VERSION ""

NS_ :

BS_:

BU_: VCM TCM ECM EBS ACM

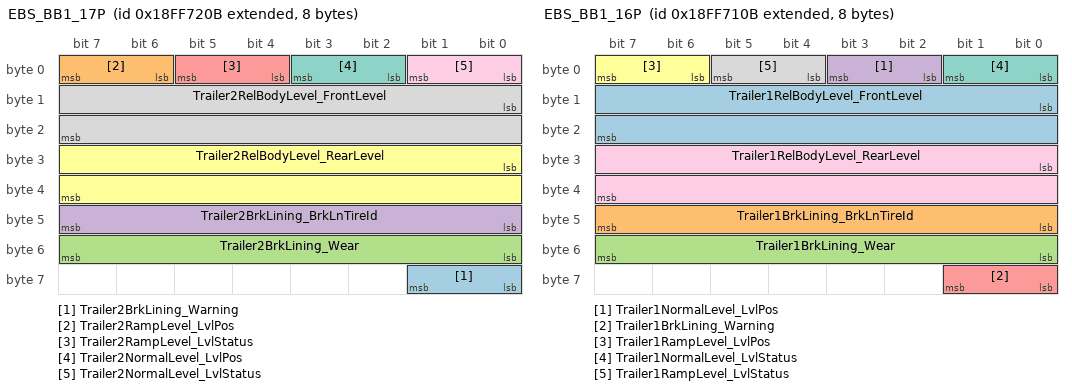
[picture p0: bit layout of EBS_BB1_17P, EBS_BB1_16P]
BO_ 2566877707 EBS_BB1_17P: 8 EBS
 SG_ Trailer2BrkLining_Warning : 56|2@1+ (1,0) [0|0] ""  VCM
 SG_ Trailer2RampLevel_LvlPos : 6|2@1+ (1,0) [0|0] ""  VCM
 SG_ Trailer2BrkLining_Wear : 48|8@1+ (0.4,0) [0|102] "Percent"  VCM
 SG_ Trailer2BrkLining_BrkLnTireId : 40|8@1+ (1,0) [0|255] "NotApplicable"  VCM
 SG_ Trailer2RampLevel_LvlStatus : 4|2@1+ (1,0) [0|0] ""  VCM
 SG_ Trailer2RelBodyLevel_RearLevel : 24|16@1+ (1,-32000) [-32000|33535] "mm"  VCM
 SG_ Trailer2NormalLevel_LvlPos : 2|2@1+ (1,0) [0|0] ""  VCM
 SG_ Trailer2RelBodyLevel_FrontLevel : 8|16@1+ (1,-32000) [-32000|33535] "mm"  VCM
 SG_ Trailer2NormalLevel_LvlStatus : 0|2@1+ (1,0) [0|0] ""  VCM

BO_ 2566877451 EBS_BB1_16P: 8 EBS
 SG_ Trailer1RelBodyLevel_FrontLevel : 8|16@1+ (1,-32000) [-32000|33535] "mm"  VCM
 SG_ Trailer1BrkLining_BrkLnTireId : 40|8@1+ (1,0) [0|255] "NotApplicable"  VCM
 SG_ Trailer1BrkLining_Wear : 48|8@1+ (0.4,0) [0|102] "Percent"  VCM
 SG_ Trailer1NormalLevel_LvlPos : 2|2@1+ (1,0) [0|0] ""  VCM
 SG_ Trailer1BrkLining_Warning : 56|2@1+ (1,0) [0|0] ""  VCM
 SG_ Trailer1RampLevel_LvlPos : 6|2@1+ (1,0) [0|0] ""  VCM
 SG_ Trailer1NormalLevel_LvlStatus : 0|2@1+ (1,0) [0|0] ""  VCM
 SG_ Trailer1RampLevel_LvlStatus : 4|2@1+ (1,0) [0|0] ""  VCM
 SG_ Trailer1RelBodyLevel_RearLevel : 24|16@1+ (1,-32000) [-32000|33535] "mm"  VCM

BO_ 2566894859 EBS_BB1_15P: 17 EBS
 SG_ Trailer5VIN : 0|136@1+ (1,0) [0|0] ""  VCM

BO_ 2566894603 EBS_BB1_14P: 17 EBS
 SG_ Trailer4VIN : 0|136@1+ (1,0) [0|0] ""  VCM

BO_ 2566894347 EBS_BB1_13P: 17 EBS
 SG_ Trailer3VIN : 0|136@1+ (1,0) [0|0] ""  VCM

BO_ 2566894091 EBS_BB1_12P: 17 EBS
 SG_ Trailer2VIN : 0|136@1+ (1,0) [0|0] ""  VCM

BO_ 2566893835 EBS_BB1_11P: 17 EBS
 SG_ Trailer1VIN : 0|136@1+ (1,0) [0|0] ""  VCM

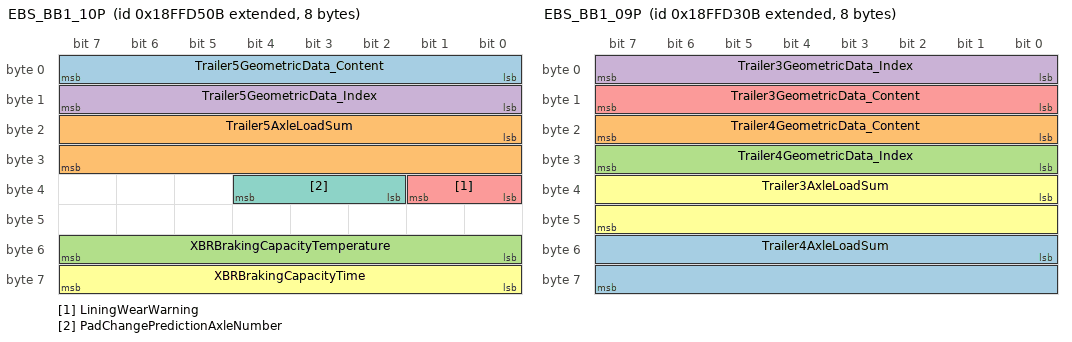
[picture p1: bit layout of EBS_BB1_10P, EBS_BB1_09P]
BO_ 2566903051 EBS_BB1_10P: 8 EBS
 SG_ Trailer5GeometricData_Content : 0|8@1+ (1,0) [0|255] ""  VCM
 SG_ Trailer5AxleLoadSum : 16|16@1+ (2,0) [0|131070] "kg"  VCM,TCM
 SG_ XBRBrakingCapacityTemperature : 48|8@1+ (0.4,0) [0|102] "Percent"  TCM,ECM,VCM
 SG_ Trailer5GeometricData_Index : 8|8@1+ (1,0) [0|0] ""  VCM
 SG_ LiningWearWarning : 32|2@1+ (1,0) [0|0] ""  VCM
 SG_ XBRBrakingCapacityTime : 56|8@1+ (1,0) [0|255] "s"  VCM,ECM,TCM
 SG_ PadChangePredictionAxleNumber : 34|3@1+ (1,0) [0|0] ""  VCM

BO_ 2566902539 EBS_BB1_09P: 8 EBS
 SG_ Trailer4AxleLoadSum : 48|16@1+ (2,0) [0|131070] "kg"  TCM,VCM
 SG_ Trailer4GeometricData_Content : 16|8@1+ (1,0) [0|255] ""  VCM
 SG_ Trailer4GeometricData_Index : 24|8@1+ (1,0) [0|0] ""  VCM
 SG_ Trailer3GeometricData_Index : 0|8@1+ (1,0) [0|0] ""  VCM
 SG_ Trailer3GeometricData_Content : 8|8@1+ (1,0) [0|255] ""  VCM
 SG_ Trailer3AxleLoadSum : 32|16@1+ (2,0) [0|131070] "kg"  VCM,TCM

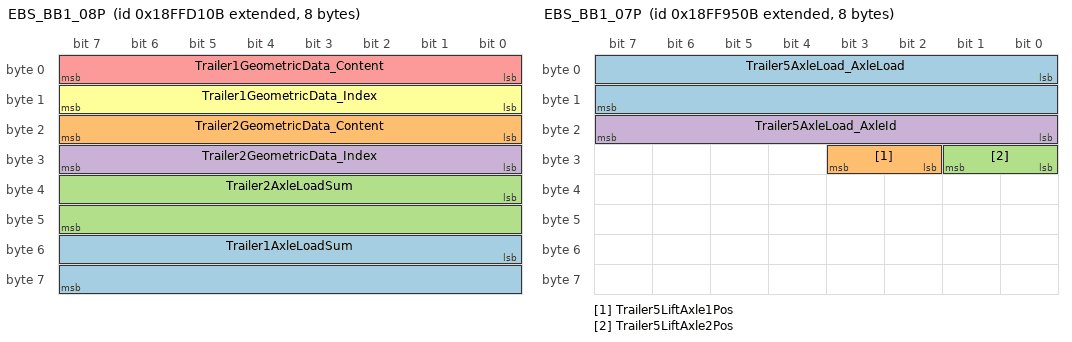
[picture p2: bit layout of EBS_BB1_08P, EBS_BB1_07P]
BO_ 2566902027 EBS_BB1_08P: 8 EBS
 SG_ Trailer1AxleLoadSum : 48|16@1+ (2,0) [0|131070] "kg"  TCM,VCM
 SG_ Trailer2GeometricData_Content : 16|8@1+ (1,0) [0|255] ""  VCM
 SG_ Trailer2AxleLoadSum : 32|16@1+ (2,0) [0|131070] "kg"  VCM,TCM
 SG_ Trailer2GeometricData_Index : 24|8@1+ (1,0) [0|0] ""  VCM
 SG_ Trailer1GeometricData_Content : 0|8@1+ (1,0) [0|255] ""  VCM
 SG_ Trailer1GeometricData_Index : 8|8@1+ (1,0) [0|0] ""  VCM

BO_ 2566886667 EBS_BB1_07P: 8 EBS
 SG_ Trailer5AxleLoad_AxleLoad : 0|16@1+ (0.5,0) [0|32767.5] "kg"  TCM,VCM
 SG_ Trailer5LiftAxle1Pos : 26|2@1+ (1,0) [0|0] ""  VCM
 SG_ Trailer5LiftAxle2Pos : 24|2@1+ (1,0) [0|0] ""  VCM
 SG_ Trailer5AxleLoad_AxleId : 16|8@1+ (1,0) [0|255] "NotApplicable"  VCM,TCM

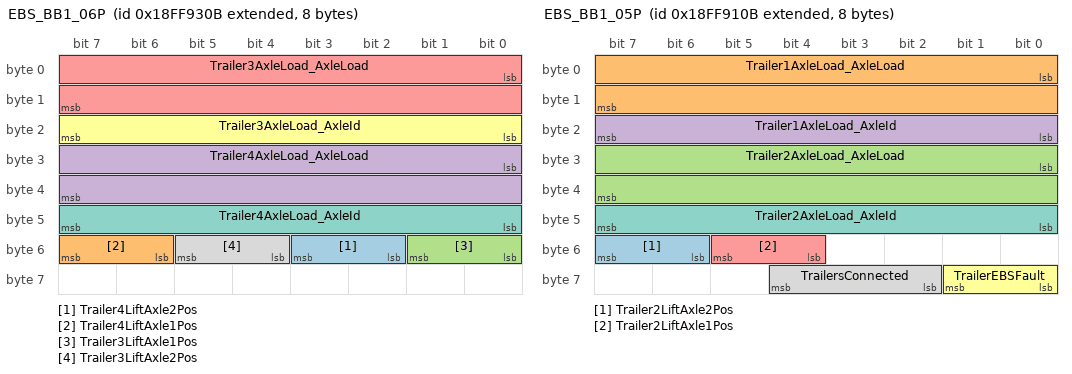
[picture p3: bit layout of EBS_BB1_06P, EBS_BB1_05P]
BO_ 2566886155 EBS_BB1_06P: 8 EBS
 SG_ Trailer4LiftAxle2Pos : 50|2@1+ (1,0) [0|0] ""  VCM
 SG_ Trailer4LiftAxle1Pos : 54|2@1+ (1,0) [0|0] ""  VCM
 SG_ Trailer3LiftAxle1Pos : 48|2@1+ (1,0) [0|0] ""  VCM
 SG_ Trailer4AxleLoad_AxleLoad : 24|16@1+ (0.5,0) [0|32767.5] "kg"  VCM,TCM
 SG_ Trailer3AxleLoad_AxleLoad : 0|16@1+ (0.5,0) [0|32767.5] "kg"  TCM,VCM
 SG_ Trailer3AxleLoad_AxleId : 16|8@1+ (1,0) [0|255] "NotApplicable"  TCM,VCM
 SG_ Trailer4AxleLoad_AxleId : 40|8@1+ (1,0) [0|255] "NotApplicable"  VCM,TCM
 SG_ Trailer3LiftAxle2Pos : 52|2@1+ (1,0) [0|0] ""  VCM

BO_ 2566885643 EBS_BB1_05P: 8 EBS
 SG_ Trailer2LiftAxle2Pos : 54|2@1+ (1,0) [0|0] ""  VCM
 SG_ Trailer1AxleLoad_AxleLoad : 0|16@1+ (0.5,0) [0|32767.5] "kg"  VCM,TCM
 SG_ Trailer2AxleLoad_AxleLoad : 24|16@1+ (0.5,0) [0|32767.5] "kg"  VCM,TCM
 SG_ Trailer1AxleLoad_AxleId : 16|8@1+ (1,0) [0|255] "NotApplicable"  VCM,TCM
 SG_ Trailer2LiftAxle1Pos : 52|2@1+ (1,0) [0|0] ""  VCM
 SG_ TrailerEBSFault : 56|2@1+ (1,0) [0|0] ""  VCM
 SG_ Trailer2AxleLoad_AxleId : 40|8@1+ (1,0) [0|255] "NotApplicable"  VCM,TCM
 SG_ TrailersConnected : 58|3@1+ (1,0) [0|7] "Count"  TCM,VCM

BO_ 2566906635 EBS_BB1_04P: 8 EBS
 SG_ PadChgPredictionLastPadChg : 32|32@1+ (1,0) [0|4294967295] "km"  VCM
 SG_ PredictedMileageOfNextPadChg : 0|32@1+ (1,0) [0|4294967295] "km"  VCM

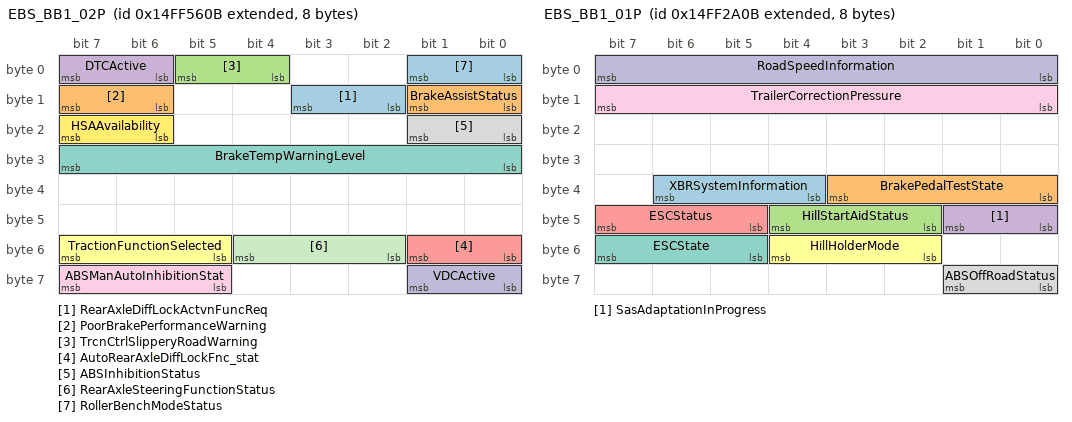
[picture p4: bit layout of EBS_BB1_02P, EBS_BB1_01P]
BO_ 2499761675 EBS_BB1_02P: 8 EBS
 SG_ RearAxleDiffLockActvnFuncReq : 10|2@1+ (1,0) [0|0] ""  VCM
 SG_ PoorBrakePerformanceWarning : 14|2@1+ (1,0) [0|0] ""  VCM
 SG_ TrcnCtrlSlipperyRoadWarning : 4|2@1+ (1,0) [0|0] ""  VCM
 SG_ DTCActive : 6|2@1+ (1,0) [0|0] ""  VCM
 SG_ AutoRearAxleDiffLockFnc_stat : 48|2@1+ (1,0) [0|0] ""  VCM
 SG_ TractionFunctionSelected : 53|3@1+ (1,0) [0|0] ""  VCM
 SG_ BrakeTempWarningLevel : 24|8@1+ (1,0) [0|255] "Percent"  VCM,ECM,TCM
 SG_ ABSInhibitionStatus : 16|2@1+ (1,0) [0|0] ""  TCM,VCM
 SG_ ABSManAutoInhibitionStat : 61|3@1+ (1,0) [0|0] ""  VCM
 SG_ VDCActive : 56|2@1+ (1,0) [0|0] ""  VCM
 SG_ RearAxleSteeringFunctionStatus : 50|3@1+ (1,0) [0|0] ""  VCM
 SG_ HSAAvailability : 22|2@1+ (1,0) [0|0] ""  TCM,VCM
 SG_ RollerBenchModeStatus : 0|2@1+ (1,0) [0|0] ""  VCM
 SG_ BrakeAssistStatus : 8|2@1+ (1,0) [0|0] ""  VCM

BO_ 2499750411 EBS_BB1_01P: 8 EBS
 SG_ XBRSystemInformation : 36|3@1+ (1,0) [0|0] ""  TCM,ECM,VCM
 SG_ BrakePedalTestState : 32|4@1+ (1,0) [0|0] ""  VCM
 SG_ HillStartAidStatus : 42|3@1+ (1,0) [0|0] ""  VCM
 SG_ SasAdaptationInProgress : 40|2@1+ (1,0) [0|0] ""  VCM
 SG_ ESCStatus : 45|3@1+ (1,0) [0|0] ""  VCM
 SG_ HillHolderMode : 50|3@1+ (1,0) [0|0] ""  TCM
 SG_ ESCState : 53|3@1+ (1,0) [0|0] ""  VCM
 SG_ ABSOffRoadStatus : 56|2@1+ (1,0) [0|0] ""  TCM,VCM
 SG_ TrailerCorrectionPressure : 8|8@1+ (0.05,-1.5) [-1.5|11.25] "Bar"  VCM
 SG_ RoadSpeedInformation : 0|8@1+ (0.805,0) [0|205.275] "Km_per_h"  VCM

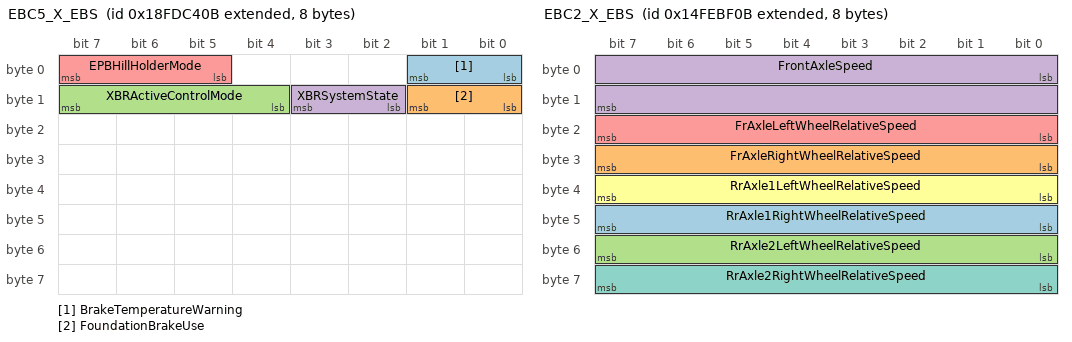
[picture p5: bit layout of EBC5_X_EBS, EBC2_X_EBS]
BO_ 2566767627 EBC5_X_EBS: 8 EBS
 SG_ BrakeTemperatureWarning : 0|2@1+ (1,0) [0|0] ""  VCM
 SG_ FoundationBrakeUse : 8|2@1+ (1,0) [0|0] ""  ECM,TCM,VCM
 SG_ XBRActiveControlMode : 12|4@1+ (1,0) [0|0] ""  TCM,ECM,VCM
 SG_ XBRSystemState : 10|2@1+ (1,0) [0|0] ""  ECM,TCM
 SG_ EPBHillHolderMode : 5|3@1+ (1,0) [0|0] ""  VCM,TCM

BO_ 2499723019 EBC2_X_EBS: 8 EBS
 SG_ RrAxle1RightWheelRelativeSpeed : 40|8@1+ (0.0625,-7.8125) [-7.8125|8.125] "Km_per_h"  TCM,VCM
 SG_ FrAxleRightWheelRelativeSpeed : 24|8@1+ (0.0625,-7.8125) [-7.8125|8.125] "Km_per_h"  VCM,TCM
 SG_ RrAxle2LeftWheelRelativeSpeed : 48|8@1+ (0.0625,-7.8125) [-7.8125|8.125] "Km_per_h"  TCM,VCM
 SG_ FrontAxleSpeed : 0|16@1+ (0.00390625,0) [0|255.99609375] "Km_per_h"  VCM,ECM,TCM
 SG_ FrAxleLeftWheelRelativeSpeed : 16|8@1+ (0.0625,-7.8125) [-7.8125|8.125] "Km_per_h"  TCM,VCM
 SG_ RrAxle1LeftWheelRelativeSpeed : 32|8@1+ (0.0625,-7.8125) [-7.8125|8.125] "Km_per_h"  TCM,VCM
 SG_ RrAxle2RightWheelRelativeSpeed : 56|8@1+ (0.0625,-7.8125) [-7.8125|8.125] "Km_per_h"  VCM,TCM

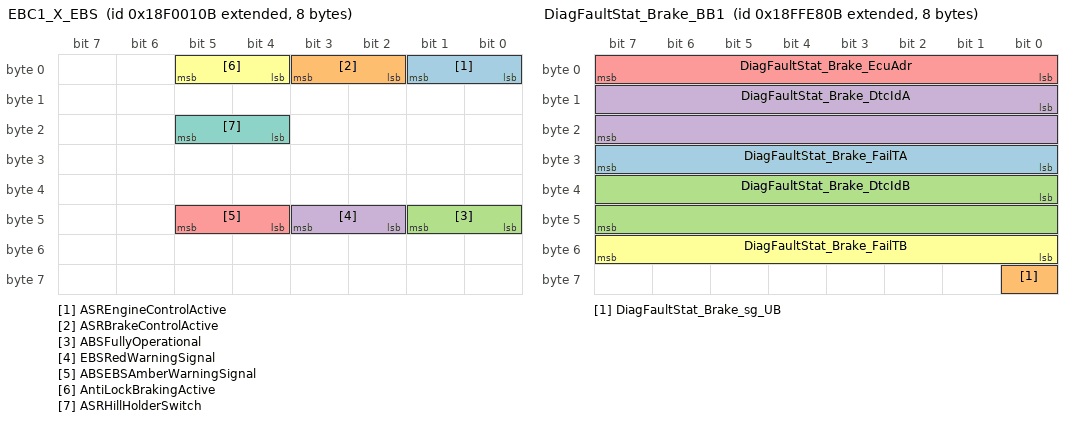
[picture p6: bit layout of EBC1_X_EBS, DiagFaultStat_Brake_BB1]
BO_ 2565865739 EBC1_X_EBS: 8 EBS
 SG_ ASREngineControlActive : 0|2@1+ (1,0) [0|0] ""  ECM,VCM,TCM
 SG_ ASRBrakeControlActive : 2|2@1+ (1,0) [0|0] ""  VCM,TCM,ECM
 SG_ ABSFullyOperational : 40|2@1+ (1,0) [0|0] ""  ECM,TCM,VCM
 SG_ EBSRedWarningSignal : 42|2@1+ (1,0) [0|0] ""  VCM
 SG_ ABSEBSAmberWarningSignal : 44|2@1+ (1,0) [0|0] ""  VCM
 SG_ AntiLockBrakingActive : 4|2@1+ (1,0) [0|0] ""  TCM,ECM
 SG_ ASRHillHolderSwitch : 20|2@1+ (1,0) [0|0] ""  ECM,VCM

BO_ 2671964712 DiagUUDTRespMsg1_F2_28_C01: 8 EBS
 SG_ DiagUUDTRespSig_F2_28 : 0|64@1+ (1,0) [0|0] ""  VCM

BO_ 2671964689 DiagUUDTRespMsg1_F2_11_C01: 8 ACM
 SG_ DiagUUDTRespSig_F2_11 : 0|64@1+ (1,0) [0|0] ""  VCM

BO_ 2671834152 DiagRespMsgForIntTest_F4_28_C01: 8 EBS
 SG_ InternalTesterDiagSig_F4_28 : 0|64@1+ (1,0) [0|0] ""  VCM

BO_ 2671834129 DiagRespMsgForIntTest_F4_11_C01: 8 ACM
 SG_ InternalTesterDiagSig_F4_11 : 0|64@1+ (1,0) [0|0] ""  VCM

BO_ 2671782132 DiagReqMsgOfIntTest_28_F4_C01: 8 VCM
 SG_ InternalTesterDiagSig_28_F4 : 0|64@1+ (1,0) [0|0] ""  EBS

BO_ 2671776244 DiagReqMsgOfIntTest_11_F4_C01: 8 VCM
 SG_ InternalTesterDiagSig_11_F4 : 0|64@1+ (1,0) [0|0] ""  ACM

BO_ 2566907915 DiagFaultStat_Brake_BB1: 8 EBS
 SG_ DiagFaultStat_Brake_FailTA : 24|8@1+ (1,0) [0|255] ""  VCM
 SG_ DiagFaultStat_Brake_sg_UB : 56|1@1+ (1,0) [0|0] ""  VCM
 SG_ DiagFaultStat_Brake_DtcIdB : 32|16@1+ (1,0) [0|65535] ""  VCM
 SG_ DiagFaultStat_Brake_DtcIdA : 8|16@1+ (1,0) [0|65535] ""  VCM
 SG_ DiagFaultStat_Brake_EcuAdr : 0|8@1+ (1,0) [0|255] ""  VCM
 SG_ DiagFaultStat_Brake_FailTB : 48|8@1+ (1,0) [0|255] ""  VCM

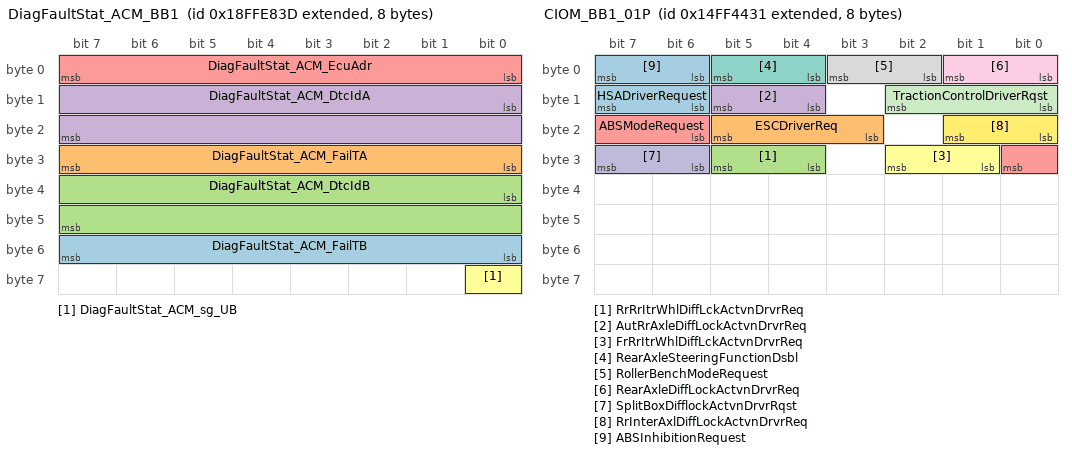
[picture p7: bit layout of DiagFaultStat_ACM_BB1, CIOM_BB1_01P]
BO_ 2566907965 DiagFaultStat_ACM_BB1: 8 ACM
 SG_ DiagFaultStat_ACM_FailTB : 48|8@1+ (1,0) [0|255] ""  VCM
 SG_ DiagFaultStat_ACM_FailTA : 24|8@1+ (1,0) [0|255] ""  VCM
 SG_ DiagFaultStat_ACM_DtcIdB : 32|16@1+ (1,0) [0|65535] ""  VCM
 SG_ DiagFaultStat_ACM_DtcIdA : 8|16@1+ (1,0) [0|65535] ""  VCM
 SG_ DiagFaultStat_ACM_EcuAdr : 0|8@1+ (1,0) [0|255] ""  VCM
 SG_ DiagFaultStat_ACM_sg_UB : 56|1@1+ (1,0) [0|0] ""  VCM

BO_ 2566749184 DPFC1_X_EMS: 8 ECM
 SG_ DPFC1_InhibDueServiceBrake : 22|2@1+ (1,0) [0|0] ""  TCM,VCM
 SG_ DPFC1_InhibVehSpdBelowAllwdSpd : 46|2@1+ (1,0) [0|0] ""  TCM,VCM
 SG_ DPFC1_ActiveRegeneratStatus : 10|2@1+ (1,0) [0|0] ""  VCM,TCM
 SG_ DPFC1_ExhaustSystHighTempLampCmd : 50|3@1+ (1,0) [0|0] ""  VCM,TCM
 SG_ DPFC1_InhibParkBrakeNotSet : 32|2@1+ (1,0) [0|0] ""  TCM,VCM
 SG_ DPFC1_InhibEnginNotWarmUp : 44|2@1+ (1,0) [0|0] ""  VCM,TCM
 SG_ DPFC1_InhibitStatus : 16|2@1+ (1,0) [0|0] ""  VCM,TCM
 SG_ DPFC1_ForcedStatus : 53|3@1+ (1,0) [0|0] ""  TCM,VCM
 SG_ DPFC1_PassiveRegenStatus : 8|2@1+ (1,0) [0|0] ""  TCM,VCM
 SG_ DPFC1_InhibTempSystemLock : 40|2@1+ (1,0) [0|0] ""  TCM,VCM
 SG_ DPFC1_InhibDueInhibSwitch : 18|2@1+ (1,0) [0|0] ""  VCM,TCM
 SG_ DPFC1_InhibPTOActive : 24|2@1+ (1,0) [0|0] ""  TCM,VCM
 SG_ DPFC1_AutoARInitConfig : 48|2@1+ (1,0) [0|0] ""  VCM,TCM
 SG_ DPFC1_InhibDueLowExhGasTemp : 34|2@1+ (1,0) [0|0] ""  VCM,TCM
 SG_ DPFC1_InhibSystemFaultAct : 36|2@1+ (1,0) [0|0] ""  VCM,TCM
 SG_ DPFC1_InhibDueSystemTimeout : 38|2@1+ (1,0) [0|0] ""  TCM,VCM
 SG_ DPFC1_InhibPermSystemLock : 42|2@1+ (1,0) [0|0] ""  TCM,VCM
 SG_ DPFC1_LampCommand : 0|3@1+ (1,0) [0|0] ""  VCM,TCM
 SG_ DPFC1_InhibVehSpdAboveAllwdSpd : 30|2@1+ (1,0) [0|0] ""  VCM,TCM
 SG_ DPFC1_InhibClutchDisengage : 20|2@1+ (1,0) [0|0] ""  VCM,TCM
 SG_ DPFC1_InhibAccPedalOffIdle : 26|2@1+ (1,0) [0|0] ""  TCM,VCM
 SG_ DPFC1_InhibOutOfNeutral : 28|2@1+ (1,0) [0|0] ""  VCM,TCM
 SG_ DPFC1_DPFStatus : 12|3@1+ (1,0) [0|0] ""  TCM,VCM

BO_ 2566834691 DM1_X_TECU: 202 TCM
 SG_ DiagnosticsFaultStat_DM1_TECU : 0|1616@1+ (1,0) [0|0] ""  VCM

BO_ 2566834688 DM1_X_EMS: 202 ECM
 SG_ DiagnosticsFaultStat_DM1_EMS : 0|1616@1+ (1,0) [0|0] ""  VCM

BO_ 2566834749 DM1_X_ACM: 202 ACM
 SG_ DiagnosticsFaultStat_DM1_ACM : 0|1616@1+ (1,0) [0|0] ""  VCM

BO_ 2566811659 CVW_X_EBS: 8 EBS
 SG_ PoweredVehicleWeight : 0|16@1+ (10,0) [0|655350] "kg"  VCM
 SG_ GrossCombinationVehicleWeight : 16|16@1+ (10,0) [0|655350] "kg"  VCM,TCM,ECM

BO_ 2499757105 CIOM_BB1_01P: 8 VCM
 SG_ HSADriverRequest : 14|2@1+ (1,0) [0|0] ""  EBS
 SG_ ESCDriverReq : 19|3@1+ (1,0) [0|0] ""  EBS
 SG_ RrRrItrWhlDiffLckActvnDrvrReq : 28|2@1+ (1,0) [0|0] ""  EBS
 SG_ AutRrAxleDiffLockActvnDrvrReq : 12|2@1+ (1,0) [0|0] ""  EBS
 SG_ ABSModeRequest : 22|3@1+ (1,0) [0|0] ""  EBS
 SG_ FrRrItrWhlDiffLckActvnDrvrReq : 25|2@1+ (1,0) [0|0] ""  EBS
 SG_ RearAxleSteeringFunctionDsbl : 4|2@1+ (1,0) [0|0] ""  EBS
 SG_ RollerBenchModeRequest : 2|2@1+ (1,0) [0|0] ""  EBS
 SG_ RearAxleDiffLockActvnDrvrReq : 0|2@1+ (1,0) [0|0] ""  EBS
 SG_ SplitBoxDifflockActvnDrvrRqst : 30|2@1+ (1,0) [0|0] ""  ECM,EBS,TCM
 SG_ TractionControlDriverRqst : 8|3@1+ (1,0) [0|0] ""  EBS
 SG_ RrInterAxlDiffLockActvnDrvrReq : 16|2@1+ (1,0) [0|0] ""  EBS
 SG_ ABSInhibitionRequest : 6|2@1+ (1,0) [0|0] ""  EBS

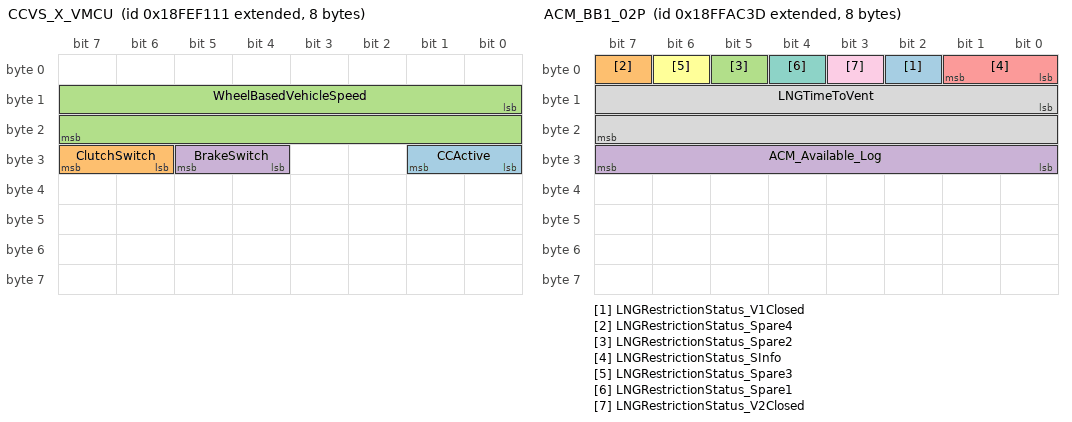
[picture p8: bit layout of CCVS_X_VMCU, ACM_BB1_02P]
BO_ 2566844689 CCVS_X_VMCU: 8 VCM
 SG_ CCActive : 24|2@1+ (1,0) [0|0] ""  TCM
 SG_ ClutchSwitch : 30|2@1+ (1,0) [0|0] ""  EBS
 SG_ WheelBasedVehicleSpeed : 8|16@1+ (0.00390625,0) [0|255.99609375] "Km_per_h"  EBS,ECM,TCM,ACM
 SG_ BrakeSwitch : 28|2@1+ (1,0) [0|0] ""  ECM,TCM

BO_ 2566748928 AT1S_X_EMS: 8 ECM
 SG_ DPFSootLevel : 0|8@1+ (1,0) [0|255] "Percent"  VCM

BO_ 2565869312 AT1OG1_X_EMS: 8 ECM
 SG_ Aftertreat1NOxConcOutlet : 0|16@1+ (0.05,-200) [-200|3076.75] "ppm"  VCM

BO_ 2566763008 AT1IMG_X_EMS: 8 ECM
 SG_ DPFPressureDiff : 32|16@1+ (0.1,0) [0|6553.5] "kPa"  VCM

BO_ 2566763520 AT1IG2_X_EMS: 8 ECM
 SG_ Aftertreatment1ExhaustTemp1 : 0|16@1+ (0.03125,-273) [-273|1774.96875] "DegreeC"  VCM

BO_ 2565869056 AT1IG1_X_EMS: 8 ECM
 SG_ EngineExhaust1NOx1 : 0|16@1+ (0.05,-200) [-200|3076.75] "ppm"  VCM

BO_ 2566845713 AMB_X_VMCU: 8 VCM
 SG_ AmbientAirTemperature : 24|16@1+ (0.03125,-273) [-273|1774.96875] "DegreeC"  ACM,ECM,TCM,EBS

BO_ 2566827537 AIR1_X_VMCU: 8 VCM
 SG_ ServiceBrakeAirPrsCircuit1 : 16|8@1+ (8,0) [0|2040] "kPa"  ECM,ACM,TCM
 SG_ ServiceBrakeAirPrsCircuit2 : 24|8@1+ (8,0) [0|2040] "kPa"  ECM,TCM,ACM

BO_ 2566892605 ACM_BB1_02P: 8 ACM
 SG_ LNGRestrictionStatus_V1Closed : 2|1@1+ (1,0) [0|0] ""  VCM
 SG_ LNGRestrictionStatus_Spare4 : 7|1@1+ (1,0) [0|0] ""  VCM
 SG_ LNGRestrictionStatus_Spare2 : 5|1@1+ (1,0) [0|0] ""  VCM
 SG_ ACM_Available_Log : 24|8@1+ (1,0) [0|0] ""  VCM
 SG_ LNGRestrictionStatus_SInfo : 0|2@1+ (1,0) [0|0] ""  VCM
 SG_ LNGRestrictionStatus_Spare3 : 6|1@1+ (1,0) [0|0] ""  VCM
 SG_ LNGRestrictionStatus_Spare1 : 4|1@1+ (1,0) [0|0] ""  VCM
 SG_ LNGTimeToVent : 8|16@1+ (1,0) [0|65535] "min"  VCM
 SG_ LNGRestrictionStatus_V2Closed : 3|1@1+ (1,0) [0|0] ""  VCM

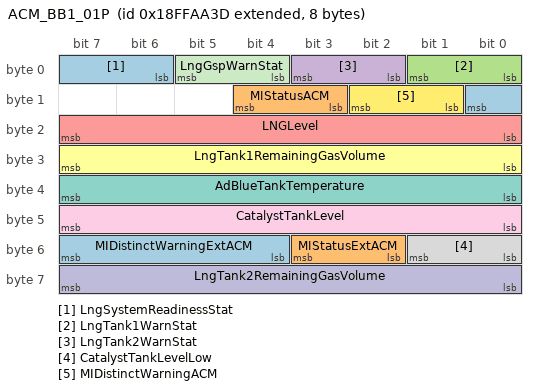
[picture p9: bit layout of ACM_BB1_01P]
BO_ 2566892093 ACM_BB1_01P: 8 ACM
 SG_ LngSystemReadinessStat : 6|3@1+ (1,0) [0|0] ""  VCM
 SG_ MIStatusACM : 11|2@1+ (1,0) [0|0] ""  VCM,ECM
 SG_ LngTank1WarnStat : 0|2@1+ (1,0) [0|0] ""  VCM
 SG_ LngTank2WarnStat : 2|2@1+ (1,0) [0|0] ""  VCM
 SG_ LNGLevel : 16|8@1+ (0.4,0) [0|102] "Percent"  VCM
 SG_ LngTank1RemainingGasVolume : 24|8@1+ (0.4,0) [0|102] "Percent"  VCM
 SG_ AdBlueTankTemperature : 32|8@1+ (1,-50) [-50|205] "DegreeC"  VCM
 SG_ CatalystTankLevelLow : 48|2@1+ (1,0) [0|0] ""  ECM,VCM
 SG_ CatalystTankLevel : 40|8@1+ (0.4,0) [0|102] "Percent"  VCM,ECM
 SG_ LngTank2RemainingGasVolume : 56|8@1+ (0.4,0) [0|102] "Percent"  VCM
 SG_ LngGspWarnStat : 4|2@1+ (1,0) [0|0] ""  VCM
 SG_ MIDistinctWarningACM : 9|2@1+ (1,0) [0|0] ""  VCM,ECM
 SG_ MIDistinctWarningExtACM : 52|4@1+ (1,0) [0|0] ""  ECM,VCM
 SG_ MIStatusExtACM : 50|2@1+ (1,0) [0|0] ""  VCM,ECM

BO_ 2499624448 A1SCREGT1_X_EMS: 8 ECM
 SG_ SCROutletTemp : 24|16@1+ (0.03125,-273) [-273|1774.96875] "DegreeC"  VCM
 SG_ SCRInletTemp : 0|16@1+ (0.03125,-273) [-273|1774.96875] "DegreeC"  VCM

CM_ SG_ 2566903051 Trailer5GeometricData_Content "254 Error ; 255 Not Available";
CM_ SG_ 2566902539 Trailer4GeometricData_Content "254 Error ; 255 Not Available";
CM_ SG_ 2566902539 Trailer3GeometricData_Content "254 Error ; 255 Not Available";
CM_ SG_ 2566902027 Trailer2GeometricData_Content "254 Error ; 255 Not Available";
CM_ SG_ 2566902027 Trailer1GeometricData_Content "254 Error ; 255 Not Available";
CM_ SG_ 2566886667 Trailer5AxleLoad_AxleLoad "65024 - 65279 Error ; 65280 - 65535 Not available";
CM_ SG_ 2566886155 Trailer4AxleLoad_AxleLoad "65024 - 65279 Error ; 65280 - 65535 Not available";
CM_ SG_ 2566886155 Trailer3AxleLoad_AxleLoad "65024 - 65279 Error ; 65280 - 65535 Not available";
CM_ SG_ 2566885643 Trailer1AxleLoad_AxleLoad "65024 - 65279 Error ; 65280 - 65535 Not available";
CM_ SG_ 2566885643 Trailer2AxleLoad_AxleLoad "65024 - 65279 Error ; 65280 - 65535 Not available";
CM_ BO_ 2566767627 "PGN 64964 Electronic Brake Controller 5";
CM_ BO_ 2499723019 "PGN 65215 Wheel Speed Information";
CM_ BO_ 2565865739 "PGN 61441 Electronic Brake Controller 1";
CM_ BO_ 2566749184 "PGN 64892 Diesel Particulate Filter Control 1";
CM_ BO_ 2566834691 "PGN 65226 Active Diagnostic Trouble Codes";
CM_ BO_ 2566834688 "PGN 65226 Active Diagnostic Trouble Codes";
CM_ BO_ 2566834749 "PGN 65226 Active Diagnostic Trouble Codes";
CM_ BO_ 2566811659 "PGN 64872 Gross Combination Vehicle Weight";
CM_ BO_ 2566844689 "PGN 65265 Cruise Control/Vehicle Speed";
CM_ BO_ 2566748928 "PGN 64891 Aftertreatment 1 Service";
CM_ BO_ 2565869312 "PGN 61455 Aftertreatment 1 Outlet Gas 1
Note: SAE recommended rate 50ms, but 500ms set due to current usage only for logging.";
CM_ BO_ 2566763008 "PGN 64946 Aftertreatment 1 Intermediate Gas";
CM_ BO_ 2566763520 "PGN 64948 Aftertreatment 1 Intake Gas 2";
CM_ BO_ 2565869056 "PGN 61454 Aftertreatment 1 Intake Gas 1
Note: SAE recommended rate 50ms, but 500ms set due to current usage only for logging.";
CM_ BO_ 2566845713 "PGN 65269 Ambient Conditions";
CM_ BO_ 2566827537 "PGN 65198 Air Supply Pressure, Sporadic because cyclic before gateway";
CM_ BO_ 2499624448 "PGN 64830 Aftertreatment 1 SCR Exhaust Gas Temperature 1";
BA_DEF_ BO_  "GenMsgStartDelayTime" INT 0 0;
BA_DEF_ BO_  "GenMsgDelayTime" INT 0 0;
BA_DEF_ BO_  "GenMsgNrOfRepetition" INT 0 0;
BA_DEF_ BO_  "GenMsgCycleTimeFast" INT 0 0;
BA_DEF_ BO_  "GenMsgCycleTime" INT 0 0;
BA_DEF_ BO_  "GenMsgSendType" ENUM  "Cyclic","NotUsed","NotUsed","NotUsed","NotUsed","NotUsed","NotUsed","IfActive","NoMsgSendType","NotUsed";
BA_DEF_ SG_  "GenSigStartValue" INT 0 0;
BA_DEF_ SG_  "GenSigCycleTimeActive" INT 0 0;
BA_DEF_ SG_  "GenSigCycleTime" INT 0 0;
BA_DEF_ SG_  "GenSigSendType" ENUM  "Cyclic","OnWrite","OnWriteWithRepetition","OnChange","OnChangeWithRepetition","IfActive","IfActiveWithRepetition","NoSigSendType","NotUsed","NotUsed","NotUsed","NotUsed","NotUsed";
BA_DEF_ BO_  "VFrameFormat" ENUM  "StandardCAN","ExtendedCAN","reserved","J1939PG","reserved","reserved","reserved","reserved","reserved","reserved","reserved","reserved","reserved","reserved","StandardCAN_FD","ExtendedCAN_FD";
BA_DEF_ BO_  "TpJ1939VarDlc" ENUM  "No","Yes";
BA_DEF_ SG_  "SigType" ENUM  "Default","Range","RangeSigned","ASCII","Discrete","Control","ReferencePGN","DTC","StringDelimiter","StringLength","StringLengthControl";
BA_DEF_ SG_  "SeToolVersion_SIGNAL" STRING ;
BA_DEF_ SG_  "SeToolUniqueID_SIGNAL" STRING ;
BA_DEF_ SG_  "SeToolOwnerSigGroup_SIGNAL" STRING ;
BA_DEF_ SG_  "SeToolOwnerSigGroupID_SIGNAL" STRING ;
BA_DEF_ SG_  "SeToolName_SIGNAL" STRING ;
BA_DEF_ SG_  "SeToolItemID_SIGNAL" STRING ;
BA_DEF_ SG_  "SeToolAncestorID_SIGNAL" STRING ;
BA_DEF_ SG_  "Platform_VMCU1_Sig" ENUM  "No","Yes";
BA_DEF_ SG_  "NeedsUpdateBit" ENUM  "No","Yes";
BA_DEF_ SG_  "GenSigMaxLatency" INT 0 65535;
BA_DEF_ SG_  "GenSigILSupport" ENUM  "Yes","No";
BA_DEF_ BO_  "GenMsgILSupport" ENUM  "No","Yes";
BA_DEF_ SG_  "E2EProfile" STRING ;
BA_DEF_ SG_  "E2EDataLength" INT 0 65535;
BA_DEF_ SG_  "E2EDataId" INT 0 65535;
BA_DEF_ BO_  "DiagUUDTResponse" ENUM  "No","Yes";
BA_DEF_ BO_  "DiagState" ENUM  "No","Yes";
BA_DEF_ BO_  "DiagResponse" ENUM  "No","Yes";
BA_DEF_ BO_  "DiagRequest" ENUM  "No","Yes";
BA_DEF_ BO_  "DiagConnection" HEX 0 65535;
BA_DEF_ BO_  "CanTpFcFrameId" HEX 0 2147483647;
BA_DEF_ BO_  "CanTpBs" INT 0 255;
BA_DEF_REL_ BU_SG_REL_  "GenSigTimeoutTime" INT 0 65535;
BA_DEF_REL_ BU_SG_REL_  "GenSigFirstTimeoutTime" INT 0 65535;
BA_DEF_DEF_  "GenMsgStartDelayTime" 0;
BA_DEF_DEF_  "GenMsgDelayTime" 0;
BA_DEF_DEF_  "GenMsgNrOfRepetition" 0;
BA_DEF_DEF_  "GenMsgCycleTimeFast" 0;
BA_DEF_DEF_  "GenMsgCycleTime" 0;
BA_DEF_DEF_  "GenMsgSendType" "Cyclic";
BA_DEF_DEF_  "GenSigStartValue" 0;
BA_DEF_DEF_  "GenSigCycleTimeActive" 0;
BA_DEF_DEF_  "GenSigCycleTime" 0;
BA_DEF_DEF_  "GenSigSendType" "Cyclic";
BA_DEF_DEF_  "VFrameFormat" "ExtendedCAN";
BA_DEF_DEF_  "TpJ1939VarDlc" "No";
BA_DEF_DEF_  "SigType" "Default";
BA_DEF_DEF_  "SeToolVersion_SIGNAL" "";
BA_DEF_DEF_  "SeToolUniqueID_SIGNAL" "";
BA_DEF_DEF_  "SeToolOwnerSigGroup_SIGNAL" "";
BA_DEF_DEF_  "SeToolOwnerSigGroupID_SIGNAL" "";
BA_DEF_DEF_  "SeToolName_SIGNAL" "";
BA_DEF_DEF_  "SeToolItemID_SIGNAL" "";
BA_DEF_DEF_  "SeToolAncestorID_SIGNAL" "";
BA_DEF_DEF_  "Platform_VMCU1_Sig" "No";
BA_DEF_DEF_  "NeedsUpdateBit" "No";
BA_DEF_DEF_  "GenSigMaxLatency" 0;
BA_DEF_DEF_  "GenSigILSupport" "Yes";
BA_DEF_DEF_  "GenMsgILSupport" "Yes";
BA_DEF_DEF_  "E2EProfile" "none";
BA_DEF_DEF_  "E2EDataLength" 0;
BA_DEF_DEF_  "E2EDataId" 0;
BA_DEF_DEF_  "DiagUUDTResponse" "No";
BA_DEF_DEF_  "DiagState" "No";
BA_DEF_DEF_  "DiagResponse" "No";
BA_DEF_DEF_  "DiagRequest" "No";
BA_DEF_DEF_  "DiagConnection" 0;
BA_DEF_DEF_  "CanTpFcFrameId" 2147483647;
BA_DEF_DEF_  "CanTpBs" 255;
BA_DEF_DEF_REL_ "GenSigTimeoutTime" 0;
BA_DEF_DEF_REL_ "GenSigFirstTimeoutTime" 0;
BA_ "GenMsgCycleTime" BO_ 2566877707 100;
BA_ "GenMsgStartDelayTime" BO_ 2566877707 15;
BA_ "VFrameFormat" BO_ 2566877707 3;
BA_ "GenMsgCycleTime" BO_ 2566877451 100;
BA_ "GenMsgStartDelayTime" BO_ 2566877451 80;
BA_ "VFrameFormat" BO_ 2566877451 3;
BA_ "GenMsgCycleTime" BO_ 2566894859 10000;
BA_ "GenMsgStartDelayTime" BO_ 2566894859 2040;
BA_ "VFrameFormat" BO_ 2566894859 3;
BA_ "GenMsgCycleTime" BO_ 2566894603 10000;
BA_ "GenMsgStartDelayTime" BO_ 2566894603 1530;
BA_ "VFrameFormat" BO_ 2566894603 3;
BA_ "GenMsgCycleTime" BO_ 2566894347 10000;
BA_ "GenMsgStartDelayTime" BO_ 2566894347 1020;
BA_ "VFrameFormat" BO_ 2566894347 3;
BA_ "GenMsgCycleTime" BO_ 2566894091 10000;
BA_ "GenMsgStartDelayTime" BO_ 2566894091 510;
BA_ "VFrameFormat" BO_ 2566894091 3;
BA_ "GenMsgCycleTime" BO_ 2566893835 10000;
BA_ "GenMsgStartDelayTime" BO_ 2566893835 100;
BA_ "VFrameFormat" BO_ 2566893835 3;
BA_ "GenMsgCycleTime" BO_ 2566903051 1000;
BA_ "GenMsgStartDelayTime" BO_ 2566903051 360;
BA_ "VFrameFormat" BO_ 2566903051 3;
BA_ "GenMsgCycleTime" BO_ 2566902539 1000;
BA_ "GenMsgStartDelayTime" BO_ 2566902539 265;
BA_ "VFrameFormat" BO_ 2566902539 3;
BA_ "GenMsgCycleTime" BO_ 2566902027 1000;
BA_ "GenMsgStartDelayTime" BO_ 2566902027 170;
BA_ "VFrameFormat" BO_ 2566902027 3;
BA_ "GenMsgCycleTime" BO_ 2566886667 100;
BA_ "GenMsgStartDelayTime" BO_ 2566886667 50;
BA_ "VFrameFormat" BO_ 2566886667 3;
BA_ "GenMsgCycleTime" BO_ 2566886155 100;
BA_ "GenMsgStartDelayTime" BO_ 2566886155 45;
BA_ "VFrameFormat" BO_ 2566886155 3;
BA_ "GenMsgCycleTime" BO_ 2566885643 100;
BA_ "GenMsgStartDelayTime" BO_ 2566885643 70;
BA_ "VFrameFormat" BO_ 2566885643 3;
BA_ "GenMsgCycleTime" BO_ 2566906635 2000;
BA_ "GenMsgStartDelayTime" BO_ 2566906635 555;
BA_ "VFrameFormat" BO_ 2566906635 3;
BA_ "GenMsgCycleTime" BO_ 2499761675 40;
BA_ "GenMsgStartDelayTime" BO_ 2499761675 10;
BA_ "VFrameFormat" BO_ 2499761675 3;
BA_ "GenMsgCycleTime" BO_ 2499750411 50;
BA_ "GenMsgStartDelayTime" BO_ 2499750411 15;
BA_ "VFrameFormat" BO_ 2499750411 3;
BA_ "GenMsgCycleTime" BO_ 2566767627 100;
BA_ "GenMsgStartDelayTime" BO_ 2566767627 35;
BA_ "VFrameFormat" BO_ 2566767627 3;
BA_ "GenMsgCycleTime" BO_ 2499723019 40;
BA_ "GenMsgStartDelayTime" BO_ 2499723019 25;
BA_ "VFrameFormat" BO_ 2499723019 3;
BA_ "GenMsgCycleTime" BO_ 2565865739 100;
BA_ "GenMsgStartDelayTime" BO_ 2565865739 30;
BA_ "VFrameFormat" BO_ 2565865739 3;
BA_ "DiagConnection" BO_ 2671964712 61992;
BA_ "DiagUUDTResponse" BO_ 2671964712 1;
BA_ "GenMsgILSupport" BO_ 2671964712 0;
BA_ "GenMsgSendType" BO_ 2671964712 8;
BA_ "VFrameFormat" BO_ 2671964712 3;
BA_ "DiagConnection" BO_ 2671964689 61969;
BA_ "DiagUUDTResponse" BO_ 2671964689 1;
BA_ "GenMsgILSupport" BO_ 2671964689 0;
BA_ "GenMsgSendType" BO_ 2671964689 8;
BA_ "VFrameFormat" BO_ 2671964689 3;
BA_ "DiagConnection" BO_ 2671834152 62504;
BA_ "DiagResponse" BO_ 2671834152 1;
BA_ "GenMsgILSupport" BO_ 2671834152 0;
BA_ "GenMsgSendType" BO_ 2671834152 8;
BA_ "VFrameFormat" BO_ 2671834152 3;
BA_ "DiagConnection" BO_ 2671834129 62481;
BA_ "DiagResponse" BO_ 2671834129 1;
BA_ "GenMsgILSupport" BO_ 2671834129 0;
BA_ "GenMsgSendType" BO_ 2671834129 8;
BA_ "VFrameFormat" BO_ 2671834129 3;
BA_ "DiagConnection" BO_ 2671782132 62504;
BA_ "DiagRequest" BO_ 2671782132 1;
BA_ "GenMsgILSupport" BO_ 2671782132 0;
BA_ "GenMsgSendType" BO_ 2671782132 8;
BA_ "VFrameFormat" BO_ 2671782132 3;
BA_ "DiagConnection" BO_ 2671776244 62481;
BA_ "DiagRequest" BO_ 2671776244 1;
BA_ "GenMsgILSupport" BO_ 2671776244 0;
BA_ "GenMsgSendType" BO_ 2671776244 8;
BA_ "VFrameFormat" BO_ 2671776244 3;
BA_ "GenMsgCycleTime" BO_ 2566907915 1000;
BA_ "GenMsgDelayTime" BO_ 2566907915 85;
BA_ "GenMsgStartDelayTime" BO_ 2566907915 85;
BA_ "VFrameFormat" BO_ 2566907915 3;
BA_ "GenMsgCycleTime" BO_ 2566907965 1000;
BA_ "GenMsgDelayTime" BO_ 2566907965 85;
BA_ "GenMsgStartDelayTime" BO_ 2566907965 5;
BA_ "VFrameFormat" BO_ 2566907965 3;
BA_ "GenMsgCycleTime" BO_ 2566749184 1000;
BA_ "GenMsgDelayTime" BO_ 2566749184 100;
BA_ "GenMsgStartDelayTime" BO_ 2566749184 335;
BA_ "VFrameFormat" BO_ 2566749184 3;
BA_ "TpJ1939VarDlc" BO_ 2566834691 1;
BA_ "GenMsgCycleTime" BO_ 2566834691 1000;
BA_ "GenMsgStartDelayTime" BO_ 2566834691 30;
BA_ "VFrameFormat" BO_ 2566834691 3;
BA_ "TpJ1939VarDlc" BO_ 2566834688 1;
BA_ "GenMsgCycleTime" BO_ 2566834688 1000;
BA_ "GenMsgStartDelayTime" BO_ 2566834688 240;
BA_ "VFrameFormat" BO_ 2566834688 3;
BA_ "TpJ1939VarDlc" BO_ 2566834749 1;
BA_ "GenMsgCycleTime" BO_ 2566834749 1000;
BA_ "GenMsgStartDelayTime" BO_ 2566834749 25;
BA_ "VFrameFormat" BO_ 2566834749 3;
BA_ "GenMsgCycleTime" BO_ 2566811659 2000;
BA_ "GenMsgStartDelayTime" BO_ 2566811659 475;
BA_ "VFrameFormat" BO_ 2566811659 3;
BA_ "GenMsgCycleTime" BO_ 2499757105 50;
BA_ "GenMsgStartDelayTime" BO_ 2499757105 5;
BA_ "VFrameFormat" BO_ 2499757105 3;
BA_ "GenMsgCycleTime" BO_ 2566844689 100;
BA_ "GenMsgStartDelayTime" BO_ 2566844689 5;
BA_ "VFrameFormat" BO_ 2566844689 3;
BA_ "GenMsgCycleTime" BO_ 2566748928 1000;
BA_ "GenMsgStartDelayTime" BO_ 2566748928 145;
BA_ "VFrameFormat" BO_ 2566748928 3;
BA_ "GenMsgCycleTime" BO_ 2565869312 500;
BA_ "GenMsgStartDelayTime" BO_ 2565869312 70;
BA_ "VFrameFormat" BO_ 2565869312 3;
BA_ "GenMsgCycleTime" BO_ 2566763008 500;
BA_ "GenMsgStartDelayTime" BO_ 2566763008 430;
BA_ "VFrameFormat" BO_ 2566763008 3;
BA_ "GenMsgCycleTime" BO_ 2566763520 500;
BA_ "GenMsgStartDelayTime" BO_ 2566763520 315;
BA_ "VFrameFormat" BO_ 2566763520 3;
BA_ "GenMsgCycleTime" BO_ 2565869056 500;
BA_ "GenMsgStartDelayTime" BO_ 2565869056 220;
BA_ "VFrameFormat" BO_ 2565869056 3;
BA_ "GenMsgCycleTime" BO_ 2566845713 1000;
BA_ "GenMsgStartDelayTime" BO_ 2566845713 410;
BA_ "VFrameFormat" BO_ 2566845713 3;
BA_ "GenMsgCycleTime" BO_ 2566827537 1000;
BA_ "GenMsgStartDelayTime" BO_ 2566827537 5;
BA_ "VFrameFormat" BO_ 2566827537 3;
BA_ "GenMsgCycleTime" BO_ 2566892605 1000;
BA_ "GenMsgStartDelayTime" BO_ 2566892605 50;
BA_ "VFrameFormat" BO_ 2566892605 3;
BA_ "GenMsgCycleTime" BO_ 2566892093 1000;
BA_ "GenMsgStartDelayTime" BO_ 2566892093 10;
BA_ "VFrameFormat" BO_ 2566892093 3;
BA_ "GenMsgCycleTime" BO_ 2499624448 500;
BA_ "GenMsgStartDelayTime" BO_ 2499624448 105;
BA_ "VFrameFormat" BO_ 2499624448 3;
BA_ "GenSigCycleTime" SG_ 2566877707 Trailer2BrkLining_Warning 100;
BA_ "GenSigCycleTimeActive" SG_ 2566877707 Trailer2BrkLining_Warning 100;
BA_ "GenSigStartValue" SG_ 2566877707 Trailer2BrkLining_Warning 3;
BA_ "GenSigCycleTime" SG_ 2566877707 Trailer2RampLevel_LvlPos 100;
BA_ "GenSigCycleTimeActive" SG_ 2566877707 Trailer2RampLevel_LvlPos 100;
BA_ "GenSigStartValue" SG_ 2566877707 Trailer2RampLevel_LvlPos 3;
BA_ "GenSigCycleTime" SG_ 2566877707 Trailer2BrkLining_Wear 100;
BA_ "GenSigCycleTimeActive" SG_ 2566877707 Trailer2BrkLining_Wear 100;
BA_ "GenSigStartValue" SG_ 2566877707 Trailer2BrkLining_Wear 255;
BA_ "GenSigCycleTime" SG_ 2566877707 Trailer2BrkLining_BrkLnTireId 100;
BA_ "GenSigCycleTimeActive" SG_ 2566877707 Trailer2BrkLining_BrkLnTireId 100;
BA_ "GenSigStartValue" SG_ 2566877707 Trailer2BrkLining_BrkLnTireId 255;
BA_ "GenSigCycleTime" SG_ 2566877707 Trailer2RampLevel_LvlStatus 100;
BA_ "GenSigCycleTimeActive" SG_ 2566877707 Trailer2RampLevel_LvlStatus 100;
BA_ "GenSigStartValue" SG_ 2566877707 Trailer2RampLevel_LvlStatus 3;
BA_ "GenSigCycleTime" SG_ 2566877707 Trailer2RelBodyLevel_RearLevel 100;
BA_ "GenSigCycleTimeActive" SG_ 2566877707 Trailer2RelBodyLevel_RearLevel 100;
BA_ "GenSigStartValue" SG_ 2566877707 Trailer2RelBodyLevel_RearLevel 65535;
BA_ "GenSigCycleTime" SG_ 2566877707 Trailer2NormalLevel_LvlPos 100;
BA_ "GenSigCycleTimeActive" SG_ 2566877707 Trailer2NormalLevel_LvlPos 100;
BA_ "GenSigStartValue" SG_ 2566877707 Trailer2NormalLevel_LvlPos 3;
BA_ "GenSigCycleTime" SG_ 2566877707 Trailer2RelBodyLevel_FrontLevel 100;
BA_ "GenSigCycleTimeActive" SG_ 2566877707 Trailer2RelBodyLevel_FrontLevel 100;
BA_ "GenSigStartValue" SG_ 2566877707 Trailer2RelBodyLevel_FrontLevel 65535;
BA_ "GenSigCycleTime" SG_ 2566877707 Trailer2NormalLevel_LvlStatus 100;
BA_ "GenSigCycleTimeActive" SG_ 2566877707 Trailer2NormalLevel_LvlStatus 100;
BA_ "GenSigStartValue" SG_ 2566877707 Trailer2NormalLevel_LvlStatus 3;
BA_ "GenSigCycleTime" SG_ 2566877451 Trailer1RelBodyLevel_FrontLevel 100;
BA_ "GenSigCycleTimeActive" SG_ 2566877451 Trailer1RelBodyLevel_FrontLevel 100;
BA_ "GenSigStartValue" SG_ 2566877451 Trailer1RelBodyLevel_FrontLevel 65535;
BA_ "GenSigCycleTime" SG_ 2566877451 Trailer1BrkLining_BrkLnTireId 100;
BA_ "GenSigCycleTimeActive" SG_ 2566877451 Trailer1BrkLining_BrkLnTireId 100;
BA_ "GenSigStartValue" SG_ 2566877451 Trailer1BrkLining_BrkLnTireId 255;
BA_ "GenSigCycleTime" SG_ 2566877451 Trailer1BrkLining_Wear 100;
BA_ "GenSigCycleTimeActive" SG_ 2566877451 Trailer1BrkLining_Wear 100;
BA_ "GenSigStartValue" SG_ 2566877451 Trailer1BrkLining_Wear 255;
BA_ "GenSigCycleTime" SG_ 2566877451 Trailer1NormalLevel_LvlPos 100;
BA_ "GenSigCycleTimeActive" SG_ 2566877451 Trailer1NormalLevel_LvlPos 100;
BA_ "GenSigStartValue" SG_ 2566877451 Trailer1NormalLevel_LvlPos 3;
BA_ "GenSigCycleTime" SG_ 2566877451 Trailer1BrkLining_Warning 100;
BA_ "GenSigCycleTimeActive" SG_ 2566877451 Trailer1BrkLining_Warning 100;
BA_ "GenSigStartValue" SG_ 2566877451 Trailer1BrkLining_Warning 3;
BA_ "GenSigCycleTime" SG_ 2566877451 Trailer1RampLevel_LvlPos 100;
BA_ "GenSigCycleTimeActive" SG_ 2566877451 Trailer1RampLevel_LvlPos 100;
BA_ "GenSigStartValue" SG_ 2566877451 Trailer1RampLevel_LvlPos 3;
BA_ "GenSigCycleTime" SG_ 2566877451 Trailer1NormalLevel_LvlStatus 100;
BA_ "GenSigCycleTimeActive" SG_ 2566877451 Trailer1NormalLevel_LvlStatus 100;
BA_ "GenSigStartValue" SG_ 2566877451 Trailer1NormalLevel_LvlStatus 3;
BA_ "GenSigCycleTime" SG_ 2566877451 Trailer1RampLevel_LvlStatus 100;
BA_ "GenSigCycleTimeActive" SG_ 2566877451 Trailer1RampLevel_LvlStatus 100;
BA_ "GenSigStartValue" SG_ 2566877451 Trailer1RampLevel_LvlStatus 3;
BA_ "GenSigCycleTime" SG_ 2566877451 Trailer1RelBodyLevel_RearLevel 100;
BA_ "GenSigCycleTimeActive" SG_ 2566877451 Trailer1RelBodyLevel_RearLevel 100;
BA_ "GenSigStartValue" SG_ 2566877451 Trailer1RelBodyLevel_RearLevel 65535;
BA_ "GenSigCycleTime" SG_ 2566894859 Trailer5VIN 100;
BA_ "GenSigCycleTimeActive" SG_ 2566894859 Trailer5VIN 100;
BA_ "GenSigCycleTime" SG_ 2566894603 Trailer4VIN 100;
BA_ "GenSigCycleTimeActive" SG_ 2566894603 Trailer4VIN 100;
BA_ "GenSigCycleTime" SG_ 2566894347 Trailer3VIN 100;
BA_ "GenSigCycleTimeActive" SG_ 2566894347 Trailer3VIN 100;
BA_ "GenSigCycleTime" SG_ 2566894091 Trailer2VIN 100;
BA_ "GenSigCycleTimeActive" SG_ 2566894091 Trailer2VIN 100;
BA_ "GenSigCycleTime" SG_ 2566893835 Trailer1VIN 100;
BA_ "GenSigCycleTimeActive" SG_ 2566893835 Trailer1VIN 100;
BA_ "GenSigCycleTime" SG_ 2566903051 Trailer5GeometricData_Content 100;
BA_ "GenSigCycleTimeActive" SG_ 2566903051 Trailer5GeometricData_Content 100;
BA_ "GenSigStartValue" SG_ 2566903051 Trailer5GeometricData_Content 255;
BA_ "GenSigCycleTime" SG_ 2566903051 Trailer5AxleLoadSum 100;
BA_ "GenSigCycleTimeActive" SG_ 2566903051 Trailer5AxleLoadSum 100;
BA_ "GenSigStartValue" SG_ 2566903051 Trailer5AxleLoadSum 65535;
BA_ "GenSigCycleTime" SG_ 2566903051 XBRBrakingCapacityTemperature 100;
BA_ "GenSigCycleTimeActive" SG_ 2566903051 XBRBrakingCapacityTemperature 100;
BA_ "GenSigStartValue" SG_ 2566903051 XBRBrakingCapacityTemperature 255;
BA_ "GenSigCycleTime" SG_ 2566903051 Trailer5GeometricData_Index 100;
BA_ "GenSigCycleTimeActive" SG_ 2566903051 Trailer5GeometricData_Index 100;
BA_ "GenSigStartValue" SG_ 2566903051 Trailer5GeometricData_Index 255;
BA_ "GenSigCycleTime" SG_ 2566903051 LiningWearWarning 100;
BA_ "GenSigCycleTimeActive" SG_ 2566903051 LiningWearWarning 100;
BA_ "GenSigStartValue" SG_ 2566903051 LiningWearWarning 3;
BA_ "GenSigCycleTime" SG_ 2566903051 XBRBrakingCapacityTime 100;
BA_ "GenSigCycleTimeActive" SG_ 2566903051 XBRBrakingCapacityTime 100;
BA_ "GenSigStartValue" SG_ 2566903051 XBRBrakingCapacityTime 255;
BA_ "GenSigCycleTime" SG_ 2566903051 PadChangePredictionAxleNumber 100;
BA_ "GenSigCycleTimeActive" SG_ 2566903051 PadChangePredictionAxleNumber 100;
BA_ "GenSigStartValue" SG_ 2566903051 PadChangePredictionAxleNumber 7;
BA_ "GenSigCycleTime" SG_ 2566902539 Trailer4AxleLoadSum 100;
BA_ "GenSigCycleTimeActive" SG_ 2566902539 Trailer4AxleLoadSum 100;
BA_ "GenSigStartValue" SG_ 2566902539 Trailer4AxleLoadSum 65535;
BA_ "GenSigCycleTime" SG_ 2566902539 Trailer4GeometricData_Content 100;
BA_ "GenSigCycleTimeActive" SG_ 2566902539 Trailer4GeometricData_Content 100;
BA_ "GenSigStartValue" SG_ 2566902539 Trailer4GeometricData_Content 255;
BA_ "GenSigCycleTime" SG_ 2566902539 Trailer4GeometricData_Index 100;
BA_ "GenSigCycleTimeActive" SG_ 2566902539 Trailer4GeometricData_Index 100;
BA_ "GenSigStartValue" SG_ 2566902539 Trailer4GeometricData_Index 255;
BA_ "GenSigCycleTime" SG_ 2566902539 Trailer3GeometricData_Index 100;
BA_ "GenSigCycleTimeActive" SG_ 2566902539 Trailer3GeometricData_Index 100;
BA_ "GenSigStartValue" SG_ 2566902539 Trailer3GeometricData_Index 255;
BA_ "GenSigCycleTime" SG_ 2566902539 Trailer3GeometricData_Content 100;
BA_ "GenSigCycleTimeActive" SG_ 2566902539 Trailer3GeometricData_Content 100;
BA_ "GenSigStartValue" SG_ 2566902539 Trailer3GeometricData_Content 255;
BA_ "GenSigCycleTime" SG_ 2566902539 Trailer3AxleLoadSum 100;
BA_ "GenSigCycleTimeActive" SG_ 2566902539 Trailer3AxleLoadSum 100;
BA_ "GenSigStartValue" SG_ 2566902539 Trailer3AxleLoadSum 65535;
BA_ "GenSigCycleTime" SG_ 2566902027 Trailer1AxleLoadSum 100;
BA_ "GenSigCycleTimeActive" SG_ 2566902027 Trailer1AxleLoadSum 100;
BA_ "GenSigStartValue" SG_ 2566902027 Trailer1AxleLoadSum 65535;
BA_ "GenSigCycleTime" SG_ 2566902027 Trailer2GeometricData_Content 100;
BA_ "GenSigCycleTimeActive" SG_ 2566902027 Trailer2GeometricData_Content 100;
BA_ "GenSigStartValue" SG_ 2566902027 Trailer2GeometricData_Content 255;
BA_ "GenSigCycleTime" SG_ 2566902027 Trailer2AxleLoadSum 100;
BA_ "GenSigCycleTimeActive" SG_ 2566902027 Trailer2AxleLoadSum 100;
BA_ "GenSigStartValue" SG_ 2566902027 Trailer2AxleLoadSum 65535;
BA_ "GenSigCycleTime" SG_ 2566902027 Trailer2GeometricData_Index 100;
BA_ "GenSigCycleTimeActive" SG_ 2566902027 Trailer2GeometricData_Index 100;
BA_ "GenSigStartValue" SG_ 2566902027 Trailer2GeometricData_Index 255;
BA_ "GenSigCycleTime" SG_ 2566902027 Trailer1GeometricData_Content 100;
BA_ "GenSigCycleTimeActive" SG_ 2566902027 Trailer1GeometricData_Content 100;
BA_ "GenSigStartValue" SG_ 2566902027 Trailer1GeometricData_Content 255;
BA_ "GenSigCycleTime" SG_ 2566902027 Trailer1GeometricData_Index 100;
BA_ "GenSigCycleTimeActive" SG_ 2566902027 Trailer1GeometricData_Index 100;
BA_ "GenSigStartValue" SG_ 2566902027 Trailer1GeometricData_Index 255;
BA_ "GenSigCycleTime" SG_ 2566886667 Trailer5AxleLoad_AxleLoad 100;
BA_ "GenSigCycleTimeActive" SG_ 2566886667 Trailer5AxleLoad_AxleLoad 100;
BA_ "GenSigStartValue" SG_ 2566886667 Trailer5AxleLoad_AxleLoad 65535;
BA_ "GenSigCycleTime" SG_ 2566886667 Trailer5LiftAxle1Pos 100;
BA_ "GenSigCycleTimeActive" SG_ 2566886667 Trailer5LiftAxle1Pos 100;
BA_ "GenSigStartValue" SG_ 2566886667 Trailer5LiftAxle1Pos 3;
BA_ "GenSigCycleTime" SG_ 2566886667 Trailer5LiftAxle2Pos 100;
BA_ "GenSigCycleTimeActive" SG_ 2566886667 Trailer5LiftAxle2Pos 100;
BA_ "GenSigStartValue" SG_ 2566886667 Trailer5LiftAxle2Pos 3;
BA_ "GenSigCycleTime" SG_ 2566886667 Trailer5AxleLoad_AxleId 100;
BA_ "GenSigCycleTimeActive" SG_ 2566886667 Trailer5AxleLoad_AxleId 100;
BA_ "GenSigCycleTime" SG_ 2566886155 Trailer4LiftAxle2Pos 100;
BA_ "GenSigCycleTimeActive" SG_ 2566886155 Trailer4LiftAxle2Pos 100;
BA_ "GenSigStartValue" SG_ 2566886155 Trailer4LiftAxle2Pos 3;
BA_ "GenSigCycleTime" SG_ 2566886155 Trailer4LiftAxle1Pos 100;
BA_ "GenSigCycleTimeActive" SG_ 2566886155 Trailer4LiftAxle1Pos 100;
BA_ "GenSigStartValue" SG_ 2566886155 Trailer4LiftAxle1Pos 3;
BA_ "GenSigCycleTime" SG_ 2566886155 Trailer3LiftAxle1Pos 100;
BA_ "GenSigCycleTimeActive" SG_ 2566886155 Trailer3LiftAxle1Pos 100;
BA_ "GenSigStartValue" SG_ 2566886155 Trailer3LiftAxle1Pos 3;
BA_ "GenSigCycleTime" SG_ 2566886155 Trailer4AxleLoad_AxleLoad 100;
BA_ "GenSigCycleTimeActive" SG_ 2566886155 Trailer4AxleLoad_AxleLoad 100;
BA_ "GenSigStartValue" SG_ 2566886155 Trailer4AxleLoad_AxleLoad 65535;
BA_ "GenSigCycleTime" SG_ 2566886155 Trailer3AxleLoad_AxleLoad 100;
BA_ "GenSigCycleTimeActive" SG_ 2566886155 Trailer3AxleLoad_AxleLoad 100;
BA_ "GenSigStartValue" SG_ 2566886155 Trailer3AxleLoad_AxleLoad 65535;
BA_ "GenSigCycleTime" SG_ 2566886155 Trailer3AxleLoad_AxleId 100;
BA_ "GenSigCycleTimeActive" SG_ 2566886155 Trailer3AxleLoad_AxleId 100;
BA_ "GenSigCycleTime" SG_ 2566886155 Trailer4AxleLoad_AxleId 100;
BA_ "GenSigCycleTimeActive" SG_ 2566886155 Trailer4AxleLoad_AxleId 100;
BA_ "GenSigCycleTime" SG_ 2566886155 Trailer3LiftAxle2Pos 100;
BA_ "GenSigCycleTimeActive" SG_ 2566886155 Trailer3LiftAxle2Pos 100;
BA_ "GenSigStartValue" SG_ 2566886155 Trailer3LiftAxle2Pos 3;
BA_ "GenSigCycleTime" SG_ 2566885643 Trailer2LiftAxle2Pos 100;
BA_ "GenSigCycleTimeActive" SG_ 2566885643 Trailer2LiftAxle2Pos 100;
BA_ "GenSigStartValue" SG_ 2566885643 Trailer2LiftAxle2Pos 3;
BA_ "GenSigCycleTime" SG_ 2566885643 Trailer1AxleLoad_AxleLoad 100;
BA_ "GenSigCycleTimeActive" SG_ 2566885643 Trailer1AxleLoad_AxleLoad 100;
BA_ "GenSigStartValue" SG_ 2566885643 Trailer1AxleLoad_AxleLoad 65535;
BA_ "GenSigCycleTime" SG_ 2566885643 Trailer2AxleLoad_AxleLoad 100;
BA_ "GenSigCycleTimeActive" SG_ 2566885643 Trailer2AxleLoad_AxleLoad 100;
BA_ "GenSigStartValue" SG_ 2566885643 Trailer2AxleLoad_AxleLoad 65535;
BA_ "GenSigCycleTime" SG_ 2566885643 Trailer1AxleLoad_AxleId 100;
BA_ "GenSigCycleTimeActive" SG_ 2566885643 Trailer1AxleLoad_AxleId 100;
BA_ "GenSigCycleTime" SG_ 2566885643 Trailer2LiftAxle1Pos 100;
BA_ "GenSigCycleTimeActive" SG_ 2566885643 Trailer2LiftAxle1Pos 100;
BA_ "GenSigStartValue" SG_ 2566885643 Trailer2LiftAxle1Pos 3;
BA_ "GenSigCycleTime" SG_ 2566885643 TrailerEBSFault 100;
BA_ "GenSigCycleTimeActive" SG_ 2566885643 TrailerEBSFault 100;
BA_ "GenSigStartValue" SG_ 2566885643 TrailerEBSFault 3;
BA_ "GenSigCycleTime" SG_ 2566885643 Trailer2AxleLoad_AxleId 100;
BA_ "GenSigCycleTimeActive" SG_ 2566885643 Trailer2AxleLoad_AxleId 100;
BA_ "GenSigCycleTime" SG_ 2566885643 TrailersConnected 100;
BA_ "GenSigCycleTimeActive" SG_ 2566885643 TrailersConnected 100;
BA_ "GenSigStartValue" SG_ 2566885643 TrailersConnected 7;
BA_ "GenSigCycleTime" SG_ 2566906635 PadChgPredictionLastPadChg 100;
BA_ "GenSigCycleTimeActive" SG_ 2566906635 PadChgPredictionLastPadChg 100;
BA_ "GenSigStartValue" SG_ 2566906635 PadChgPredictionLastPadChg 4294967295;
BA_ "GenSigCycleTime" SG_ 2566906635 PredictedMileageOfNextPadChg 100;
BA_ "GenSigCycleTimeActive" SG_ 2566906635 PredictedMileageOfNextPadChg 100;
BA_ "GenSigStartValue" SG_ 2566906635 PredictedMileageOfNextPadChg 4294967295;
BA_ "GenSigCycleTime" SG_ 2499761675 RearAxleDiffLockActvnFuncReq 100;
BA_ "GenSigCycleTimeActive" SG_ 2499761675 RearAxleDiffLockActvnFuncReq 100;
BA_ "GenSigStartValue" SG_ 2499761675 RearAxleDiffLockActvnFuncReq 3;
BA_ "GenSigCycleTime" SG_ 2499761675 PoorBrakePerformanceWarning 100;
BA_ "GenSigCycleTimeActive" SG_ 2499761675 PoorBrakePerformanceWarning 100;
BA_ "GenSigStartValue" SG_ 2499761675 PoorBrakePerformanceWarning 3;
BA_ "GenSigCycleTime" SG_ 2499761675 TrcnCtrlSlipperyRoadWarning 100;
BA_ "GenSigCycleTimeActive" SG_ 2499761675 TrcnCtrlSlipperyRoadWarning 100;
BA_ "GenSigStartValue" SG_ 2499761675 TrcnCtrlSlipperyRoadWarning 3;
BA_ "GenSigCycleTime" SG_ 2499761675 DTCActive 100;
BA_ "GenSigCycleTimeActive" SG_ 2499761675 DTCActive 100;
BA_ "GenSigStartValue" SG_ 2499761675 DTCActive 3;
BA_ "GenSigCycleTime" SG_ 2499761675 AutoRearAxleDiffLockFnc_stat 100;
BA_ "GenSigCycleTimeActive" SG_ 2499761675 AutoRearAxleDiffLockFnc_stat 100;
BA_ "GenSigStartValue" SG_ 2499761675 AutoRearAxleDiffLockFnc_stat 3;
BA_ "GenSigCycleTime" SG_ 2499761675 TractionFunctionSelected 100;
BA_ "GenSigCycleTimeActive" SG_ 2499761675 TractionFunctionSelected 100;
BA_ "GenSigStartValue" SG_ 2499761675 TractionFunctionSelected 7;
BA_ "GenSigCycleTime" SG_ 2499761675 BrakeTempWarningLevel 100;
BA_ "GenSigCycleTimeActive" SG_ 2499761675 BrakeTempWarningLevel 100;
BA_ "GenSigStartValue" SG_ 2499761675 BrakeTempWarningLevel 255;
BA_ "GenSigCycleTime" SG_ 2499761675 ABSInhibitionStatus 100;
BA_ "GenSigCycleTimeActive" SG_ 2499761675 ABSInhibitionStatus 100;
BA_ "GenSigStartValue" SG_ 2499761675 ABSInhibitionStatus 3;
BA_ "GenSigCycleTime" SG_ 2499761675 ABSManAutoInhibitionStat 100;
BA_ "GenSigCycleTimeActive" SG_ 2499761675 ABSManAutoInhibitionStat 100;
BA_ "GenSigStartValue" SG_ 2499761675 ABSManAutoInhibitionStat 7;
BA_ "GenSigCycleTime" SG_ 2499761675 VDCActive 100;
BA_ "GenSigCycleTimeActive" SG_ 2499761675 VDCActive 100;
BA_ "GenSigStartValue" SG_ 2499761675 VDCActive 3;
BA_ "GenSigCycleTime" SG_ 2499761675 RearAxleSteeringFunctionStatus 100;
BA_ "GenSigCycleTimeActive" SG_ 2499761675 RearAxleSteeringFunctionStatus 100;
BA_ "GenSigStartValue" SG_ 2499761675 RearAxleSteeringFunctionStatus 7;
BA_ "GenSigCycleTime" SG_ 2499761675 HSAAvailability 100;
BA_ "GenSigCycleTimeActive" SG_ 2499761675 HSAAvailability 100;
BA_ "GenSigStartValue" SG_ 2499761675 HSAAvailability 3;
BA_ "GenSigCycleTime" SG_ 2499761675 RollerBenchModeStatus 100;
BA_ "GenSigCycleTimeActive" SG_ 2499761675 RollerBenchModeStatus 100;
BA_ "GenSigStartValue" SG_ 2499761675 RollerBenchModeStatus 3;
BA_ "GenSigCycleTime" SG_ 2499761675 BrakeAssistStatus 100;
BA_ "GenSigCycleTimeActive" SG_ 2499761675 BrakeAssistStatus 100;
BA_ "GenSigStartValue" SG_ 2499761675 BrakeAssistStatus 3;
BA_ "GenSigCycleTime" SG_ 2499750411 XBRSystemInformation 100;
BA_ "GenSigCycleTimeActive" SG_ 2499750411 XBRSystemInformation 100;
BA_ "GenSigStartValue" SG_ 2499750411 XBRSystemInformation 7;
BA_ "GenSigCycleTime" SG_ 2499750411 BrakePedalTestState 100;
BA_ "GenSigCycleTimeActive" SG_ 2499750411 BrakePedalTestState 100;
BA_ "GenSigStartValue" SG_ 2499750411 BrakePedalTestState 15;
BA_ "GenSigCycleTime" SG_ 2499750411 HillStartAidStatus 100;
BA_ "GenSigCycleTimeActive" SG_ 2499750411 HillStartAidStatus 100;
BA_ "GenSigStartValue" SG_ 2499750411 HillStartAidStatus 7;
BA_ "GenSigCycleTime" SG_ 2499750411 SasAdaptationInProgress 100;
BA_ "GenSigCycleTimeActive" SG_ 2499750411 SasAdaptationInProgress 100;
BA_ "GenSigStartValue" SG_ 2499750411 SasAdaptationInProgress 3;
BA_ "GenSigCycleTime" SG_ 2499750411 ESCStatus 100;
BA_ "GenSigCycleTimeActive" SG_ 2499750411 ESCStatus 100;
BA_ "GenSigStartValue" SG_ 2499750411 ESCStatus 7;
BA_ "GenSigCycleTime" SG_ 2499750411 HillHolderMode 100;
BA_ "GenSigCycleTimeActive" SG_ 2499750411 HillHolderMode 100;
BA_ "GenSigStartValue" SG_ 2499750411 HillHolderMode 7;
BA_ "GenSigCycleTime" SG_ 2499750411 ESCState 100;
BA_ "GenSigCycleTimeActive" SG_ 2499750411 ESCState 100;
BA_ "GenSigStartValue" SG_ 2499750411 ESCState 7;
BA_ "GenSigCycleTime" SG_ 2499750411 ABSOffRoadStatus 100;
BA_ "GenSigCycleTimeActive" SG_ 2499750411 ABSOffRoadStatus 100;
BA_ "GenSigStartValue" SG_ 2499750411 ABSOffRoadStatus 3;
BA_ "GenSigCycleTime" SG_ 2499750411 TrailerCorrectionPressure 100;
BA_ "GenSigCycleTimeActive" SG_ 2499750411 TrailerCorrectionPressure 100;
BA_ "GenSigStartValue" SG_ 2499750411 TrailerCorrectionPressure 255;
BA_ "GenSigCycleTime" SG_ 2499750411 RoadSpeedInformation 100;
BA_ "GenSigCycleTimeActive" SG_ 2499750411 RoadSpeedInformation 100;
BA_ "GenSigStartValue" SG_ 2499750411 RoadSpeedInformation 255;
BA_ "GenSigCycleTime" SG_ 2566767627 BrakeTemperatureWarning 100;
BA_ "GenSigCycleTimeActive" SG_ 2566767627 BrakeTemperatureWarning 100;
BA_ "GenSigStartValue" SG_ 2566767627 BrakeTemperatureWarning 3;
BA_ "GenSigCycleTime" SG_ 2566767627 FoundationBrakeUse 100;
BA_ "GenSigCycleTimeActive" SG_ 2566767627 FoundationBrakeUse 100;
BA_ "GenSigStartValue" SG_ 2566767627 FoundationBrakeUse 3;
BA_ "GenSigCycleTime" SG_ 2566767627 XBRActiveControlMode 100;
BA_ "GenSigCycleTimeActive" SG_ 2566767627 XBRActiveControlMode 100;
BA_ "GenSigStartValue" SG_ 2566767627 XBRActiveControlMode 15;
BA_ "GenSigCycleTime" SG_ 2566767627 XBRSystemState 100;
BA_ "GenSigCycleTimeActive" SG_ 2566767627 XBRSystemState 100;
BA_ "GenSigStartValue" SG_ 2566767627 XBRSystemState 3;
BA_ "GenSigCycleTime" SG_ 2566767627 EPBHillHolderMode 100;
BA_ "GenSigCycleTimeActive" SG_ 2566767627 EPBHillHolderMode 100;
BA_ "GenSigStartValue" SG_ 2566767627 EPBHillHolderMode 7;
BA_ "GenSigCycleTime" SG_ 2499723019 RrAxle1RightWheelRelativeSpeed 100;
BA_ "GenSigCycleTimeActive" SG_ 2499723019 RrAxle1RightWheelRelativeSpeed 100;
BA_ "GenSigStartValue" SG_ 2499723019 RrAxle1RightWheelRelativeSpeed 255;
BA_ "GenSigCycleTime" SG_ 2499723019 FrAxleRightWheelRelativeSpeed 100;
BA_ "GenSigCycleTimeActive" SG_ 2499723019 FrAxleRightWheelRelativeSpeed 100;
BA_ "GenSigStartValue" SG_ 2499723019 FrAxleRightWheelRelativeSpeed 255;
BA_ "GenSigCycleTime" SG_ 2499723019 RrAxle2LeftWheelRelativeSpeed 100;
BA_ "GenSigCycleTimeActive" SG_ 2499723019 RrAxle2LeftWheelRelativeSpeed 100;
BA_ "GenSigStartValue" SG_ 2499723019 RrAxle2LeftWheelRelativeSpeed 255;
BA_ "GenSigCycleTime" SG_ 2499723019 FrontAxleSpeed 100;
BA_ "GenSigCycleTimeActive" SG_ 2499723019 FrontAxleSpeed 100;
BA_ "GenSigStartValue" SG_ 2499723019 FrontAxleSpeed 65535;
BA_ "GenSigCycleTime" SG_ 2499723019 FrAxleLeftWheelRelativeSpeed 100;
BA_ "GenSigCycleTimeActive" SG_ 2499723019 FrAxleLeftWheelRelativeSpeed 100;
BA_ "GenSigStartValue" SG_ 2499723019 FrAxleLeftWheelRelativeSpeed 255;
BA_ "GenSigCycleTime" SG_ 2499723019 RrAxle1LeftWheelRelativeSpeed 100;
BA_ "GenSigCycleTimeActive" SG_ 2499723019 RrAxle1LeftWheelRelativeSpeed 100;
BA_ "GenSigStartValue" SG_ 2499723019 RrAxle1LeftWheelRelativeSpeed 255;
BA_ "GenSigCycleTime" SG_ 2499723019 RrAxle2RightWheelRelativeSpeed 100;
BA_ "GenSigCycleTimeActive" SG_ 2499723019 RrAxle2RightWheelRelativeSpeed 100;
BA_ "GenSigStartValue" SG_ 2499723019 RrAxle2RightWheelRelativeSpeed 255;
BA_ "GenSigCycleTime" SG_ 2565865739 ASREngineControlActive 100;
BA_ "GenSigCycleTimeActive" SG_ 2565865739 ASREngineControlActive 100;
BA_ "GenSigStartValue" SG_ 2565865739 ASREngineControlActive 3;
BA_ "GenSigCycleTime" SG_ 2565865739 ASRBrakeControlActive 100;
BA_ "GenSigCycleTimeActive" SG_ 2565865739 ASRBrakeControlActive 100;
BA_ "GenSigStartValue" SG_ 2565865739 ASRBrakeControlActive 3;
BA_ "GenSigCycleTime" SG_ 2565865739 ABSFullyOperational 100;
BA_ "GenSigCycleTimeActive" SG_ 2565865739 ABSFullyOperational 100;
BA_ "GenSigStartValue" SG_ 2565865739 ABSFullyOperational 3;
BA_ "GenSigCycleTime" SG_ 2565865739 EBSRedWarningSignal 100;
BA_ "GenSigCycleTimeActive" SG_ 2565865739 EBSRedWarningSignal 100;
BA_ "GenSigStartValue" SG_ 2565865739 EBSRedWarningSignal 3;
BA_ "GenSigCycleTime" SG_ 2565865739 ABSEBSAmberWarningSignal 100;
BA_ "GenSigCycleTimeActive" SG_ 2565865739 ABSEBSAmberWarningSignal 100;
BA_ "GenSigStartValue" SG_ 2565865739 ABSEBSAmberWarningSignal 3;
BA_ "GenSigCycleTime" SG_ 2565865739 AntiLockBrakingActive 100;
BA_ "GenSigCycleTimeActive" SG_ 2565865739 AntiLockBrakingActive 100;
BA_ "GenSigStartValue" SG_ 2565865739 AntiLockBrakingActive 3;
BA_ "GenSigCycleTime" SG_ 2565865739 ASRHillHolderSwitch 100;
BA_ "GenSigCycleTimeActive" SG_ 2565865739 ASRHillHolderSwitch 100;
BA_ "GenSigStartValue" SG_ 2565865739 ASRHillHolderSwitch 3;
BA_ "GenSigSendType" SG_ 2671964712 DiagUUDTRespSig_F2_28 7;
BA_ "GenSigSendType" SG_ 2671964689 DiagUUDTRespSig_F2_11 7;
BA_ "GenSigSendType" SG_ 2671834152 InternalTesterDiagSig_F4_28 7;
BA_ "GenSigSendType" SG_ 2671834129 InternalTesterDiagSig_F4_11 7;
BA_ "GenSigSendType" SG_ 2671782132 InternalTesterDiagSig_28_F4 7;
BA_ "GenSigSendType" SG_ 2671776244 InternalTesterDiagSig_11_F4 7;
BA_ "GenSigSendType" SG_ 2566907915 DiagFaultStat_Brake_FailTA 3;
BA_ "GenSigCycleTime" SG_ 2566907915 DiagFaultStat_Brake_FailTA 100;
BA_ "GenSigCycleTimeActive" SG_ 2566907915 DiagFaultStat_Brake_FailTA 100;
BA_ "GenSigSendType" SG_ 2566907915 DiagFaultStat_Brake_sg_UB 7;
BA_ "Platform_VMCU1_Sig" SG_ 2566907915 DiagFaultStat_Brake_sg_UB 1;
BA_ "GenSigSendType" SG_ 2566907915 DiagFaultStat_Brake_DtcIdB 3;
BA_ "GenSigCycleTime" SG_ 2566907915 DiagFaultStat_Brake_DtcIdB 100;
BA_ "GenSigCycleTimeActive" SG_ 2566907915 DiagFaultStat_Brake_DtcIdB 100;
BA_ "GenSigSendType" SG_ 2566907915 DiagFaultStat_Brake_DtcIdA 3;
BA_ "GenSigCycleTime" SG_ 2566907915 DiagFaultStat_Brake_DtcIdA 100;
BA_ "GenSigCycleTimeActive" SG_ 2566907915 DiagFaultStat_Brake_DtcIdA 100;
BA_ "GenSigSendType" SG_ 2566907915 DiagFaultStat_Brake_EcuAdr 3;
BA_ "GenSigCycleTime" SG_ 2566907915 DiagFaultStat_Brake_EcuAdr 100;
BA_ "GenSigCycleTimeActive" SG_ 2566907915 DiagFaultStat_Brake_EcuAdr 100;
BA_ "GenSigStartValue" SG_ 2566907915 DiagFaultStat_Brake_EcuAdr 255;
BA_ "GenSigSendType" SG_ 2566907915 DiagFaultStat_Brake_FailTB 3;
BA_ "GenSigCycleTime" SG_ 2566907915 DiagFaultStat_Brake_FailTB 100;
BA_ "GenSigCycleTimeActive" SG_ 2566907915 DiagFaultStat_Brake_FailTB 100;
BA_ "GenSigSendType" SG_ 2566907965 DiagFaultStat_ACM_FailTB 3;
BA_ "GenSigCycleTime" SG_ 2566907965 DiagFaultStat_ACM_FailTB 100;
BA_ "GenSigCycleTimeActive" SG_ 2566907965 DiagFaultStat_ACM_FailTB 100;
BA_ "GenSigSendType" SG_ 2566907965 DiagFaultStat_ACM_FailTA 3;
BA_ "GenSigCycleTime" SG_ 2566907965 DiagFaultStat_ACM_FailTA 100;
BA_ "GenSigCycleTimeActive" SG_ 2566907965 DiagFaultStat_ACM_FailTA 100;
BA_ "GenSigSendType" SG_ 2566907965 DiagFaultStat_ACM_DtcIdB 3;
BA_ "GenSigCycleTime" SG_ 2566907965 DiagFaultStat_ACM_DtcIdB 100;
BA_ "GenSigCycleTimeActive" SG_ 2566907965 DiagFaultStat_ACM_DtcIdB 100;
BA_ "GenSigSendType" SG_ 2566907965 DiagFaultStat_ACM_DtcIdA 3;
BA_ "GenSigCycleTime" SG_ 2566907965 DiagFaultStat_ACM_DtcIdA 100;
BA_ "GenSigCycleTimeActive" SG_ 2566907965 DiagFaultStat_ACM_DtcIdA 100;
BA_ "GenSigSendType" SG_ 2566907965 DiagFaultStat_ACM_EcuAdr 3;
BA_ "GenSigCycleTime" SG_ 2566907965 DiagFaultStat_ACM_EcuAdr 100;
BA_ "GenSigCycleTimeActive" SG_ 2566907965 DiagFaultStat_ACM_EcuAdr 100;
BA_ "GenSigStartValue" SG_ 2566907965 DiagFaultStat_ACM_EcuAdr 255;
BA_ "GenSigSendType" SG_ 2566907965 DiagFaultStat_ACM_sg_UB 7;
BA_ "Platform_VMCU1_Sig" SG_ 2566907965 DiagFaultStat_ACM_sg_UB 1;
BA_ "GenSigCycleTime" SG_ 2566749184 DPFC1_InhibDueServiceBrake 100;
BA_ "GenSigCycleTimeActive" SG_ 2566749184 DPFC1_InhibDueServiceBrake 100;
BA_ "GenSigStartValue" SG_ 2566749184 DPFC1_InhibDueServiceBrake 3;
BA_ "GenSigCycleTime" SG_ 2566749184 DPFC1_InhibVehSpdBelowAllwdSpd 100;
BA_ "GenSigCycleTimeActive" SG_ 2566749184 DPFC1_InhibVehSpdBelowAllwdSpd 100;
BA_ "GenSigStartValue" SG_ 2566749184 DPFC1_InhibVehSpdBelowAllwdSpd 3;
BA_ "GenSigSendType" SG_ 2566749184 DPFC1_ActiveRegeneratStatus 3;
BA_ "GenSigCycleTime" SG_ 2566749184 DPFC1_ActiveRegeneratStatus 100;
BA_ "GenSigCycleTimeActive" SG_ 2566749184 DPFC1_ActiveRegeneratStatus 100;
BA_ "GenSigStartValue" SG_ 2566749184 DPFC1_ActiveRegeneratStatus 3;
BA_ "GenSigCycleTime" SG_ 2566749184 DPFC1_ExhaustSystHighTempLampCmd 100;
BA_ "GenSigCycleTimeActive" SG_ 2566749184 DPFC1_ExhaustSystHighTempLampCmd 100;
BA_ "GenSigStartValue" SG_ 2566749184 DPFC1_ExhaustSystHighTempLampCmd 7;
BA_ "GenSigCycleTime" SG_ 2566749184 DPFC1_InhibParkBrakeNotSet 100;
BA_ "GenSigCycleTimeActive" SG_ 2566749184 DPFC1_InhibParkBrakeNotSet 100;
BA_ "GenSigStartValue" SG_ 2566749184 DPFC1_InhibParkBrakeNotSet 3;
BA_ "GenSigCycleTime" SG_ 2566749184 DPFC1_InhibEnginNotWarmUp 100;
BA_ "GenSigCycleTimeActive" SG_ 2566749184 DPFC1_InhibEnginNotWarmUp 100;
BA_ "GenSigStartValue" SG_ 2566749184 DPFC1_InhibEnginNotWarmUp 3;
BA_ "GenSigSendType" SG_ 2566749184 DPFC1_InhibitStatus 3;
BA_ "GenSigCycleTime" SG_ 2566749184 DPFC1_InhibitStatus 100;
BA_ "GenSigCycleTimeActive" SG_ 2566749184 DPFC1_InhibitStatus 100;
BA_ "GenSigStartValue" SG_ 2566749184 DPFC1_InhibitStatus 3;
BA_ "GenSigCycleTime" SG_ 2566749184 DPFC1_ForcedStatus 100;
BA_ "GenSigCycleTimeActive" SG_ 2566749184 DPFC1_ForcedStatus 100;
BA_ "GenSigStartValue" SG_ 2566749184 DPFC1_ForcedStatus 7;
BA_ "GenSigCycleTime" SG_ 2566749184 DPFC1_PassiveRegenStatus 100;
BA_ "GenSigCycleTimeActive" SG_ 2566749184 DPFC1_PassiveRegenStatus 100;
BA_ "GenSigStartValue" SG_ 2566749184 DPFC1_PassiveRegenStatus 3;
BA_ "GenSigCycleTime" SG_ 2566749184 DPFC1_InhibTempSystemLock 100;
BA_ "GenSigCycleTimeActive" SG_ 2566749184 DPFC1_InhibTempSystemLock 100;
BA_ "GenSigStartValue" SG_ 2566749184 DPFC1_InhibTempSystemLock 3;
BA_ "GenSigCycleTime" SG_ 2566749184 DPFC1_InhibDueInhibSwitch 100;
BA_ "GenSigCycleTimeActive" SG_ 2566749184 DPFC1_InhibDueInhibSwitch 100;
BA_ "GenSigStartValue" SG_ 2566749184 DPFC1_InhibDueInhibSwitch 3;
BA_ "GenSigCycleTime" SG_ 2566749184 DPFC1_InhibPTOActive 100;
BA_ "GenSigCycleTimeActive" SG_ 2566749184 DPFC1_InhibPTOActive 100;
BA_ "GenSigStartValue" SG_ 2566749184 DPFC1_InhibPTOActive 3;
BA_ "GenSigCycleTime" SG_ 2566749184 DPFC1_AutoARInitConfig 100;
BA_ "GenSigCycleTimeActive" SG_ 2566749184 DPFC1_AutoARInitConfig 100;
BA_ "GenSigStartValue" SG_ 2566749184 DPFC1_AutoARInitConfig 3;
BA_ "GenSigCycleTime" SG_ 2566749184 DPFC1_InhibDueLowExhGasTemp 100;
BA_ "GenSigCycleTimeActive" SG_ 2566749184 DPFC1_InhibDueLowExhGasTemp 100;
BA_ "GenSigStartValue" SG_ 2566749184 DPFC1_InhibDueLowExhGasTemp 3;
BA_ "GenSigCycleTime" SG_ 2566749184 DPFC1_InhibSystemFaultAct 100;
BA_ "GenSigCycleTimeActive" SG_ 2566749184 DPFC1_InhibSystemFaultAct 100;
BA_ "GenSigStartValue" SG_ 2566749184 DPFC1_InhibSystemFaultAct 3;
BA_ "GenSigCycleTime" SG_ 2566749184 DPFC1_InhibDueSystemTimeout 100;
BA_ "GenSigCycleTimeActive" SG_ 2566749184 DPFC1_InhibDueSystemTimeout 100;
BA_ "GenSigStartValue" SG_ 2566749184 DPFC1_InhibDueSystemTimeout 3;
BA_ "GenSigCycleTime" SG_ 2566749184 DPFC1_InhibPermSystemLock 100;
BA_ "GenSigCycleTimeActive" SG_ 2566749184 DPFC1_InhibPermSystemLock 100;
BA_ "GenSigStartValue" SG_ 2566749184 DPFC1_InhibPermSystemLock 3;
BA_ "GenSigCycleTime" SG_ 2566749184 DPFC1_LampCommand 100;
BA_ "GenSigCycleTimeActive" SG_ 2566749184 DPFC1_LampCommand 100;
BA_ "GenSigStartValue" SG_ 2566749184 DPFC1_LampCommand 7;
BA_ "GenSigCycleTime" SG_ 2566749184 DPFC1_InhibVehSpdAboveAllwdSpd 100;
BA_ "GenSigCycleTimeActive" SG_ 2566749184 DPFC1_InhibVehSpdAboveAllwdSpd 100;
BA_ "GenSigStartValue" SG_ 2566749184 DPFC1_InhibVehSpdAboveAllwdSpd 3;
BA_ "GenSigCycleTime" SG_ 2566749184 DPFC1_InhibClutchDisengage 100;
BA_ "GenSigCycleTimeActive" SG_ 2566749184 DPFC1_InhibClutchDisengage 100;
BA_ "GenSigStartValue" SG_ 2566749184 DPFC1_InhibClutchDisengage 3;
BA_ "GenSigCycleTime" SG_ 2566749184 DPFC1_InhibAccPedalOffIdle 100;
BA_ "GenSigCycleTimeActive" SG_ 2566749184 DPFC1_InhibAccPedalOffIdle 100;
BA_ "GenSigStartValue" SG_ 2566749184 DPFC1_InhibAccPedalOffIdle 3;
BA_ "GenSigCycleTime" SG_ 2566749184 DPFC1_InhibOutOfNeutral 100;
BA_ "GenSigCycleTimeActive" SG_ 2566749184 DPFC1_InhibOutOfNeutral 100;
BA_ "GenSigStartValue" SG_ 2566749184 DPFC1_InhibOutOfNeutral 3;
BA_ "GenSigCycleTime" SG_ 2566749184 DPFC1_DPFStatus 100;
BA_ "GenSigCycleTimeActive" SG_ 2566749184 DPFC1_DPFStatus 100;
BA_ "GenSigStartValue" SG_ 2566749184 DPFC1_DPFStatus 7;
BA_ "GenSigCycleTime" SG_ 2566834691 DiagnosticsFaultStat_DM1_TECU 100;
BA_ "GenSigCycleTimeActive" SG_ 2566834691 DiagnosticsFaultStat_DM1_TECU 100;
BA_ "GenSigCycleTime" SG_ 2566834688 DiagnosticsFaultStat_DM1_EMS 100;
BA_ "GenSigCycleTimeActive" SG_ 2566834688 DiagnosticsFaultStat_DM1_EMS 100;
BA_ "GenSigCycleTime" SG_ 2566834749 DiagnosticsFaultStat_DM1_ACM 100;
BA_ "GenSigCycleTimeActive" SG_ 2566834749 DiagnosticsFaultStat_DM1_ACM 100;
BA_ "GenSigCycleTime" SG_ 2566811659 PoweredVehicleWeight 100;
BA_ "GenSigCycleTimeActive" SG_ 2566811659 PoweredVehicleWeight 100;
BA_ "GenSigStartValue" SG_ 2566811659 PoweredVehicleWeight 65535;
BA_ "GenSigCycleTime" SG_ 2566811659 GrossCombinationVehicleWeight 100;
BA_ "GenSigCycleTimeActive" SG_ 2566811659 GrossCombinationVehicleWeight 100;
BA_ "GenSigStartValue" SG_ 2566811659 GrossCombinationVehicleWeight 65535;
BA_ "GenSigCycleTime" SG_ 2499757105 HSADriverRequest 100;
BA_ "GenSigCycleTimeActive" SG_ 2499757105 HSADriverRequest 100;
BA_ "GenSigStartValue" SG_ 2499757105 HSADriverRequest 3;
BA_ "GenSigCycleTime" SG_ 2499757105 ESCDriverReq 100;
BA_ "GenSigCycleTimeActive" SG_ 2499757105 ESCDriverReq 100;
BA_ "GenSigStartValue" SG_ 2499757105 ESCDriverReq 7;
BA_ "GenSigCycleTime" SG_ 2499757105 RrRrItrWhlDiffLckActvnDrvrReq 100;
BA_ "GenSigCycleTimeActive" SG_ 2499757105 RrRrItrWhlDiffLckActvnDrvrReq 100;
BA_ "GenSigStartValue" SG_ 2499757105 RrRrItrWhlDiffLckActvnDrvrReq 3;
BA_ "GenSigCycleTime" SG_ 2499757105 AutRrAxleDiffLockActvnDrvrReq 100;
BA_ "GenSigCycleTimeActive" SG_ 2499757105 AutRrAxleDiffLockActvnDrvrReq 100;
BA_ "GenSigStartValue" SG_ 2499757105 AutRrAxleDiffLockActvnDrvrReq 3;
BA_ "GenSigCycleTime" SG_ 2499757105 ABSModeRequest 100;
BA_ "GenSigCycleTimeActive" SG_ 2499757105 ABSModeRequest 100;
BA_ "GenSigStartValue" SG_ 2499757105 ABSModeRequest 7;
BA_ "GenSigCycleTime" SG_ 2499757105 FrRrItrWhlDiffLckActvnDrvrReq 100;
BA_ "GenSigCycleTimeActive" SG_ 2499757105 FrRrItrWhlDiffLckActvnDrvrReq 100;
BA_ "GenSigStartValue" SG_ 2499757105 FrRrItrWhlDiffLckActvnDrvrReq 3;
BA_ "GenSigCycleTime" SG_ 2499757105 RearAxleSteeringFunctionDsbl 100;
BA_ "GenSigCycleTimeActive" SG_ 2499757105 RearAxleSteeringFunctionDsbl 100;
BA_ "GenSigStartValue" SG_ 2499757105 RearAxleSteeringFunctionDsbl 3;
BA_ "GenSigCycleTime" SG_ 2499757105 RollerBenchModeRequest 100;
BA_ "GenSigCycleTimeActive" SG_ 2499757105 RollerBenchModeRequest 100;
BA_ "GenSigStartValue" SG_ 2499757105 RollerBenchModeRequest 3;
BA_ "GenSigCycleTime" SG_ 2499757105 RearAxleDiffLockActvnDrvrReq 100;
BA_ "GenSigCycleTimeActive" SG_ 2499757105 RearAxleDiffLockActvnDrvrReq 100;
BA_ "GenSigStartValue" SG_ 2499757105 RearAxleDiffLockActvnDrvrReq 3;
BA_ "GenSigCycleTime" SG_ 2499757105 SplitBoxDifflockActvnDrvrRqst 100;
BA_ "GenSigCycleTimeActive" SG_ 2499757105 SplitBoxDifflockActvnDrvrRqst 100;
BA_ "GenSigStartValue" SG_ 2499757105 SplitBoxDifflockActvnDrvrRqst 3;
BA_ "GenSigMaxLatency" SG_ 2499757105 SplitBoxDifflockActvnDrvrRqst 20;
BA_ "GenSigCycleTime" SG_ 2499757105 TractionControlDriverRqst 100;
BA_ "GenSigCycleTimeActive" SG_ 2499757105 TractionControlDriverRqst 100;
BA_ "GenSigStartValue" SG_ 2499757105 TractionControlDriverRqst 7;
BA_ "GenSigCycleTime" SG_ 2499757105 RrInterAxlDiffLockActvnDrvrReq 100;
BA_ "GenSigCycleTimeActive" SG_ 2499757105 RrInterAxlDiffLockActvnDrvrReq 100;
BA_ "GenSigStartValue" SG_ 2499757105 RrInterAxlDiffLockActvnDrvrReq 3;
BA_ "GenSigCycleTime" SG_ 2499757105 ABSInhibitionRequest 100;
BA_ "GenSigCycleTimeActive" SG_ 2499757105 ABSInhibitionRequest 100;
BA_ "GenSigStartValue" SG_ 2499757105 ABSInhibitionRequest 3;
BA_ "GenSigCycleTime" SG_ 2566844689 CCActive 100;
BA_ "GenSigCycleTimeActive" SG_ 2566844689 CCActive 100;
BA_ "GenSigStartValue" SG_ 2566844689 CCActive 3;
BA_ "GenSigCycleTime" SG_ 2566844689 ClutchSwitch 100;
BA_ "GenSigCycleTimeActive" SG_ 2566844689 ClutchSwitch 100;
BA_ "GenSigStartValue" SG_ 2566844689 ClutchSwitch 3;
BA_ "GenSigCycleTime" SG_ 2566844689 WheelBasedVehicleSpeed 100;
BA_ "GenSigCycleTimeActive" SG_ 2566844689 WheelBasedVehicleSpeed 100;
BA_ "GenSigStartValue" SG_ 2566844689 WheelBasedVehicleSpeed 65535;
BA_ "GenSigCycleTime" SG_ 2566844689 BrakeSwitch 100;
BA_ "GenSigCycleTimeActive" SG_ 2566844689 BrakeSwitch 100;
BA_ "GenSigStartValue" SG_ 2566844689 BrakeSwitch 3;
BA_ "GenSigCycleTime" SG_ 2566748928 DPFSootLevel 100;
BA_ "GenSigCycleTimeActive" SG_ 2566748928 DPFSootLevel 100;
BA_ "GenSigStartValue" SG_ 2566748928 DPFSootLevel 255;
BA_ "GenSigCycleTime" SG_ 2565869312 Aftertreat1NOxConcOutlet 100;
BA_ "GenSigCycleTimeActive" SG_ 2565869312 Aftertreat1NOxConcOutlet 100;
BA_ "GenSigStartValue" SG_ 2565869312 Aftertreat1NOxConcOutlet 65535;
BA_ "GenSigCycleTime" SG_ 2566763008 DPFPressureDiff 100;
BA_ "GenSigCycleTimeActive" SG_ 2566763008 DPFPressureDiff 100;
BA_ "GenSigStartValue" SG_ 2566763008 DPFPressureDiff 65535;
BA_ "GenSigCycleTime" SG_ 2566763520 Aftertreatment1ExhaustTemp1 100;
BA_ "GenSigCycleTimeActive" SG_ 2566763520 Aftertreatment1ExhaustTemp1 100;
BA_ "GenSigStartValue" SG_ 2566763520 Aftertreatment1ExhaustTemp1 65535;
BA_ "GenSigCycleTime" SG_ 2565869056 EngineExhaust1NOx1 100;
BA_ "GenSigCycleTimeActive" SG_ 2565869056 EngineExhaust1NOx1 100;
BA_ "GenSigStartValue" SG_ 2565869056 EngineExhaust1NOx1 65535;
BA_ "GenSigCycleTime" SG_ 2566845713 AmbientAirTemperature 100;
BA_ "GenSigCycleTimeActive" SG_ 2566845713 AmbientAirTemperature 100;
BA_ "GenSigStartValue" SG_ 2566845713 AmbientAirTemperature 65535;
BA_ "GenSigCycleTime" SG_ 2566827537 ServiceBrakeAirPrsCircuit1 100;
BA_ "GenSigCycleTimeActive" SG_ 2566827537 ServiceBrakeAirPrsCircuit1 100;
BA_ "GenSigStartValue" SG_ 2566827537 ServiceBrakeAirPrsCircuit1 255;
BA_ "GenSigCycleTime" SG_ 2566827537 ServiceBrakeAirPrsCircuit2 100;
BA_ "GenSigCycleTimeActive" SG_ 2566827537 ServiceBrakeAirPrsCircuit2 100;
BA_ "GenSigStartValue" SG_ 2566827537 ServiceBrakeAirPrsCircuit2 255;
BA_ "GenSigCycleTime" SG_ 2566892605 LNGRestrictionStatus_V1Closed 100;
BA_ "GenSigCycleTimeActive" SG_ 2566892605 LNGRestrictionStatus_V1Closed 100;
BA_ "GenSigCycleTime" SG_ 2566892605 LNGRestrictionStatus_Spare4 100;
BA_ "GenSigCycleTimeActive" SG_ 2566892605 LNGRestrictionStatus_Spare4 100;
BA_ "GenSigCycleTime" SG_ 2566892605 LNGRestrictionStatus_Spare2 100;
BA_ "GenSigCycleTimeActive" SG_ 2566892605 LNGRestrictionStatus_Spare2 100;
BA_ "GenSigCycleTime" SG_ 2566892605 ACM_Available_Log 100;
BA_ "GenSigCycleTimeActive" SG_ 2566892605 ACM_Available_Log 100;
BA_ "GenSigStartValue" SG_ 2566892605 ACM_Available_Log 255;
BA_ "GenSigCycleTime" SG_ 2566892605 LNGRestrictionStatus_SInfo 100;
BA_ "GenSigCycleTimeActive" SG_ 2566892605 LNGRestrictionStatus_SInfo 100;
BA_ "GenSigStartValue" SG_ 2566892605 LNGRestrictionStatus_SInfo 3;
BA_ "GenSigCycleTime" SG_ 2566892605 LNGRestrictionStatus_Spare3 100;
BA_ "GenSigCycleTimeActive" SG_ 2566892605 LNGRestrictionStatus_Spare3 100;
BA_ "GenSigCycleTime" SG_ 2566892605 LNGRestrictionStatus_Spare1 100;
BA_ "GenSigCycleTimeActive" SG_ 2566892605 LNGRestrictionStatus_Spare1 100;
BA_ "GenSigCycleTime" SG_ 2566892605 LNGTimeToVent 100;
BA_ "GenSigCycleTimeActive" SG_ 2566892605 LNGTimeToVent 100;
BA_ "GenSigStartValue" SG_ 2566892605 LNGTimeToVent 65535;
BA_ "GenSigCycleTime" SG_ 2566892605 LNGRestrictionStatus_V2Closed 100;
BA_ "GenSigCycleTimeActive" SG_ 2566892605 LNGRestrictionStatus_V2Closed 100;
BA_ "GenSigCycleTime" SG_ 2566892093 LngSystemReadinessStat 100;
BA_ "GenSigCycleTimeActive" SG_ 2566892093 LngSystemReadinessStat 100;
BA_ "GenSigStartValue" SG_ 2566892093 LngSystemReadinessStat 7;
BA_ "GenSigCycleTime" SG_ 2566892093 MIStatusACM 100;
BA_ "GenSigCycleTimeActive" SG_ 2566892093 MIStatusACM 100;
BA_ "GenSigStartValue" SG_ 2566892093 MIStatusACM 3;
BA_ "GenSigCycleTime" SG_ 2566892093 LngTank1WarnStat 100;
BA_ "GenSigCycleTimeActive" SG_ 2566892093 LngTank1WarnStat 100;
BA_ "GenSigStartValue" SG_ 2566892093 LngTank1WarnStat 3;
BA_ "GenSigCycleTime" SG_ 2566892093 LngTank2WarnStat 100;
BA_ "GenSigCycleTimeActive" SG_ 2566892093 LngTank2WarnStat 100;
BA_ "GenSigStartValue" SG_ 2566892093 LngTank2WarnStat 3;
BA_ "GenSigCycleTime" SG_ 2566892093 LNGLevel 100;
BA_ "GenSigCycleTimeActive" SG_ 2566892093 LNGLevel 100;
BA_ "GenSigStartValue" SG_ 2566892093 LNGLevel 255;
BA_ "GenSigCycleTime" SG_ 2566892093 LngTank1RemainingGasVolume 100;
BA_ "GenSigCycleTimeActive" SG_ 2566892093 LngTank1RemainingGasVolume 100;
BA_ "GenSigStartValue" SG_ 2566892093 LngTank1RemainingGasVolume 255;
BA_ "GenSigCycleTime" SG_ 2566892093 AdBlueTankTemperature 100;
BA_ "GenSigCycleTimeActive" SG_ 2566892093 AdBlueTankTemperature 100;
BA_ "GenSigStartValue" SG_ 2566892093 AdBlueTankTemperature 255;
BA_ "GenSigCycleTime" SG_ 2566892093 CatalystTankLevelLow 100;
BA_ "GenSigCycleTimeActive" SG_ 2566892093 CatalystTankLevelLow 100;
BA_ "GenSigStartValue" SG_ 2566892093 CatalystTankLevelLow 3;
BA_ "GenSigCycleTime" SG_ 2566892093 CatalystTankLevel 100;
BA_ "GenSigCycleTimeActive" SG_ 2566892093 CatalystTankLevel 100;
BA_ "GenSigStartValue" SG_ 2566892093 CatalystTankLevel 255;
BA_ "GenSigCycleTime" SG_ 2566892093 LngTank2RemainingGasVolume 100;
BA_ "GenSigCycleTimeActive" SG_ 2566892093 LngTank2RemainingGasVolume 100;
BA_ "GenSigStartValue" SG_ 2566892093 LngTank2RemainingGasVolume 255;
BA_ "GenSigCycleTime" SG_ 2566892093 LngGspWarnStat 100;
BA_ "GenSigCycleTimeActive" SG_ 2566892093 LngGspWarnStat 100;
BA_ "GenSigStartValue" SG_ 2566892093 LngGspWarnStat 3;
BA_ "GenSigCycleTime" SG_ 2566892093 MIDistinctWarningACM 100;
BA_ "GenSigCycleTimeActive" SG_ 2566892093 MIDistinctWarningACM 100;
BA_ "GenSigStartValue" SG_ 2566892093 MIDistinctWarningACM 3;
BA_ "GenSigCycleTime" SG_ 2566892093 MIDistinctWarningExtACM 100;
BA_ "GenSigCycleTimeActive" SG_ 2566892093 MIDistinctWarningExtACM 100;
BA_ "GenSigStartValue" SG_ 2566892093 MIDistinctWarningExtACM 15;
BA_ "GenSigCycleTime" SG_ 2566892093 MIStatusExtACM 100;
BA_ "GenSigCycleTimeActive" SG_ 2566892093 MIStatusExtACM 100;
BA_ "GenSigStartValue" SG_ 2566892093 MIStatusExtACM 3;
BA_ "GenSigCycleTime" SG_ 2499624448 SCROutletTemp 100;
BA_ "GenSigCycleTimeActive" SG_ 2499624448 SCROutletTemp 100;
BA_ "GenSigStartValue" SG_ 2499624448 SCROutletTemp 65535;
BA_ "GenSigCycleTime" SG_ 2499624448 SCRInletTemp 100;
BA_ "GenSigCycleTimeActive" SG_ 2499624448 SCRInletTemp 100;
BA_ "GenSigStartValue" SG_ 2499624448 SCRInletTemp 65535;
BA_REL_ "GenSigFirstTimeoutTime" BU_SG_REL_ VCM SG_ 2566877707 Trailer2BrkLining_Warning 3000;
BA_REL_ "GenSigTimeoutTime" BU_SG_REL_ VCM SG_ 2566877707 Trailer2BrkLining_Warning 600;
BA_REL_ "GenSigFirstTimeoutTime" BU_SG_REL_ VCM SG_ 2566877707 Trailer2RampLevel_LvlPos 3000;
BA_REL_ "GenSigTimeoutTime" BU_SG_REL_ VCM SG_ 2566877707 Trailer2RampLevel_LvlPos 600;
BA_REL_ "GenSigFirstTimeoutTime" BU_SG_REL_ VCM SG_ 2566877707 Trailer2BrkLining_Wear 3000;
BA_REL_ "GenSigTimeoutTime" BU_SG_REL_ VCM SG_ 2566877707 Trailer2BrkLining_Wear 600;
BA_REL_ "GenSigFirstTimeoutTime" BU_SG_REL_ VCM SG_ 2566877707 Trailer2BrkLining_BrkLnTireId 3000;
BA_REL_ "GenSigTimeoutTime" BU_SG_REL_ VCM SG_ 2566877707 Trailer2BrkLining_BrkLnTireId 600;
BA_REL_ "GenSigFirstTimeoutTime" BU_SG_REL_ VCM SG_ 2566877707 Trailer2RampLevel_LvlStatus 3000;
BA_REL_ "GenSigTimeoutTime" BU_SG_REL_ VCM SG_ 2566877707 Trailer2RampLevel_LvlStatus 600;
BA_REL_ "GenSigFirstTimeoutTime" BU_SG_REL_ VCM SG_ 2566877707 Trailer2RelBodyLevel_RearLevel 3000;
BA_REL_ "GenSigTimeoutTime" BU_SG_REL_ VCM SG_ 2566877707 Trailer2RelBodyLevel_RearLevel 600;
BA_REL_ "GenSigFirstTimeoutTime" BU_SG_REL_ VCM SG_ 2566877707 Trailer2NormalLevel_LvlPos 3000;
BA_REL_ "GenSigTimeoutTime" BU_SG_REL_ VCM SG_ 2566877707 Trailer2NormalLevel_LvlPos 600;
BA_REL_ "GenSigFirstTimeoutTime" BU_SG_REL_ VCM SG_ 2566877707 Trailer2RelBodyLevel_FrontLevel 3000;
BA_REL_ "GenSigTimeoutTime" BU_SG_REL_ VCM SG_ 2566877707 Trailer2RelBodyLevel_FrontLevel 600;
BA_REL_ "GenSigFirstTimeoutTime" BU_SG_REL_ VCM SG_ 2566877707 Trailer2NormalLevel_LvlStatus 3000;
BA_REL_ "GenSigTimeoutTime" BU_SG_REL_ VCM SG_ 2566877707 Trailer2NormalLevel_LvlStatus 600;
BA_REL_ "GenSigFirstTimeoutTime" BU_SG_REL_ VCM SG_ 2566877451 Trailer1RelBodyLevel_FrontLevel 3000;
BA_REL_ "GenSigTimeoutTime" BU_SG_REL_ VCM SG_ 2566877451 Trailer1RelBodyLevel_FrontLevel 600;
BA_REL_ "GenSigFirstTimeoutTime" BU_SG_REL_ VCM SG_ 2566877451 Trailer1BrkLining_BrkLnTireId 3000;
BA_REL_ "GenSigTimeoutTime" BU_SG_REL_ VCM SG_ 2566877451 Trailer1BrkLining_BrkLnTireId 600;
BA_REL_ "GenSigFirstTimeoutTime" BU_SG_REL_ VCM SG_ 2566877451 Trailer1BrkLining_Wear 3000;
BA_REL_ "GenSigTimeoutTime" BU_SG_REL_ VCM SG_ 2566877451 Trailer1BrkLining_Wear 600;
BA_REL_ "GenSigFirstTimeoutTime" BU_SG_REL_ VCM SG_ 2566877451 Trailer1NormalLevel_LvlPos 3000;
BA_REL_ "GenSigTimeoutTime" BU_SG_REL_ VCM SG_ 2566877451 Trailer1NormalLevel_LvlPos 600;
BA_REL_ "GenSigFirstTimeoutTime" BU_SG_REL_ VCM SG_ 2566877451 Trailer1BrkLining_Warning 3000;
BA_REL_ "GenSigTimeoutTime" BU_SG_REL_ VCM SG_ 2566877451 Trailer1BrkLining_Warning 600;
BA_REL_ "GenSigFirstTimeoutTime" BU_SG_REL_ VCM SG_ 2566877451 Trailer1RampLevel_LvlPos 3000;
BA_REL_ "GenSigTimeoutTime" BU_SG_REL_ VCM SG_ 2566877451 Trailer1RampLevel_LvlPos 600;
BA_REL_ "GenSigFirstTimeoutTime" BU_SG_REL_ VCM SG_ 2566877451 Trailer1NormalLevel_LvlStatus 3000;
BA_REL_ "GenSigTimeoutTime" BU_SG_REL_ VCM SG_ 2566877451 Trailer1NormalLevel_LvlStatus 600;
BA_REL_ "GenSigFirstTimeoutTime" BU_SG_REL_ VCM SG_ 2566877451 Trailer1RampLevel_LvlStatus 3000;
BA_REL_ "GenSigTimeoutTime" BU_SG_REL_ VCM SG_ 2566877451 Trailer1RampLevel_LvlStatus 600;
BA_REL_ "GenSigFirstTimeoutTime" BU_SG_REL_ VCM SG_ 2566877451 Trailer1RelBodyLevel_RearLevel 3000;
BA_REL_ "GenSigTimeoutTime" BU_SG_REL_ VCM SG_ 2566877451 Trailer1RelBodyLevel_RearLevel 600;
BA_REL_ "GenSigFirstTimeoutTime" BU_SG_REL_ VCM SG_ 2566894859 Trailer5VIN 60000;
BA_REL_ "GenSigTimeoutTime" BU_SG_REL_ VCM SG_ 2566894859 Trailer5VIN 60000;
BA_REL_ "GenSigFirstTimeoutTime" BU_SG_REL_ VCM SG_ 2566894603 Trailer4VIN 60000;
BA_REL_ "GenSigTimeoutTime" BU_SG_REL_ VCM SG_ 2566894603 Trailer4VIN 60000;
BA_REL_ "GenSigFirstTimeoutTime" BU_SG_REL_ VCM SG_ 2566894347 Trailer3VIN 60000;
BA_REL_ "GenSigTimeoutTime" BU_SG_REL_ VCM SG_ 2566894347 Trailer3VIN 60000;
BA_REL_ "GenSigFirstTimeoutTime" BU_SG_REL_ VCM SG_ 2566894091 Trailer2VIN 60000;
BA_REL_ "GenSigTimeoutTime" BU_SG_REL_ VCM SG_ 2566894091 Trailer2VIN 60000;
BA_REL_ "GenSigFirstTimeoutTime" BU_SG_REL_ VCM SG_ 2566893835 Trailer1VIN 60000;
BA_REL_ "GenSigTimeoutTime" BU_SG_REL_ VCM SG_ 2566893835 Trailer1VIN 60000;
BA_REL_ "GenSigFirstTimeoutTime" BU_SG_REL_ VCM SG_ 2566903051 Trailer5GeometricData_Content 24000;
BA_REL_ "GenSigTimeoutTime" BU_SG_REL_ VCM SG_ 2566903051 Trailer5GeometricData_Content 6000;
BA_REL_ "GenSigFirstTimeoutTime" BU_SG_REL_ VCM SG_ 2566903051 Trailer5AxleLoadSum 24000;
BA_REL_ "GenSigTimeoutTime" BU_SG_REL_ VCM SG_ 2566903051 Trailer5AxleLoadSum 6000;
BA_REL_ "GenSigFirstTimeoutTime" BU_SG_REL_ TCM SG_ 2566903051 Trailer5AxleLoadSum 24000;
BA_REL_ "GenSigTimeoutTime" BU_SG_REL_ TCM SG_ 2566903051 Trailer5AxleLoadSum 6000;
BA_REL_ "GenSigFirstTimeoutTime" BU_SG_REL_ TCM SG_ 2566903051 XBRBrakingCapacityTemperature 24000;
BA_REL_ "GenSigTimeoutTime" BU_SG_REL_ TCM SG_ 2566903051 XBRBrakingCapacityTemperature 6000;
BA_REL_ "GenSigFirstTimeoutTime" BU_SG_REL_ ECM SG_ 2566903051 XBRBrakingCapacityTemperature 24000;
BA_REL_ "GenSigTimeoutTime" BU_SG_REL_ ECM SG_ 2566903051 XBRBrakingCapacityTemperature 6000;
BA_REL_ "GenSigFirstTimeoutTime" BU_SG_REL_ VCM SG_ 2566903051 XBRBrakingCapacityTemperature 24000;
BA_REL_ "GenSigTimeoutTime" BU_SG_REL_ VCM SG_ 2566903051 XBRBrakingCapacityTemperature 6000;
BA_REL_ "GenSigFirstTimeoutTime" BU_SG_REL_ VCM SG_ 2566903051 Trailer5GeometricData_Index 24000;
BA_REL_ "GenSigTimeoutTime" BU_SG_REL_ VCM SG_ 2566903051 Trailer5GeometricData_Index 6000;
BA_REL_ "GenSigFirstTimeoutTime" BU_SG_REL_ VCM SG_ 2566903051 LiningWearWarning 24000;
BA_REL_ "GenSigTimeoutTime" BU_SG_REL_ VCM SG_ 2566903051 LiningWearWarning 6000;
BA_REL_ "GenSigFirstTimeoutTime" BU_SG_REL_ VCM SG_ 2566903051 XBRBrakingCapacityTime 24000;
BA_REL_ "GenSigTimeoutTime" BU_SG_REL_ VCM SG_ 2566903051 XBRBrakingCapacityTime 6000;
BA_REL_ "GenSigFirstTimeoutTime" BU_SG_REL_ ECM SG_ 2566903051 XBRBrakingCapacityTime 24000;
BA_REL_ "GenSigTimeoutTime" BU_SG_REL_ ECM SG_ 2566903051 XBRBrakingCapacityTime 6000;
BA_REL_ "GenSigFirstTimeoutTime" BU_SG_REL_ TCM SG_ 2566903051 XBRBrakingCapacityTime 24000;
BA_REL_ "GenSigTimeoutTime" BU_SG_REL_ TCM SG_ 2566903051 XBRBrakingCapacityTime 6000;
BA_REL_ "GenSigFirstTimeoutTime" BU_SG_REL_ VCM SG_ 2566903051 PadChangePredictionAxleNumber 24000;
BA_REL_ "GenSigTimeoutTime" BU_SG_REL_ VCM SG_ 2566903051 PadChangePredictionAxleNumber 6000;
BA_REL_ "GenSigFirstTimeoutTime" BU_SG_REL_ TCM SG_ 2566902539 Trailer4AxleLoadSum 24000;
BA_REL_ "GenSigTimeoutTime" BU_SG_REL_ TCM SG_ 2566902539 Trailer4AxleLoadSum 6000;
BA_REL_ "GenSigFirstTimeoutTime" BU_SG_REL_ VCM SG_ 2566902539 Trailer4AxleLoadSum 24000;
BA_REL_ "GenSigTimeoutTime" BU_SG_REL_ VCM SG_ 2566902539 Trailer4AxleLoadSum 6000;
BA_REL_ "GenSigFirstTimeoutTime" BU_SG_REL_ VCM SG_ 2566902539 Trailer4GeometricData_Content 24000;
BA_REL_ "GenSigTimeoutTime" BU_SG_REL_ VCM SG_ 2566902539 Trailer4GeometricData_Content 6000;
BA_REL_ "GenSigFirstTimeoutTime" BU_SG_REL_ VCM SG_ 2566902539 Trailer4GeometricData_Index 24000;
BA_REL_ "GenSigTimeoutTime" BU_SG_REL_ VCM SG_ 2566902539 Trailer4GeometricData_Index 6000;
BA_REL_ "GenSigFirstTimeoutTime" BU_SG_REL_ VCM SG_ 2566902539 Trailer3GeometricData_Index 24000;
BA_REL_ "GenSigTimeoutTime" BU_SG_REL_ VCM SG_ 2566902539 Trailer3GeometricData_Index 6000;
BA_REL_ "GenSigFirstTimeoutTime" BU_SG_REL_ VCM SG_ 2566902539 Trailer3GeometricData_Content 24000;
BA_REL_ "GenSigTimeoutTime" BU_SG_REL_ VCM SG_ 2566902539 Trailer3GeometricData_Content 6000;
BA_REL_ "GenSigFirstTimeoutTime" BU_SG_REL_ VCM SG_ 2566902539 Trailer3AxleLoadSum 24000;
BA_REL_ "GenSigTimeoutTime" BU_SG_REL_ VCM SG_ 2566902539 Trailer3AxleLoadSum 6000;
BA_REL_ "GenSigFirstTimeoutTime" BU_SG_REL_ TCM SG_ 2566902539 Trailer3AxleLoadSum 24000;
BA_REL_ "GenSigTimeoutTime" BU_SG_REL_ TCM SG_ 2566902539 Trailer3AxleLoadSum 6000;
BA_REL_ "GenSigFirstTimeoutTime" BU_SG_REL_ TCM SG_ 2566902027 Trailer1AxleLoadSum 24000;
BA_REL_ "GenSigTimeoutTime" BU_SG_REL_ TCM SG_ 2566902027 Trailer1AxleLoadSum 6000;
BA_REL_ "GenSigFirstTimeoutTime" BU_SG_REL_ VCM SG_ 2566902027 Trailer1AxleLoadSum 24000;
BA_REL_ "GenSigTimeoutTime" BU_SG_REL_ VCM SG_ 2566902027 Trailer1AxleLoadSum 6000;
BA_REL_ "GenSigFirstTimeoutTime" BU_SG_REL_ VCM SG_ 2566902027 Trailer2GeometricData_Content 24000;
BA_REL_ "GenSigTimeoutTime" BU_SG_REL_ VCM SG_ 2566902027 Trailer2GeometricData_Content 6000;
BA_REL_ "GenSigFirstTimeoutTime" BU_SG_REL_ VCM SG_ 2566902027 Trailer2AxleLoadSum 24000;
BA_REL_ "GenSigTimeoutTime" BU_SG_REL_ VCM SG_ 2566902027 Trailer2AxleLoadSum 6000;
BA_REL_ "GenSigFirstTimeoutTime" BU_SG_REL_ TCM SG_ 2566902027 Trailer2AxleLoadSum 24000;
BA_REL_ "GenSigTimeoutTime" BU_SG_REL_ TCM SG_ 2566902027 Trailer2AxleLoadSum 6000;
BA_REL_ "GenSigFirstTimeoutTime" BU_SG_REL_ VCM SG_ 2566902027 Trailer2GeometricData_Index 24000;
BA_REL_ "GenSigTimeoutTime" BU_SG_REL_ VCM SG_ 2566902027 Trailer2GeometricData_Index 6000;
BA_REL_ "GenSigFirstTimeoutTime" BU_SG_REL_ VCM SG_ 2566902027 Trailer1GeometricData_Content 24000;
BA_REL_ "GenSigTimeoutTime" BU_SG_REL_ VCM SG_ 2566902027 Trailer1GeometricData_Content 6000;
BA_REL_ "GenSigFirstTimeoutTime" BU_SG_REL_ VCM SG_ 2566902027 Trailer1GeometricData_Index 24000;
BA_REL_ "GenSigTimeoutTime" BU_SG_REL_ VCM SG_ 2566902027 Trailer1GeometricData_Index 6000;
BA_REL_ "GenSigFirstTimeoutTime" BU_SG_REL_ TCM SG_ 2566886667 Trailer5AxleLoad_AxleLoad 3000;
BA_REL_ "GenSigTimeoutTime" BU_SG_REL_ TCM SG_ 2566886667 Trailer5AxleLoad_AxleLoad 600;
BA_REL_ "GenSigFirstTimeoutTime" BU_SG_REL_ VCM SG_ 2566886667 Trailer5AxleLoad_AxleLoad 3000;
BA_REL_ "GenSigTimeoutTime" BU_SG_REL_ VCM SG_ 2566886667 Trailer5AxleLoad_AxleLoad 600;
BA_REL_ "GenSigFirstTimeoutTime" BU_SG_REL_ VCM SG_ 2566886667 Trailer5LiftAxle1Pos 3000;
BA_REL_ "GenSigTimeoutTime" BU_SG_REL_ VCM SG_ 2566886667 Trailer5LiftAxle1Pos 600;
BA_REL_ "GenSigFirstTimeoutTime" BU_SG_REL_ VCM SG_ 2566886667 Trailer5LiftAxle2Pos 3000;
BA_REL_ "GenSigTimeoutTime" BU_SG_REL_ VCM SG_ 2566886667 Trailer5LiftAxle2Pos 600;
BA_REL_ "GenSigFirstTimeoutTime" BU_SG_REL_ VCM SG_ 2566886667 Trailer5AxleLoad_AxleId 3000;
BA_REL_ "GenSigTimeoutTime" BU_SG_REL_ VCM SG_ 2566886667 Trailer5AxleLoad_AxleId 600;
BA_REL_ "GenSigFirstTimeoutTime" BU_SG_REL_ TCM SG_ 2566886667 Trailer5AxleLoad_AxleId 3000;
BA_REL_ "GenSigTimeoutTime" BU_SG_REL_ TCM SG_ 2566886667 Trailer5AxleLoad_AxleId 600;
BA_REL_ "GenSigFirstTimeoutTime" BU_SG_REL_ VCM SG_ 2566886155 Trailer4LiftAxle2Pos 3000;
BA_REL_ "GenSigTimeoutTime" BU_SG_REL_ VCM SG_ 2566886155 Trailer4LiftAxle2Pos 600;
BA_REL_ "GenSigFirstTimeoutTime" BU_SG_REL_ VCM SG_ 2566886155 Trailer4LiftAxle1Pos 3000;
BA_REL_ "GenSigTimeoutTime" BU_SG_REL_ VCM SG_ 2566886155 Trailer4LiftAxle1Pos 600;
BA_REL_ "GenSigFirstTimeoutTime" BU_SG_REL_ VCM SG_ 2566886155 Trailer3LiftAxle1Pos 3000;
BA_REL_ "GenSigTimeoutTime" BU_SG_REL_ VCM SG_ 2566886155 Trailer3LiftAxle1Pos 600;
BA_REL_ "GenSigFirstTimeoutTime" BU_SG_REL_ VCM SG_ 2566886155 Trailer4AxleLoad_AxleLoad 3000;
BA_REL_ "GenSigTimeoutTime" BU_SG_REL_ VCM SG_ 2566886155 Trailer4AxleLoad_AxleLoad 600;
BA_REL_ "GenSigFirstTimeoutTime" BU_SG_REL_ TCM SG_ 2566886155 Trailer4AxleLoad_AxleLoad 3000;
BA_REL_ "GenSigTimeoutTime" BU_SG_REL_ TCM SG_ 2566886155 Trailer4AxleLoad_AxleLoad 600;
BA_REL_ "GenSigFirstTimeoutTime" BU_SG_REL_ TCM SG_ 2566886155 Trailer3AxleLoad_AxleLoad 3000;
BA_REL_ "GenSigTimeoutTime" BU_SG_REL_ TCM SG_ 2566886155 Trailer3AxleLoad_AxleLoad 600;
BA_REL_ "GenSigFirstTimeoutTime" BU_SG_REL_ VCM SG_ 2566886155 Trailer3AxleLoad_AxleLoad 3000;
BA_REL_ "GenSigTimeoutTime" BU_SG_REL_ VCM SG_ 2566886155 Trailer3AxleLoad_AxleLoad 600;
BA_REL_ "GenSigFirstTimeoutTime" BU_SG_REL_ TCM SG_ 2566886155 Trailer3AxleLoad_AxleId 3000;
BA_REL_ "GenSigTimeoutTime" BU_SG_REL_ TCM SG_ 2566886155 Trailer3AxleLoad_AxleId 600;
BA_REL_ "GenSigFirstTimeoutTime" BU_SG_REL_ VCM SG_ 2566886155 Trailer3AxleLoad_AxleId 3000;
BA_REL_ "GenSigTimeoutTime" BU_SG_REL_ VCM SG_ 2566886155 Trailer3AxleLoad_AxleId 600;
BA_REL_ "GenSigFirstTimeoutTime" BU_SG_REL_ VCM SG_ 2566886155 Trailer4AxleLoad_AxleId 3000;
BA_REL_ "GenSigTimeoutTime" BU_SG_REL_ VCM SG_ 2566886155 Trailer4AxleLoad_AxleId 600;
BA_REL_ "GenSigFirstTimeoutTime" BU_SG_REL_ TCM SG_ 2566886155 Trailer4AxleLoad_AxleId 3000;
BA_REL_ "GenSigTimeoutTime" BU_SG_REL_ TCM SG_ 2566886155 Trailer4AxleLoad_AxleId 600;
BA_REL_ "GenSigFirstTimeoutTime" BU_SG_REL_ VCM SG_ 2566886155 Trailer3LiftAxle2Pos 3000;
BA_REL_ "GenSigTimeoutTime" BU_SG_REL_ VCM SG_ 2566886155 Trailer3LiftAxle2Pos 600;
BA_REL_ "GenSigFirstTimeoutTime" BU_SG_REL_ VCM SG_ 2566885643 Trailer2LiftAxle2Pos 3000;
BA_REL_ "GenSigTimeoutTime" BU_SG_REL_ VCM SG_ 2566885643 Trailer2LiftAxle2Pos 600;
BA_REL_ "GenSigFirstTimeoutTime" BU_SG_REL_ VCM SG_ 2566885643 Trailer1AxleLoad_AxleLoad 3000;
BA_REL_ "GenSigTimeoutTime" BU_SG_REL_ VCM SG_ 2566885643 Trailer1AxleLoad_AxleLoad 600;
BA_REL_ "GenSigFirstTimeoutTime" BU_SG_REL_ TCM SG_ 2566885643 Trailer1AxleLoad_AxleLoad 3000;
BA_REL_ "GenSigTimeoutTime" BU_SG_REL_ TCM SG_ 2566885643 Trailer1AxleLoad_AxleLoad 600;
BA_REL_ "GenSigFirstTimeoutTime" BU_SG_REL_ VCM SG_ 2566885643 Trailer2AxleLoad_AxleLoad 3000;
BA_REL_ "GenSigTimeoutTime" BU_SG_REL_ VCM SG_ 2566885643 Trailer2AxleLoad_AxleLoad 600;
BA_REL_ "GenSigFirstTimeoutTime" BU_SG_REL_ TCM SG_ 2566885643 Trailer2AxleLoad_AxleLoad 3000;
BA_REL_ "GenSigTimeoutTime" BU_SG_REL_ TCM SG_ 2566885643 Trailer2AxleLoad_AxleLoad 600;
BA_REL_ "GenSigFirstTimeoutTime" BU_SG_REL_ VCM SG_ 2566885643 Trailer1AxleLoad_AxleId 3000;
BA_REL_ "GenSigTimeoutTime" BU_SG_REL_ VCM SG_ 2566885643 Trailer1AxleLoad_AxleId 600;
BA_REL_ "GenSigFirstTimeoutTime" BU_SG_REL_ TCM SG_ 2566885643 Trailer1AxleLoad_AxleId 3000;
BA_REL_ "GenSigTimeoutTime" BU_SG_REL_ TCM SG_ 2566885643 Trailer1AxleLoad_AxleId 600;
BA_REL_ "GenSigFirstTimeoutTime" BU_SG_REL_ VCM SG_ 2566885643 Trailer2LiftAxle1Pos 3000;
BA_REL_ "GenSigTimeoutTime" BU_SG_REL_ VCM SG_ 2566885643 Trailer2LiftAxle1Pos 600;
BA_REL_ "GenSigFirstTimeoutTime" BU_SG_REL_ VCM SG_ 2566885643 TrailerEBSFault 3000;
BA_REL_ "GenSigTimeoutTime" BU_SG_REL_ VCM SG_ 2566885643 TrailerEBSFault 600;
BA_REL_ "GenSigFirstTimeoutTime" BU_SG_REL_ VCM SG_ 2566885643 Trailer2AxleLoad_AxleId 3000;
BA_REL_ "GenSigTimeoutTime" BU_SG_REL_ VCM SG_ 2566885643 Trailer2AxleLoad_AxleId 600;
BA_REL_ "GenSigFirstTimeoutTime" BU_SG_REL_ TCM SG_ 2566885643 Trailer2AxleLoad_AxleId 3000;
BA_REL_ "GenSigTimeoutTime" BU_SG_REL_ TCM SG_ 2566885643 Trailer2AxleLoad_AxleId 600;
BA_REL_ "GenSigFirstTimeoutTime" BU_SG_REL_ TCM SG_ 2566885643 TrailersConnected 3000;
BA_REL_ "GenSigTimeoutTime" BU_SG_REL_ TCM SG_ 2566885643 TrailersConnected 600;
BA_REL_ "GenSigFirstTimeoutTime" BU_SG_REL_ VCM SG_ 2566885643 TrailersConnected 3000;
BA_REL_ "GenSigTimeoutTime" BU_SG_REL_ VCM SG_ 2566885643 TrailersConnected 600;
BA_REL_ "GenSigFirstTimeoutTime" BU_SG_REL_ VCM SG_ 2566906635 PadChgPredictionLastPadChg 48000;
BA_REL_ "GenSigTimeoutTime" BU_SG_REL_ VCM SG_ 2566906635 PadChgPredictionLastPadChg 12000;
BA_REL_ "GenSigFirstTimeoutTime" BU_SG_REL_ VCM SG_ 2566906635 PredictedMileageOfNextPadChg 48000;
BA_REL_ "GenSigTimeoutTime" BU_SG_REL_ VCM SG_ 2566906635 PredictedMileageOfNextPadChg 12000;
BA_REL_ "GenSigFirstTimeoutTime" BU_SG_REL_ VCM SG_ 2499761675 RearAxleDiffLockActvnFuncReq 3000;
BA_REL_ "GenSigTimeoutTime" BU_SG_REL_ VCM SG_ 2499761675 RearAxleDiffLockActvnFuncReq 300;
BA_REL_ "GenSigFirstTimeoutTime" BU_SG_REL_ VCM SG_ 2499761675 PoorBrakePerformanceWarning 3000;
BA_REL_ "GenSigTimeoutTime" BU_SG_REL_ VCM SG_ 2499761675 PoorBrakePerformanceWarning 300;
BA_REL_ "GenSigFirstTimeoutTime" BU_SG_REL_ VCM SG_ 2499761675 TrcnCtrlSlipperyRoadWarning 3000;
BA_REL_ "GenSigTimeoutTime" BU_SG_REL_ VCM SG_ 2499761675 TrcnCtrlSlipperyRoadWarning 300;
BA_REL_ "GenSigFirstTimeoutTime" BU_SG_REL_ VCM SG_ 2499761675 DTCActive 3000;
BA_REL_ "GenSigTimeoutTime" BU_SG_REL_ VCM SG_ 2499761675 DTCActive 300;
BA_REL_ "GenSigFirstTimeoutTime" BU_SG_REL_ VCM SG_ 2499761675 AutoRearAxleDiffLockFnc_stat 3000;
BA_REL_ "GenSigTimeoutTime" BU_SG_REL_ VCM SG_ 2499761675 AutoRearAxleDiffLockFnc_stat 300;
BA_REL_ "GenSigFirstTimeoutTime" BU_SG_REL_ VCM SG_ 2499761675 TractionFunctionSelected 3000;
BA_REL_ "GenSigTimeoutTime" BU_SG_REL_ VCM SG_ 2499761675 TractionFunctionSelected 300;
BA_REL_ "GenSigFirstTimeoutTime" BU_SG_REL_ VCM SG_ 2499761675 BrakeTempWarningLevel 3000;
BA_REL_ "GenSigTimeoutTime" BU_SG_REL_ VCM SG_ 2499761675 BrakeTempWarningLevel 300;
BA_REL_ "GenSigFirstTimeoutTime" BU_SG_REL_ ECM SG_ 2499761675 BrakeTempWarningLevel 3000;
BA_REL_ "GenSigTimeoutTime" BU_SG_REL_ ECM SG_ 2499761675 BrakeTempWarningLevel 300;
BA_REL_ "GenSigFirstTimeoutTime" BU_SG_REL_ TCM SG_ 2499761675 BrakeTempWarningLevel 3000;
BA_REL_ "GenSigTimeoutTime" BU_SG_REL_ TCM SG_ 2499761675 BrakeTempWarningLevel 300;
BA_REL_ "GenSigFirstTimeoutTime" BU_SG_REL_ TCM SG_ 2499761675 ABSInhibitionStatus 3000;
BA_REL_ "GenSigTimeoutTime" BU_SG_REL_ TCM SG_ 2499761675 ABSInhibitionStatus 240;
BA_REL_ "GenSigFirstTimeoutTime" BU_SG_REL_ VCM SG_ 2499761675 ABSInhibitionStatus 3000;
BA_REL_ "GenSigTimeoutTime" BU_SG_REL_ VCM SG_ 2499761675 ABSInhibitionStatus 300;
BA_REL_ "GenSigFirstTimeoutTime" BU_SG_REL_ VCM SG_ 2499761675 ABSManAutoInhibitionStat 3000;
BA_REL_ "GenSigTimeoutTime" BU_SG_REL_ VCM SG_ 2499761675 ABSManAutoInhibitionStat 300;
BA_REL_ "GenSigFirstTimeoutTime" BU_SG_REL_ VCM SG_ 2499761675 VDCActive 3000;
BA_REL_ "GenSigTimeoutTime" BU_SG_REL_ VCM SG_ 2499761675 VDCActive 300;
BA_REL_ "GenSigFirstTimeoutTime" BU_SG_REL_ VCM SG_ 2499761675 RearAxleSteeringFunctionStatus 3000;
BA_REL_ "GenSigTimeoutTime" BU_SG_REL_ VCM SG_ 2499761675 RearAxleSteeringFunctionStatus 300;
BA_REL_ "GenSigFirstTimeoutTime" BU_SG_REL_ TCM SG_ 2499761675 HSAAvailability 3000;
BA_REL_ "GenSigTimeoutTime" BU_SG_REL_ TCM SG_ 2499761675 HSAAvailability 240;
BA_REL_ "GenSigFirstTimeoutTime" BU_SG_REL_ VCM SG_ 2499761675 HSAAvailability 3000;
BA_REL_ "GenSigTimeoutTime" BU_SG_REL_ VCM SG_ 2499761675 HSAAvailability 300;
BA_REL_ "GenSigFirstTimeoutTime" BU_SG_REL_ VCM SG_ 2499761675 RollerBenchModeStatus 3000;
BA_REL_ "GenSigTimeoutTime" BU_SG_REL_ VCM SG_ 2499761675 RollerBenchModeStatus 300;
BA_REL_ "GenSigFirstTimeoutTime" BU_SG_REL_ VCM SG_ 2499761675 BrakeAssistStatus 3000;
BA_REL_ "GenSigTimeoutTime" BU_SG_REL_ VCM SG_ 2499761675 BrakeAssistStatus 300;
BA_REL_ "GenSigFirstTimeoutTime" BU_SG_REL_ TCM SG_ 2499750411 XBRSystemInformation 3000;
BA_REL_ "GenSigTimeoutTime" BU_SG_REL_ TCM SG_ 2499750411 XBRSystemInformation 300;
BA_REL_ "GenSigFirstTimeoutTime" BU_SG_REL_ ECM SG_ 2499750411 XBRSystemInformation 3000;
BA_REL_ "GenSigTimeoutTime" BU_SG_REL_ ECM SG_ 2499750411 XBRSystemInformation 300;
BA_REL_ "GenSigFirstTimeoutTime" BU_SG_REL_ VCM SG_ 2499750411 XBRSystemInformation 3000;
BA_REL_ "GenSigTimeoutTime" BU_SG_REL_ VCM SG_ 2499750411 XBRSystemInformation 300;
BA_REL_ "GenSigFirstTimeoutTime" BU_SG_REL_ VCM SG_ 2499750411 BrakePedalTestState 3000;
BA_REL_ "GenSigTimeoutTime" BU_SG_REL_ VCM SG_ 2499750411 BrakePedalTestState 300;
BA_REL_ "GenSigFirstTimeoutTime" BU_SG_REL_ VCM SG_ 2499750411 HillStartAidStatus 3000;
BA_REL_ "GenSigTimeoutTime" BU_SG_REL_ VCM SG_ 2499750411 HillStartAidStatus 300;
BA_REL_ "GenSigFirstTimeoutTime" BU_SG_REL_ VCM SG_ 2499750411 SasAdaptationInProgress 3000;
BA_REL_ "GenSigTimeoutTime" BU_SG_REL_ VCM SG_ 2499750411 SasAdaptationInProgress 300;
BA_REL_ "GenSigFirstTimeoutTime" BU_SG_REL_ VCM SG_ 2499750411 ESCStatus 3000;
BA_REL_ "GenSigTimeoutTime" BU_SG_REL_ VCM SG_ 2499750411 ESCStatus 300;
BA_REL_ "GenSigFirstTimeoutTime" BU_SG_REL_ TCM SG_ 2499750411 HillHolderMode 3000;
BA_REL_ "GenSigTimeoutTime" BU_SG_REL_ TCM SG_ 2499750411 HillHolderMode 300;
BA_REL_ "GenSigFirstTimeoutTime" BU_SG_REL_ VCM SG_ 2499750411 ESCState 3000;
BA_REL_ "GenSigTimeoutTime" BU_SG_REL_ VCM SG_ 2499750411 ESCState 300;
BA_REL_ "GenSigFirstTimeoutTime" BU_SG_REL_ TCM SG_ 2499750411 ABSOffRoadStatus 3000;
BA_REL_ "GenSigTimeoutTime" BU_SG_REL_ TCM SG_ 2499750411 ABSOffRoadStatus 300;
BA_REL_ "GenSigFirstTimeoutTime" BU_SG_REL_ VCM SG_ 2499750411 ABSOffRoadStatus 3000;
BA_REL_ "GenSigTimeoutTime" BU_SG_REL_ VCM SG_ 2499750411 ABSOffRoadStatus 300;
BA_REL_ "GenSigFirstTimeoutTime" BU_SG_REL_ VCM SG_ 2499750411 TrailerCorrectionPressure 3000;
BA_REL_ "GenSigTimeoutTime" BU_SG_REL_ VCM SG_ 2499750411 TrailerCorrectionPressure 300;
BA_REL_ "GenSigFirstTimeoutTime" BU_SG_REL_ VCM SG_ 2499750411 RoadSpeedInformation 3000;
BA_REL_ "GenSigTimeoutTime" BU_SG_REL_ VCM SG_ 2499750411 RoadSpeedInformation 300;
BA_REL_ "GenSigFirstTimeoutTime" BU_SG_REL_ VCM SG_ 2566767627 BrakeTemperatureWarning 3000;
BA_REL_ "GenSigTimeoutTime" BU_SG_REL_ VCM SG_ 2566767627 BrakeTemperatureWarning 600;
BA_REL_ "GenSigFirstTimeoutTime" BU_SG_REL_ ECM SG_ 2566767627 FoundationBrakeUse 3000;
BA_REL_ "GenSigTimeoutTime" BU_SG_REL_ ECM SG_ 2566767627 FoundationBrakeUse 600;
BA_REL_ "GenSigFirstTimeoutTime" BU_SG_REL_ TCM SG_ 2566767627 FoundationBrakeUse 3000;
BA_REL_ "GenSigTimeoutTime" BU_SG_REL_ TCM SG_ 2566767627 FoundationBrakeUse 600;
BA_REL_ "GenSigFirstTimeoutTime" BU_SG_REL_ VCM SG_ 2566767627 FoundationBrakeUse 3000;
BA_REL_ "GenSigTimeoutTime" BU_SG_REL_ VCM SG_ 2566767627 FoundationBrakeUse 600;
BA_REL_ "GenSigFirstTimeoutTime" BU_SG_REL_ TCM SG_ 2566767627 XBRActiveControlMode 3000;
BA_REL_ "GenSigTimeoutTime" BU_SG_REL_ TCM SG_ 2566767627 XBRActiveControlMode 600;
BA_REL_ "GenSigFirstTimeoutTime" BU_SG_REL_ ECM SG_ 2566767627 XBRActiveControlMode 3000;
BA_REL_ "GenSigTimeoutTime" BU_SG_REL_ ECM SG_ 2566767627 XBRActiveControlMode 600;
BA_REL_ "GenSigFirstTimeoutTime" BU_SG_REL_ VCM SG_ 2566767627 XBRActiveControlMode 3000;
BA_REL_ "GenSigTimeoutTime" BU_SG_REL_ VCM SG_ 2566767627 XBRActiveControlMode 600;
BA_REL_ "GenSigFirstTimeoutTime" BU_SG_REL_ ECM SG_ 2566767627 XBRSystemState 3000;
BA_REL_ "GenSigTimeoutTime" BU_SG_REL_ ECM SG_ 2566767627 XBRSystemState 600;
BA_REL_ "GenSigFirstTimeoutTime" BU_SG_REL_ TCM SG_ 2566767627 XBRSystemState 3000;
BA_REL_ "GenSigTimeoutTime" BU_SG_REL_ TCM SG_ 2566767627 XBRSystemState 600;
BA_REL_ "GenSigFirstTimeoutTime" BU_SG_REL_ VCM SG_ 2566767627 EPBHillHolderMode 3000;
BA_REL_ "GenSigTimeoutTime" BU_SG_REL_ VCM SG_ 2566767627 EPBHillHolderMode 600;
BA_REL_ "GenSigFirstTimeoutTime" BU_SG_REL_ TCM SG_ 2566767627 EPBHillHolderMode 3000;
BA_REL_ "GenSigTimeoutTime" BU_SG_REL_ TCM SG_ 2566767627 EPBHillHolderMode 600;
BA_REL_ "GenSigFirstTimeoutTime" BU_SG_REL_ TCM SG_ 2499723019 RrAxle1RightWheelRelativeSpeed 3000;
BA_REL_ "GenSigTimeoutTime" BU_SG_REL_ TCM SG_ 2499723019 RrAxle1RightWheelRelativeSpeed 240;
BA_REL_ "GenSigFirstTimeoutTime" BU_SG_REL_ VCM SG_ 2499723019 RrAxle1RightWheelRelativeSpeed 3000;
BA_REL_ "GenSigTimeoutTime" BU_SG_REL_ VCM SG_ 2499723019 RrAxle1RightWheelRelativeSpeed 240;
BA_REL_ "GenSigFirstTimeoutTime" BU_SG_REL_ VCM SG_ 2499723019 FrAxleRightWheelRelativeSpeed 3000;
BA_REL_ "GenSigTimeoutTime" BU_SG_REL_ VCM SG_ 2499723019 FrAxleRightWheelRelativeSpeed 240;
BA_REL_ "GenSigFirstTimeoutTime" BU_SG_REL_ TCM SG_ 2499723019 FrAxleRightWheelRelativeSpeed 3000;
BA_REL_ "GenSigTimeoutTime" BU_SG_REL_ TCM SG_ 2499723019 FrAxleRightWheelRelativeSpeed 240;
BA_REL_ "GenSigFirstTimeoutTime" BU_SG_REL_ TCM SG_ 2499723019 RrAxle2LeftWheelRelativeSpeed 3000;
BA_REL_ "GenSigTimeoutTime" BU_SG_REL_ TCM SG_ 2499723019 RrAxle2LeftWheelRelativeSpeed 240;
BA_REL_ "GenSigFirstTimeoutTime" BU_SG_REL_ VCM SG_ 2499723019 RrAxle2LeftWheelRelativeSpeed 3000;
BA_REL_ "GenSigTimeoutTime" BU_SG_REL_ VCM SG_ 2499723019 RrAxle2LeftWheelRelativeSpeed 240;
BA_REL_ "GenSigFirstTimeoutTime" BU_SG_REL_ VCM SG_ 2499723019 FrontAxleSpeed 3000;
BA_REL_ "GenSigTimeoutTime" BU_SG_REL_ VCM SG_ 2499723019 FrontAxleSpeed 240;
BA_REL_ "GenSigFirstTimeoutTime" BU_SG_REL_ ECM SG_ 2499723019 FrontAxleSpeed 3000;
BA_REL_ "GenSigTimeoutTime" BU_SG_REL_ ECM SG_ 2499723019 FrontAxleSpeed 300;
BA_REL_ "GenSigFirstTimeoutTime" BU_SG_REL_ TCM SG_ 2499723019 FrontAxleSpeed 3000;
BA_REL_ "GenSigTimeoutTime" BU_SG_REL_ TCM SG_ 2499723019 FrontAxleSpeed 240;
BA_REL_ "GenSigFirstTimeoutTime" BU_SG_REL_ TCM SG_ 2499723019 FrAxleLeftWheelRelativeSpeed 3000;
BA_REL_ "GenSigTimeoutTime" BU_SG_REL_ TCM SG_ 2499723019 FrAxleLeftWheelRelativeSpeed 240;
BA_REL_ "GenSigFirstTimeoutTime" BU_SG_REL_ VCM SG_ 2499723019 FrAxleLeftWheelRelativeSpeed 3000;
BA_REL_ "GenSigTimeoutTime" BU_SG_REL_ VCM SG_ 2499723019 FrAxleLeftWheelRelativeSpeed 240;
BA_REL_ "GenSigFirstTimeoutTime" BU_SG_REL_ TCM SG_ 2499723019 RrAxle1LeftWheelRelativeSpeed 3000;
BA_REL_ "GenSigTimeoutTime" BU_SG_REL_ TCM SG_ 2499723019 RrAxle1LeftWheelRelativeSpeed 240;
BA_REL_ "GenSigFirstTimeoutTime" BU_SG_REL_ VCM SG_ 2499723019 RrAxle1LeftWheelRelativeSpeed 3000;
BA_REL_ "GenSigTimeoutTime" BU_SG_REL_ VCM SG_ 2499723019 RrAxle1LeftWheelRelativeSpeed 240;
BA_REL_ "GenSigFirstTimeoutTime" BU_SG_REL_ VCM SG_ 2499723019 RrAxle2RightWheelRelativeSpeed 3000;
BA_REL_ "GenSigTimeoutTime" BU_SG_REL_ VCM SG_ 2499723019 RrAxle2RightWheelRelativeSpeed 240;
BA_REL_ "GenSigFirstTimeoutTime" BU_SG_REL_ TCM SG_ 2499723019 RrAxle2RightWheelRelativeSpeed 3000;
BA_REL_ "GenSigTimeoutTime" BU_SG_REL_ TCM SG_ 2499723019 RrAxle2RightWheelRelativeSpeed 240;
BA_REL_ "GenSigFirstTimeoutTime" BU_SG_REL_ ECM SG_ 2565865739 ASREngineControlActive 3000;
BA_REL_ "GenSigTimeoutTime" BU_SG_REL_ ECM SG_ 2565865739 ASREngineControlActive 600;
BA_REL_ "GenSigFirstTimeoutTime" BU_SG_REL_ VCM SG_ 2565865739 ASREngineControlActive 3000;
BA_REL_ "GenSigTimeoutTime" BU_SG_REL_ VCM SG_ 2565865739 ASREngineControlActive 600;
BA_REL_ "GenSigFirstTimeoutTime" BU_SG_REL_ TCM SG_ 2565865739 ASREngineControlActive 3000;
BA_REL_ "GenSigTimeoutTime" BU_SG_REL_ TCM SG_ 2565865739 ASREngineControlActive 600;
BA_REL_ "GenSigFirstTimeoutTime" BU_SG_REL_ VCM SG_ 2565865739 ASRBrakeControlActive 3000;
BA_REL_ "GenSigTimeoutTime" BU_SG_REL_ VCM SG_ 2565865739 ASRBrakeControlActive 600;
BA_REL_ "GenSigFirstTimeoutTime" BU_SG_REL_ TCM SG_ 2565865739 ASRBrakeControlActive 3000;
BA_REL_ "GenSigTimeoutTime" BU_SG_REL_ TCM SG_ 2565865739 ASRBrakeControlActive 600;
BA_REL_ "GenSigFirstTimeoutTime" BU_SG_REL_ ECM SG_ 2565865739 ASRBrakeControlActive 3000;
BA_REL_ "GenSigTimeoutTime" BU_SG_REL_ ECM SG_ 2565865739 ASRBrakeControlActive 600;
BA_REL_ "GenSigFirstTimeoutTime" BU_SG_REL_ ECM SG_ 2565865739 ABSFullyOperational 3000;
BA_REL_ "GenSigTimeoutTime" BU_SG_REL_ ECM SG_ 2565865739 ABSFullyOperational 600;
BA_REL_ "GenSigFirstTimeoutTime" BU_SG_REL_ TCM SG_ 2565865739 ABSFullyOperational 3000;
BA_REL_ "GenSigTimeoutTime" BU_SG_REL_ TCM SG_ 2565865739 ABSFullyOperational 600;
BA_REL_ "GenSigFirstTimeoutTime" BU_SG_REL_ VCM SG_ 2565865739 ABSFullyOperational 3000;
BA_REL_ "GenSigTimeoutTime" BU_SG_REL_ VCM SG_ 2565865739 ABSFullyOperational 600;
BA_REL_ "GenSigFirstTimeoutTime" BU_SG_REL_ VCM SG_ 2565865739 EBSRedWarningSignal 3000;
BA_REL_ "GenSigTimeoutTime" BU_SG_REL_ VCM SG_ 2565865739 EBSRedWarningSignal 600;
BA_REL_ "GenSigFirstTimeoutTime" BU_SG_REL_ VCM SG_ 2565865739 ABSEBSAmberWarningSignal 3000;
BA_REL_ "GenSigTimeoutTime" BU_SG_REL_ VCM SG_ 2565865739 ABSEBSAmberWarningSignal 600;
BA_REL_ "GenSigFirstTimeoutTime" BU_SG_REL_ TCM SG_ 2565865739 AntiLockBrakingActive 3000;
BA_REL_ "GenSigTimeoutTime" BU_SG_REL_ TCM SG_ 2565865739 AntiLockBrakingActive 600;
BA_REL_ "GenSigFirstTimeoutTime" BU_SG_REL_ ECM SG_ 2565865739 AntiLockBrakingActive 3000;
BA_REL_ "GenSigTimeoutTime" BU_SG_REL_ ECM SG_ 2565865739 AntiLockBrakingActive 600;
BA_REL_ "GenSigFirstTimeoutTime" BU_SG_REL_ ECM SG_ 2565865739 ASRHillHolderSwitch 3000;
BA_REL_ "GenSigTimeoutTime" BU_SG_REL_ ECM SG_ 2565865739 ASRHillHolderSwitch 600;
BA_REL_ "GenSigFirstTimeoutTime" BU_SG_REL_ VCM SG_ 2565865739 ASRHillHolderSwitch 3000;
BA_REL_ "GenSigTimeoutTime" BU_SG_REL_ VCM SG_ 2565865739 ASRHillHolderSwitch 600;
BA_REL_ "GenSigFirstTimeoutTime" BU_SG_REL_ VCM SG_ 2566907915 DiagFaultStat_Brake_FailTA 24000;
BA_REL_ "GenSigTimeoutTime" BU_SG_REL_ VCM SG_ 2566907915 DiagFaultStat_Brake_FailTA 6000;
BA_REL_ "GenSigFirstTimeoutTime" BU_SG_REL_ VCM SG_ 2566907915 DiagFaultStat_Brake_DtcIdB 24000;
BA_REL_ "GenSigTimeoutTime" BU_SG_REL_ VCM SG_ 2566907915 DiagFaultStat_Brake_DtcIdB 6000;
BA_REL_ "GenSigFirstTimeoutTime" BU_SG_REL_ VCM SG_ 2566907915 DiagFaultStat_Brake_DtcIdA 24000;
BA_REL_ "GenSigTimeoutTime" BU_SG_REL_ VCM SG_ 2566907915 DiagFaultStat_Brake_DtcIdA 6000;
BA_REL_ "GenSigFirstTimeoutTime" BU_SG_REL_ VCM SG_ 2566907915 DiagFaultStat_Brake_EcuAdr 24000;
BA_REL_ "GenSigTimeoutTime" BU_SG_REL_ VCM SG_ 2566907915 DiagFaultStat_Brake_EcuAdr 6000;
BA_REL_ "GenSigFirstTimeoutTime" BU_SG_REL_ VCM SG_ 2566907915 DiagFaultStat_Brake_FailTB 24000;
BA_REL_ "GenSigTimeoutTime" BU_SG_REL_ VCM SG_ 2566907915 DiagFaultStat_Brake_FailTB 6000;
BA_REL_ "GenSigFirstTimeoutTime" BU_SG_REL_ VCM SG_ 2566907965 DiagFaultStat_ACM_FailTB 24000;
BA_REL_ "GenSigTimeoutTime" BU_SG_REL_ VCM SG_ 2566907965 DiagFaultStat_ACM_FailTB 6000;
BA_REL_ "GenSigFirstTimeoutTime" BU_SG_REL_ VCM SG_ 2566907965 DiagFaultStat_ACM_FailTA 24000;
BA_REL_ "GenSigTimeoutTime" BU_SG_REL_ VCM SG_ 2566907965 DiagFaultStat_ACM_FailTA 6000;
BA_REL_ "GenSigFirstTimeoutTime" BU_SG_REL_ VCM SG_ 2566907965 DiagFaultStat_ACM_DtcIdB 24000;
BA_REL_ "GenSigTimeoutTime" BU_SG_REL_ VCM SG_ 2566907965 DiagFaultStat_ACM_DtcIdB 6000;
BA_REL_ "GenSigFirstTimeoutTime" BU_SG_REL_ VCM SG_ 2566907965 DiagFaultStat_ACM_DtcIdA 24000;
BA_REL_ "GenSigTimeoutTime" BU_SG_REL_ VCM SG_ 2566907965 DiagFaultStat_ACM_DtcIdA 6000;
BA_REL_ "GenSigFirstTimeoutTime" BU_SG_REL_ VCM SG_ 2566907965 DiagFaultStat_ACM_EcuAdr 24000;
BA_REL_ "GenSigTimeoutTime" BU_SG_REL_ VCM SG_ 2566907965 DiagFaultStat_ACM_EcuAdr 6000;
BA_REL_ "GenSigFirstTimeoutTime" BU_SG_REL_ TCM SG_ 2566749184 DPFC1_InhibDueServiceBrake 24000;
BA_REL_ "GenSigTimeoutTime" BU_SG_REL_ TCM SG_ 2566749184 DPFC1_InhibDueServiceBrake 6000;
BA_REL_ "GenSigFirstTimeoutTime" BU_SG_REL_ VCM SG_ 2566749184 DPFC1_InhibDueServiceBrake 24000;
BA_REL_ "GenSigTimeoutTime" BU_SG_REL_ VCM SG_ 2566749184 DPFC1_InhibDueServiceBrake 6000;
BA_REL_ "GenSigFirstTimeoutTime" BU_SG_REL_ TCM SG_ 2566749184 DPFC1_InhibVehSpdBelowAllwdSpd 24000;
BA_REL_ "GenSigTimeoutTime" BU_SG_REL_ TCM SG_ 2566749184 DPFC1_InhibVehSpdBelowAllwdSpd 6000;
BA_REL_ "GenSigFirstTimeoutTime" BU_SG_REL_ VCM SG_ 2566749184 DPFC1_InhibVehSpdBelowAllwdSpd 24000;
BA_REL_ "GenSigTimeoutTime" BU_SG_REL_ VCM SG_ 2566749184 DPFC1_InhibVehSpdBelowAllwdSpd 6000;
BA_REL_ "GenSigFirstTimeoutTime" BU_SG_REL_ VCM SG_ 2566749184 DPFC1_ActiveRegeneratStatus 24000;
BA_REL_ "GenSigTimeoutTime" BU_SG_REL_ VCM SG_ 2566749184 DPFC1_ActiveRegeneratStatus 6000;
BA_REL_ "GenSigFirstTimeoutTime" BU_SG_REL_ TCM SG_ 2566749184 DPFC1_ActiveRegeneratStatus 24000;
BA_REL_ "GenSigTimeoutTime" BU_SG_REL_ TCM SG_ 2566749184 DPFC1_ActiveRegeneratStatus 6000;
BA_REL_ "GenSigFirstTimeoutTime" BU_SG_REL_ VCM SG_ 2566749184 DPFC1_ExhaustSystHighTempLampCmd 24000;
BA_REL_ "GenSigTimeoutTime" BU_SG_REL_ VCM SG_ 2566749184 DPFC1_ExhaustSystHighTempLampCmd 6000;
BA_REL_ "GenSigFirstTimeoutTime" BU_SG_REL_ TCM SG_ 2566749184 DPFC1_ExhaustSystHighTempLampCmd 24000;
BA_REL_ "GenSigTimeoutTime" BU_SG_REL_ TCM SG_ 2566749184 DPFC1_ExhaustSystHighTempLampCmd 6000;
BA_REL_ "GenSigFirstTimeoutTime" BU_SG_REL_ TCM SG_ 2566749184 DPFC1_InhibParkBrakeNotSet 24000;
BA_REL_ "GenSigTimeoutTime" BU_SG_REL_ TCM SG_ 2566749184 DPFC1_InhibParkBrakeNotSet 6000;
BA_REL_ "GenSigFirstTimeoutTime" BU_SG_REL_ VCM SG_ 2566749184 DPFC1_InhibParkBrakeNotSet 24000;
BA_REL_ "GenSigTimeoutTime" BU_SG_REL_ VCM SG_ 2566749184 DPFC1_InhibParkBrakeNotSet 6000;
BA_REL_ "GenSigFirstTimeoutTime" BU_SG_REL_ VCM SG_ 2566749184 DPFC1_InhibEnginNotWarmUp 24000;
BA_REL_ "GenSigTimeoutTime" BU_SG_REL_ VCM SG_ 2566749184 DPFC1_InhibEnginNotWarmUp 6000;
BA_REL_ "GenSigFirstTimeoutTime" BU_SG_REL_ TCM SG_ 2566749184 DPFC1_InhibEnginNotWarmUp 24000;
BA_REL_ "GenSigTimeoutTime" BU_SG_REL_ TCM SG_ 2566749184 DPFC1_InhibEnginNotWarmUp 6000;
BA_REL_ "GenSigFirstTimeoutTime" BU_SG_REL_ VCM SG_ 2566749184 DPFC1_InhibitStatus 24000;
BA_REL_ "GenSigTimeoutTime" BU_SG_REL_ VCM SG_ 2566749184 DPFC1_InhibitStatus 6000;
BA_REL_ "GenSigFirstTimeoutTime" BU_SG_REL_ TCM SG_ 2566749184 DPFC1_InhibitStatus 24000;
BA_REL_ "GenSigTimeoutTime" BU_SG_REL_ TCM SG_ 2566749184 DPFC1_InhibitStatus 6000;
BA_REL_ "GenSigFirstTimeoutTime" BU_SG_REL_ TCM SG_ 2566749184 DPFC1_ForcedStatus 24000;
BA_REL_ "GenSigTimeoutTime" BU_SG_REL_ TCM SG_ 2566749184 DPFC1_ForcedStatus 6000;
BA_REL_ "GenSigFirstTimeoutTime" BU_SG_REL_ VCM SG_ 2566749184 DPFC1_ForcedStatus 24000;
BA_REL_ "GenSigTimeoutTime" BU_SG_REL_ VCM SG_ 2566749184 DPFC1_ForcedStatus 6000;
BA_REL_ "GenSigFirstTimeoutTime" BU_SG_REL_ TCM SG_ 2566749184 DPFC1_PassiveRegenStatus 24000;
BA_REL_ "GenSigTimeoutTime" BU_SG_REL_ TCM SG_ 2566749184 DPFC1_PassiveRegenStatus 6000;
BA_REL_ "GenSigFirstTimeoutTime" BU_SG_REL_ VCM SG_ 2566749184 DPFC1_PassiveRegenStatus 24000;
BA_REL_ "GenSigTimeoutTime" BU_SG_REL_ VCM SG_ 2566749184 DPFC1_PassiveRegenStatus 6000;
BA_REL_ "GenSigFirstTimeoutTime" BU_SG_REL_ TCM SG_ 2566749184 DPFC1_InhibTempSystemLock 24000;
BA_REL_ "GenSigTimeoutTime" BU_SG_REL_ TCM SG_ 2566749184 DPFC1_InhibTempSystemLock 6000;
BA_REL_ "GenSigFirstTimeoutTime" BU_SG_REL_ VCM SG_ 2566749184 DPFC1_InhibTempSystemLock 24000;
BA_REL_ "GenSigTimeoutTime" BU_SG_REL_ VCM SG_ 2566749184 DPFC1_InhibTempSystemLock 6000;
BA_REL_ "GenSigFirstTimeoutTime" BU_SG_REL_ VCM SG_ 2566749184 DPFC1_InhibDueInhibSwitch 24000;
BA_REL_ "GenSigTimeoutTime" BU_SG_REL_ VCM SG_ 2566749184 DPFC1_InhibDueInhibSwitch 6000;
BA_REL_ "GenSigFirstTimeoutTime" BU_SG_REL_ TCM SG_ 2566749184 DPFC1_InhibDueInhibSwitch 24000;
BA_REL_ "GenSigTimeoutTime" BU_SG_REL_ TCM SG_ 2566749184 DPFC1_InhibDueInhibSwitch 6000;
BA_REL_ "GenSigFirstTimeoutTime" BU_SG_REL_ TCM SG_ 2566749184 DPFC1_InhibPTOActive 24000;
BA_REL_ "GenSigTimeoutTime" BU_SG_REL_ TCM SG_ 2566749184 DPFC1_InhibPTOActive 6000;
BA_REL_ "GenSigFirstTimeoutTime" BU_SG_REL_ VCM SG_ 2566749184 DPFC1_InhibPTOActive 24000;
BA_REL_ "GenSigTimeoutTime" BU_SG_REL_ VCM SG_ 2566749184 DPFC1_InhibPTOActive 6000;
BA_REL_ "GenSigFirstTimeoutTime" BU_SG_REL_ VCM SG_ 2566749184 DPFC1_AutoARInitConfig 24000;
BA_REL_ "GenSigTimeoutTime" BU_SG_REL_ VCM SG_ 2566749184 DPFC1_AutoARInitConfig 6000;
BA_REL_ "GenSigFirstTimeoutTime" BU_SG_REL_ TCM SG_ 2566749184 DPFC1_AutoARInitConfig 24000;
BA_REL_ "GenSigTimeoutTime" BU_SG_REL_ TCM SG_ 2566749184 DPFC1_AutoARInitConfig 6000;
BA_REL_ "GenSigFirstTimeoutTime" BU_SG_REL_ VCM SG_ 2566749184 DPFC1_InhibDueLowExhGasTemp 24000;
BA_REL_ "GenSigTimeoutTime" BU_SG_REL_ VCM SG_ 2566749184 DPFC1_InhibDueLowExhGasTemp 6000;
BA_REL_ "GenSigFirstTimeoutTime" BU_SG_REL_ TCM SG_ 2566749184 DPFC1_InhibDueLowExhGasTemp 24000;
BA_REL_ "GenSigTimeoutTime" BU_SG_REL_ TCM SG_ 2566749184 DPFC1_InhibDueLowExhGasTemp 6000;
BA_REL_ "GenSigFirstTimeoutTime" BU_SG_REL_ VCM SG_ 2566749184 DPFC1_InhibSystemFaultAct 24000;
BA_REL_ "GenSigTimeoutTime" BU_SG_REL_ VCM SG_ 2566749184 DPFC1_InhibSystemFaultAct 6000;
BA_REL_ "GenSigFirstTimeoutTime" BU_SG_REL_ TCM SG_ 2566749184 DPFC1_InhibSystemFaultAct 24000;
BA_REL_ "GenSigTimeoutTime" BU_SG_REL_ TCM SG_ 2566749184 DPFC1_InhibSystemFaultAct 6000;
BA_REL_ "GenSigFirstTimeoutTime" BU_SG_REL_ TCM SG_ 2566749184 DPFC1_InhibDueSystemTimeout 24000;
BA_REL_ "GenSigTimeoutTime" BU_SG_REL_ TCM SG_ 2566749184 DPFC1_InhibDueSystemTimeout 6000;
BA_REL_ "GenSigFirstTimeoutTime" BU_SG_REL_ VCM SG_ 2566749184 DPFC1_InhibDueSystemTimeout 24000;
BA_REL_ "GenSigTimeoutTime" BU_SG_REL_ VCM SG_ 2566749184 DPFC1_InhibDueSystemTimeout 6000;
BA_REL_ "GenSigFirstTimeoutTime" BU_SG_REL_ TCM SG_ 2566749184 DPFC1_InhibPermSystemLock 24000;
BA_REL_ "GenSigTimeoutTime" BU_SG_REL_ TCM SG_ 2566749184 DPFC1_InhibPermSystemLock 6000;
BA_REL_ "GenSigFirstTimeoutTime" BU_SG_REL_ VCM SG_ 2566749184 DPFC1_InhibPermSystemLock 24000;
BA_REL_ "GenSigTimeoutTime" BU_SG_REL_ VCM SG_ 2566749184 DPFC1_InhibPermSystemLock 6000;
BA_REL_ "GenSigFirstTimeoutTime" BU_SG_REL_ VCM SG_ 2566749184 DPFC1_LampCommand 24000;
BA_REL_ "GenSigTimeoutTime" BU_SG_REL_ VCM SG_ 2566749184 DPFC1_LampCommand 6000;
BA_REL_ "GenSigFirstTimeoutTime" BU_SG_REL_ TCM SG_ 2566749184 DPFC1_LampCommand 24000;
BA_REL_ "GenSigTimeoutTime" BU_SG_REL_ TCM SG_ 2566749184 DPFC1_LampCommand 6000;
BA_REL_ "GenSigFirstTimeoutTime" BU_SG_REL_ VCM SG_ 2566749184 DPFC1_InhibVehSpdAboveAllwdSpd 24000;
BA_REL_ "GenSigTimeoutTime" BU_SG_REL_ VCM SG_ 2566749184 DPFC1_InhibVehSpdAboveAllwdSpd 6000;
BA_REL_ "GenSigFirstTimeoutTime" BU_SG_REL_ TCM SG_ 2566749184 DPFC1_InhibVehSpdAboveAllwdSpd 24000;
BA_REL_ "GenSigTimeoutTime" BU_SG_REL_ TCM SG_ 2566749184 DPFC1_InhibVehSpdAboveAllwdSpd 6000;
BA_REL_ "GenSigFirstTimeoutTime" BU_SG_REL_ VCM SG_ 2566749184 DPFC1_InhibClutchDisengage 24000;
BA_REL_ "GenSigTimeoutTime" BU_SG_REL_ VCM SG_ 2566749184 DPFC1_InhibClutchDisengage 6000;
BA_REL_ "GenSigFirstTimeoutTime" BU_SG_REL_ TCM SG_ 2566749184 DPFC1_InhibClutchDisengage 24000;
BA_REL_ "GenSigTimeoutTime" BU_SG_REL_ TCM SG_ 2566749184 DPFC1_InhibClutchDisengage 6000;
BA_REL_ "GenSigFirstTimeoutTime" BU_SG_REL_ TCM SG_ 2566749184 DPFC1_InhibAccPedalOffIdle 24000;
BA_REL_ "GenSigTimeoutTime" BU_SG_REL_ TCM SG_ 2566749184 DPFC1_InhibAccPedalOffIdle 6000;
BA_REL_ "GenSigFirstTimeoutTime" BU_SG_REL_ VCM SG_ 2566749184 DPFC1_InhibAccPedalOffIdle 24000;
BA_REL_ "GenSigTimeoutTime" BU_SG_REL_ VCM SG_ 2566749184 DPFC1_InhibAccPedalOffIdle 6000;
BA_REL_ "GenSigFirstTimeoutTime" BU_SG_REL_ VCM SG_ 2566749184 DPFC1_InhibOutOfNeutral 24000;
BA_REL_ "GenSigTimeoutTime" BU_SG_REL_ VCM SG_ 2566749184 DPFC1_InhibOutOfNeutral 6000;
BA_REL_ "GenSigFirstTimeoutTime" BU_SG_REL_ TCM SG_ 2566749184 DPFC1_InhibOutOfNeutral 24000;
BA_REL_ "GenSigTimeoutTime" BU_SG_REL_ TCM SG_ 2566749184 DPFC1_InhibOutOfNeutral 6000;
BA_REL_ "GenSigFirstTimeoutTime" BU_SG_REL_ TCM SG_ 2566749184 DPFC1_DPFStatus 24000;
BA_REL_ "GenSigTimeoutTime" BU_SG_REL_ TCM SG_ 2566749184 DPFC1_DPFStatus 6000;
BA_REL_ "GenSigFirstTimeoutTime" BU_SG_REL_ VCM SG_ 2566749184 DPFC1_DPFStatus 24000;
BA_REL_ "GenSigTimeoutTime" BU_SG_REL_ VCM SG_ 2566749184 DPFC1_DPFStatus 6000;
BA_REL_ "GenSigFirstTimeoutTime" BU_SG_REL_ VCM SG_ 2566834691 DiagnosticsFaultStat_DM1_TECU 24000;
BA_REL_ "GenSigTimeoutTime" BU_SG_REL_ VCM SG_ 2566834691 DiagnosticsFaultStat_DM1_TECU 6000;
BA_REL_ "GenSigFirstTimeoutTime" BU_SG_REL_ VCM SG_ 2566834688 DiagnosticsFaultStat_DM1_EMS 24000;
BA_REL_ "GenSigTimeoutTime" BU_SG_REL_ VCM SG_ 2566834688 DiagnosticsFaultStat_DM1_EMS 6000;
BA_REL_ "GenSigFirstTimeoutTime" BU_SG_REL_ VCM SG_ 2566834749 DiagnosticsFaultStat_DM1_ACM 24000;
BA_REL_ "GenSigTimeoutTime" BU_SG_REL_ VCM SG_ 2566834749 DiagnosticsFaultStat_DM1_ACM 6000;
BA_REL_ "GenSigFirstTimeoutTime" BU_SG_REL_ VCM SG_ 2566811659 PoweredVehicleWeight 48000;
BA_REL_ "GenSigTimeoutTime" BU_SG_REL_ VCM SG_ 2566811659 PoweredVehicleWeight 12000;
BA_REL_ "GenSigFirstTimeoutTime" BU_SG_REL_ VCM SG_ 2566811659 GrossCombinationVehicleWeight 48000;
BA_REL_ "GenSigTimeoutTime" BU_SG_REL_ VCM SG_ 2566811659 GrossCombinationVehicleWeight 12000;
BA_REL_ "GenSigFirstTimeoutTime" BU_SG_REL_ TCM SG_ 2566811659 GrossCombinationVehicleWeight 65000;
BA_REL_ "GenSigTimeoutTime" BU_SG_REL_ TCM SG_ 2566811659 GrossCombinationVehicleWeight 12000;
BA_REL_ "GenSigFirstTimeoutTime" BU_SG_REL_ ECM SG_ 2566811659 GrossCombinationVehicleWeight 48000;
BA_REL_ "GenSigTimeoutTime" BU_SG_REL_ ECM SG_ 2566811659 GrossCombinationVehicleWeight 12000;
BA_REL_ "GenSigFirstTimeoutTime" BU_SG_REL_ EBS SG_ 2499757105 HSADriverRequest 3000;
BA_REL_ "GenSigTimeoutTime" BU_SG_REL_ EBS SG_ 2499757105 HSADriverRequest 300;
BA_REL_ "GenSigFirstTimeoutTime" BU_SG_REL_ EBS SG_ 2499757105 ESCDriverReq 3000;
BA_REL_ "GenSigTimeoutTime" BU_SG_REL_ EBS SG_ 2499757105 ESCDriverReq 300;
BA_REL_ "GenSigFirstTimeoutTime" BU_SG_REL_ EBS SG_ 2499757105 RrRrItrWhlDiffLckActvnDrvrReq 3000;
BA_REL_ "GenSigTimeoutTime" BU_SG_REL_ EBS SG_ 2499757105 RrRrItrWhlDiffLckActvnDrvrReq 500;
BA_REL_ "GenSigFirstTimeoutTime" BU_SG_REL_ EBS SG_ 2499757105 AutRrAxleDiffLockActvnDrvrReq 3000;
BA_REL_ "GenSigTimeoutTime" BU_SG_REL_ EBS SG_ 2499757105 AutRrAxleDiffLockActvnDrvrReq 300;
BA_REL_ "GenSigFirstTimeoutTime" BU_SG_REL_ EBS SG_ 2499757105 ABSModeRequest 3000;
BA_REL_ "GenSigTimeoutTime" BU_SG_REL_ EBS SG_ 2499757105 ABSModeRequest 300;
BA_REL_ "GenSigFirstTimeoutTime" BU_SG_REL_ EBS SG_ 2499757105 FrRrItrWhlDiffLckActvnDrvrReq 3000;
BA_REL_ "GenSigTimeoutTime" BU_SG_REL_ EBS SG_ 2499757105 FrRrItrWhlDiffLckActvnDrvrReq 500;
BA_REL_ "GenSigFirstTimeoutTime" BU_SG_REL_ EBS SG_ 2499757105 RearAxleSteeringFunctionDsbl 3000;
BA_REL_ "GenSigTimeoutTime" BU_SG_REL_ EBS SG_ 2499757105 RearAxleSteeringFunctionDsbl 300;
BA_REL_ "GenSigFirstTimeoutTime" BU_SG_REL_ EBS SG_ 2499757105 RollerBenchModeRequest 3000;
BA_REL_ "GenSigTimeoutTime" BU_SG_REL_ EBS SG_ 2499757105 RollerBenchModeRequest 300;
BA_REL_ "GenSigFirstTimeoutTime" BU_SG_REL_ EBS SG_ 2499757105 RearAxleDiffLockActvnDrvrReq 3000;
BA_REL_ "GenSigTimeoutTime" BU_SG_REL_ EBS SG_ 2499757105 RearAxleDiffLockActvnDrvrReq 500;
BA_REL_ "GenSigFirstTimeoutTime" BU_SG_REL_ ECM SG_ 2499757105 SplitBoxDifflockActvnDrvrRqst 3000;
BA_REL_ "GenSigTimeoutTime" BU_SG_REL_ ECM SG_ 2499757105 SplitBoxDifflockActvnDrvrRqst 300;
BA_REL_ "GenSigFirstTimeoutTime" BU_SG_REL_ EBS SG_ 2499757105 SplitBoxDifflockActvnDrvrRqst 3000;
BA_REL_ "GenSigTimeoutTime" BU_SG_REL_ EBS SG_ 2499757105 SplitBoxDifflockActvnDrvrRqst 300;
BA_REL_ "GenSigFirstTimeoutTime" BU_SG_REL_ TCM SG_ 2499757105 SplitBoxDifflockActvnDrvrRqst 3000;
BA_REL_ "GenSigTimeoutTime" BU_SG_REL_ TCM SG_ 2499757105 SplitBoxDifflockActvnDrvrRqst 300;
BA_REL_ "GenSigFirstTimeoutTime" BU_SG_REL_ EBS SG_ 2499757105 TractionControlDriverRqst 3000;
BA_REL_ "GenSigTimeoutTime" BU_SG_REL_ EBS SG_ 2499757105 TractionControlDriverRqst 300;
BA_REL_ "GenSigFirstTimeoutTime" BU_SG_REL_ EBS SG_ 2499757105 RrInterAxlDiffLockActvnDrvrReq 3000;
BA_REL_ "GenSigTimeoutTime" BU_SG_REL_ EBS SG_ 2499757105 RrInterAxlDiffLockActvnDrvrReq 500;
BA_REL_ "GenSigFirstTimeoutTime" BU_SG_REL_ EBS SG_ 2499757105 ABSInhibitionRequest 3000;
BA_REL_ "GenSigTimeoutTime" BU_SG_REL_ EBS SG_ 2499757105 ABSInhibitionRequest 300;
BA_REL_ "GenSigFirstTimeoutTime" BU_SG_REL_ TCM SG_ 2566844689 CCActive 3000;
BA_REL_ "GenSigTimeoutTime" BU_SG_REL_ TCM SG_ 2566844689 CCActive 600;
BA_REL_ "GenSigFirstTimeoutTime" BU_SG_REL_ EBS SG_ 2566844689 ClutchSwitch 3000;
BA_REL_ "GenSigTimeoutTime" BU_SG_REL_ EBS SG_ 2566844689 ClutchSwitch 600;
BA_REL_ "GenSigFirstTimeoutTime" BU_SG_REL_ EBS SG_ 2566844689 WheelBasedVehicleSpeed 3000;
BA_REL_ "GenSigTimeoutTime" BU_SG_REL_ EBS SG_ 2566844689 WheelBasedVehicleSpeed 600;
BA_REL_ "GenSigFirstTimeoutTime" BU_SG_REL_ ECM SG_ 2566844689 WheelBasedVehicleSpeed 3000;
BA_REL_ "GenSigTimeoutTime" BU_SG_REL_ ECM SG_ 2566844689 WheelBasedVehicleSpeed 600;
BA_REL_ "GenSigFirstTimeoutTime" BU_SG_REL_ TCM SG_ 2566844689 WheelBasedVehicleSpeed 3000;
BA_REL_ "GenSigTimeoutTime" BU_SG_REL_ TCM SG_ 2566844689 WheelBasedVehicleSpeed 600;
BA_REL_ "GenSigFirstTimeoutTime" BU_SG_REL_ ACM SG_ 2566844689 WheelBasedVehicleSpeed 3000;
BA_REL_ "GenSigTimeoutTime" BU_SG_REL_ ACM SG_ 2566844689 WheelBasedVehicleSpeed 600;
BA_REL_ "GenSigFirstTimeoutTime" BU_SG_REL_ ECM SG_ 2566844689 BrakeSwitch 3000;
BA_REL_ "GenSigTimeoutTime" BU_SG_REL_ ECM SG_ 2566844689 BrakeSwitch 600;
BA_REL_ "GenSigFirstTimeoutTime" BU_SG_REL_ TCM SG_ 2566844689 BrakeSwitch 3000;
BA_REL_ "GenSigTimeoutTime" BU_SG_REL_ TCM SG_ 2566844689 BrakeSwitch 600;
BA_REL_ "GenSigFirstTimeoutTime" BU_SG_REL_ VCM SG_ 2566748928 DPFSootLevel 24000;
BA_REL_ "GenSigTimeoutTime" BU_SG_REL_ VCM SG_ 2566748928 DPFSootLevel 6000;
BA_REL_ "GenSigFirstTimeoutTime" BU_SG_REL_ VCM SG_ 2565869312 Aftertreat1NOxConcOutlet 12000;
BA_REL_ "GenSigTimeoutTime" BU_SG_REL_ VCM SG_ 2565869312 Aftertreat1NOxConcOutlet 3000;
BA_REL_ "GenSigFirstTimeoutTime" BU_SG_REL_ VCM SG_ 2566763008 DPFPressureDiff 12000;
BA_REL_ "GenSigTimeoutTime" BU_SG_REL_ VCM SG_ 2566763008 DPFPressureDiff 3000;
BA_REL_ "GenSigFirstTimeoutTime" BU_SG_REL_ VCM SG_ 2566763520 Aftertreatment1ExhaustTemp1 12000;
BA_REL_ "GenSigTimeoutTime" BU_SG_REL_ VCM SG_ 2566763520 Aftertreatment1ExhaustTemp1 3000;
BA_REL_ "GenSigFirstTimeoutTime" BU_SG_REL_ VCM SG_ 2565869056 EngineExhaust1NOx1 12000;
BA_REL_ "GenSigTimeoutTime" BU_SG_REL_ VCM SG_ 2565869056 EngineExhaust1NOx1 3000;
BA_REL_ "GenSigFirstTimeoutTime" BU_SG_REL_ ACM SG_ 2566845713 AmbientAirTemperature 24000;
BA_REL_ "GenSigTimeoutTime" BU_SG_REL_ ACM SG_ 2566845713 AmbientAirTemperature 6000;
BA_REL_ "GenSigFirstTimeoutTime" BU_SG_REL_ ECM SG_ 2566845713 AmbientAirTemperature 24000;
BA_REL_ "GenSigTimeoutTime" BU_SG_REL_ ECM SG_ 2566845713 AmbientAirTemperature 6000;
BA_REL_ "GenSigFirstTimeoutTime" BU_SG_REL_ TCM SG_ 2566845713 AmbientAirTemperature 24000;
BA_REL_ "GenSigTimeoutTime" BU_SG_REL_ TCM SG_ 2566845713 AmbientAirTemperature 6000;
BA_REL_ "GenSigFirstTimeoutTime" BU_SG_REL_ EBS SG_ 2566845713 AmbientAirTemperature 24000;
BA_REL_ "GenSigTimeoutTime" BU_SG_REL_ EBS SG_ 2566845713 AmbientAirTemperature 6000;
BA_REL_ "GenSigFirstTimeoutTime" BU_SG_REL_ ECM SG_ 2566827537 ServiceBrakeAirPrsCircuit1 24000;
BA_REL_ "GenSigTimeoutTime" BU_SG_REL_ ECM SG_ 2566827537 ServiceBrakeAirPrsCircuit1 6000;
BA_REL_ "GenSigFirstTimeoutTime" BU_SG_REL_ ACM SG_ 2566827537 ServiceBrakeAirPrsCircuit1 24000;
BA_REL_ "GenSigTimeoutTime" BU_SG_REL_ ACM SG_ 2566827537 ServiceBrakeAirPrsCircuit1 6000;
BA_REL_ "GenSigFirstTimeoutTime" BU_SG_REL_ TCM SG_ 2566827537 ServiceBrakeAirPrsCircuit1 24000;
BA_REL_ "GenSigTimeoutTime" BU_SG_REL_ TCM SG_ 2566827537 ServiceBrakeAirPrsCircuit1 6000;
BA_REL_ "GenSigFirstTimeoutTime" BU_SG_REL_ ECM SG_ 2566827537 ServiceBrakeAirPrsCircuit2 24000;
BA_REL_ "GenSigTimeoutTime" BU_SG_REL_ ECM SG_ 2566827537 ServiceBrakeAirPrsCircuit2 6000;
BA_REL_ "GenSigFirstTimeoutTime" BU_SG_REL_ TCM SG_ 2566827537 ServiceBrakeAirPrsCircuit2 24000;
BA_REL_ "GenSigTimeoutTime" BU_SG_REL_ TCM SG_ 2566827537 ServiceBrakeAirPrsCircuit2 6000;
BA_REL_ "GenSigFirstTimeoutTime" BU_SG_REL_ ACM SG_ 2566827537 ServiceBrakeAirPrsCircuit2 24000;
BA_REL_ "GenSigTimeoutTime" BU_SG_REL_ ACM SG_ 2566827537 ServiceBrakeAirPrsCircuit2 6000;
BA_REL_ "GenSigFirstTimeoutTime" BU_SG_REL_ VCM SG_ 2566892605 LNGRestrictionStatus_V1Closed 24000;
BA_REL_ "GenSigTimeoutTime" BU_SG_REL_ VCM SG_ 2566892605 LNGRestrictionStatus_V1Closed 6000;
BA_REL_ "GenSigFirstTimeoutTime" BU_SG_REL_ VCM SG_ 2566892605 LNGRestrictionStatus_Spare4 24000;
BA_REL_ "GenSigTimeoutTime" BU_SG_REL_ VCM SG_ 2566892605 LNGRestrictionStatus_Spare4 6000;
BA_REL_ "GenSigFirstTimeoutTime" BU_SG_REL_ VCM SG_ 2566892605 LNGRestrictionStatus_Spare2 24000;
BA_REL_ "GenSigTimeoutTime" BU_SG_REL_ VCM SG_ 2566892605 LNGRestrictionStatus_Spare2 6000;
BA_REL_ "GenSigFirstTimeoutTime" BU_SG_REL_ VCM SG_ 2566892605 ACM_Available_Log 24000;
BA_REL_ "GenSigTimeoutTime" BU_SG_REL_ VCM SG_ 2566892605 ACM_Available_Log 6000;
BA_REL_ "GenSigFirstTimeoutTime" BU_SG_REL_ VCM SG_ 2566892605 LNGRestrictionStatus_SInfo 24000;
BA_REL_ "GenSigTimeoutTime" BU_SG_REL_ VCM SG_ 2566892605 LNGRestrictionStatus_SInfo 6000;
BA_REL_ "GenSigFirstTimeoutTime" BU_SG_REL_ VCM SG_ 2566892605 LNGRestrictionStatus_Spare3 24000;
BA_REL_ "GenSigTimeoutTime" BU_SG_REL_ VCM SG_ 2566892605 LNGRestrictionStatus_Spare3 6000;
BA_REL_ "GenSigFirstTimeoutTime" BU_SG_REL_ VCM SG_ 2566892605 LNGRestrictionStatus_Spare1 24000;
BA_REL_ "GenSigTimeoutTime" BU_SG_REL_ VCM SG_ 2566892605 LNGRestrictionStatus_Spare1 6000;
BA_REL_ "GenSigFirstTimeoutTime" BU_SG_REL_ VCM SG_ 2566892605 LNGTimeToVent 24000;
BA_REL_ "GenSigTimeoutTime" BU_SG_REL_ VCM SG_ 2566892605 LNGTimeToVent 6000;
BA_REL_ "GenSigFirstTimeoutTime" BU_SG_REL_ VCM SG_ 2566892605 LNGRestrictionStatus_V2Closed 24000;
BA_REL_ "GenSigTimeoutTime" BU_SG_REL_ VCM SG_ 2566892605 LNGRestrictionStatus_V2Closed 6000;
BA_REL_ "GenSigFirstTimeoutTime" BU_SG_REL_ VCM SG_ 2566892093 LngSystemReadinessStat 24000;
BA_REL_ "GenSigTimeoutTime" BU_SG_REL_ VCM SG_ 2566892093 LngSystemReadinessStat 6000;
BA_REL_ "GenSigFirstTimeoutTime" BU_SG_REL_ VCM SG_ 2566892093 MIStatusACM 24000;
BA_REL_ "GenSigTimeoutTime" BU_SG_REL_ VCM SG_ 2566892093 MIStatusACM 6000;
BA_REL_ "GenSigFirstTimeoutTime" BU_SG_REL_ ECM SG_ 2566892093 MIStatusACM 24000;
BA_REL_ "GenSigTimeoutTime" BU_SG_REL_ ECM SG_ 2566892093 MIStatusACM 6000;
BA_REL_ "GenSigFirstTimeoutTime" BU_SG_REL_ VCM SG_ 2566892093 LngTank1WarnStat 24000;
BA_REL_ "GenSigTimeoutTime" BU_SG_REL_ VCM SG_ 2566892093 LngTank1WarnStat 6000;
BA_REL_ "GenSigFirstTimeoutTime" BU_SG_REL_ VCM SG_ 2566892093 LngTank2WarnStat 24000;
BA_REL_ "GenSigTimeoutTime" BU_SG_REL_ VCM SG_ 2566892093 LngTank2WarnStat 6000;
BA_REL_ "GenSigFirstTimeoutTime" BU_SG_REL_ VCM SG_ 2566892093 LNGLevel 24000;
BA_REL_ "GenSigTimeoutTime" BU_SG_REL_ VCM SG_ 2566892093 LNGLevel 6000;
BA_REL_ "GenSigFirstTimeoutTime" BU_SG_REL_ VCM SG_ 2566892093 LngTank1RemainingGasVolume 24000;
BA_REL_ "GenSigTimeoutTime" BU_SG_REL_ VCM SG_ 2566892093 LngTank1RemainingGasVolume 6000;
BA_REL_ "GenSigFirstTimeoutTime" BU_SG_REL_ VCM SG_ 2566892093 AdBlueTankTemperature 24000;
BA_REL_ "GenSigTimeoutTime" BU_SG_REL_ VCM SG_ 2566892093 AdBlueTankTemperature 6000;
BA_REL_ "GenSigFirstTimeoutTime" BU_SG_REL_ ECM SG_ 2566892093 CatalystTankLevelLow 24000;
BA_REL_ "GenSigTimeoutTime" BU_SG_REL_ ECM SG_ 2566892093 CatalystTankLevelLow 6000;
BA_REL_ "GenSigFirstTimeoutTime" BU_SG_REL_ VCM SG_ 2566892093 CatalystTankLevelLow 24000;
BA_REL_ "GenSigTimeoutTime" BU_SG_REL_ VCM SG_ 2566892093 CatalystTankLevelLow 6000;
BA_REL_ "GenSigFirstTimeoutTime" BU_SG_REL_ VCM SG_ 2566892093 CatalystTankLevel 24000;
BA_REL_ "GenSigTimeoutTime" BU_SG_REL_ VCM SG_ 2566892093 CatalystTankLevel 6000;
BA_REL_ "GenSigFirstTimeoutTime" BU_SG_REL_ ECM SG_ 2566892093 CatalystTankLevel 24000;
BA_REL_ "GenSigTimeoutTime" BU_SG_REL_ ECM SG_ 2566892093 CatalystTankLevel 6000;
BA_REL_ "GenSigFirstTimeoutTime" BU_SG_REL_ VCM SG_ 2566892093 LngTank2RemainingGasVolume 24000;
BA_REL_ "GenSigTimeoutTime" BU_SG_REL_ VCM SG_ 2566892093 LngTank2RemainingGasVolume 6000;
BA_REL_ "GenSigFirstTimeoutTime" BU_SG_REL_ VCM SG_ 2566892093 LngGspWarnStat 24000;
BA_REL_ "GenSigTimeoutTime" BU_SG_REL_ VCM SG_ 2566892093 LngGspWarnStat 6000;
BA_REL_ "GenSigFirstTimeoutTime" BU_SG_REL_ VCM SG_ 2566892093 MIDistinctWarningACM 24000;
BA_REL_ "GenSigTimeoutTime" BU_SG_REL_ VCM SG_ 2566892093 MIDistinctWarningACM 6000;
BA_REL_ "GenSigFirstTimeoutTime" BU_SG_REL_ ECM SG_ 2566892093 MIDistinctWarningACM 24000;
BA_REL_ "GenSigTimeoutTime" BU_SG_REL_ ECM SG_ 2566892093 MIDistinctWarningACM 6000;
BA_REL_ "GenSigFirstTimeoutTime" BU_SG_REL_ ECM SG_ 2566892093 MIDistinctWarningExtACM 24000;
BA_REL_ "GenSigTimeoutTime" BU_SG_REL_ ECM SG_ 2566892093 MIDistinctWarningExtACM 6000;
BA_REL_ "GenSigFirstTimeoutTime" BU_SG_REL_ VCM SG_ 2566892093 MIDistinctWarningExtACM 24000;
BA_REL_ "GenSigTimeoutTime" BU_SG_REL_ VCM SG_ 2566892093 MIDistinctWarningExtACM 6000;
BA_REL_ "GenSigFirstTimeoutTime" BU_SG_REL_ VCM SG_ 2566892093 MIStatusExtACM 24000;
BA_REL_ "GenSigTimeoutTime" BU_SG_REL_ VCM SG_ 2566892093 MIStatusExtACM 6000;
BA_REL_ "GenSigFirstTimeoutTime" BU_SG_REL_ ECM SG_ 2566892093 MIStatusExtACM 24000;
BA_REL_ "GenSigTimeoutTime" BU_SG_REL_ ECM SG_ 2566892093 MIStatusExtACM 6000;
BA_REL_ "GenSigFirstTimeoutTime" BU_SG_REL_ VCM SG_ 2499624448 SCROutletTemp 12000;
BA_REL_ "GenSigTimeoutTime" BU_SG_REL_ VCM SG_ 2499624448 SCROutletTemp 3000;
BA_REL_ "GenSigFirstTimeoutTime" BU_SG_REL_ VCM SG_ 2499624448 SCRInletTemp 12000;
BA_REL_ "GenSigTimeoutTime" BU_SG_REL_ VCM SG_ 2499624448 SCRInletTemp 3000;
VAL_ 2566877707 Trailer2BrkLining_Warning 3 "Warning_NotAvailable" 2 "Warning_Error" 1 "Warning_Warning" 0 "Warning_NoWarning" ;
VAL_ 2566877707 Trailer2RampLevel_LvlPos 3 "LvlPos_NotAvailable" 2 "LvlPos_Error" 1 "LvlPos_VehicleBodyHeightAtLevel2" 0 "LvlPos_VehicleBodyHeightAtLevel1" ;
VAL_ 2566877707 Trailer2RampLevel_LvlStatus 3 "LvlStatus_NotAvailable" 2 "LvlStatus_Error" 1 "LvlStatus_VehicelBodyAtRequestedLevel" 0 "LvlStatus_VehicelBodyNotAtRequestedLevel" ;
VAL_ 2566877707 Trailer2NormalLevel_LvlPos 3 "LvlPos_NotAvailable" 2 "LvlPos_Error" 1 "LvlPos_VehicleBodyHeightAtLevel2" 0 "LvlPos_VehicleBodyHeightAtLevel1" ;
VAL_ 2566877707 Trailer2NormalLevel_LvlStatus 3 "LvlStatus_NotAvailable" 2 "LvlStatus_Error" 1 "LvlStatus_VehicelBodyAtRequestedLevel" 0 "LvlStatus_VehicelBodyNotAtRequestedLevel" ;
VAL_ 2566877451 Trailer1NormalLevel_LvlPos 3 "LvlPos_NotAvailable" 2 "LvlPos_Error" 1 "LvlPos_VehicleBodyHeightAtLevel2" 0 "LvlPos_VehicleBodyHeightAtLevel1" ;
VAL_ 2566877451 Trailer1BrkLining_Warning 3 "Warning_NotAvailable" 2 "Warning_Error" 1 "Warning_Warning" 0 "Warning_NoWarning" ;
VAL_ 2566877451 Trailer1RampLevel_LvlPos 3 "LvlPos_NotAvailable" 2 "LvlPos_Error" 1 "LvlPos_VehicleBodyHeightAtLevel2" 0 "LvlPos_VehicleBodyHeightAtLevel1" ;
VAL_ 2566877451 Trailer1NormalLevel_LvlStatus 3 "LvlStatus_NotAvailable" 2 "LvlStatus_Error" 1 "LvlStatus_VehicelBodyAtRequestedLevel" 0 "LvlStatus_VehicelBodyNotAtRequestedLevel" ;
VAL_ 2566877451 Trailer1RampLevel_LvlStatus 3 "LvlStatus_NotAvailable" 2 "LvlStatus_Error" 1 "LvlStatus_VehicelBodyAtRequestedLevel" 0 "LvlStatus_VehicelBodyNotAtRequestedLevel" ;
VAL_ 2566903051 Trailer5GeometricData_Index 255 "TrailerGeometricDataIndex_NotAvailable" 254 "TrailerGeometricDataIndex_Error" 38 "TrailerGeometricDataIndex_TrailerHeightRear" 37 "TrailerGeometricDataIndex_ChassisHeight" 36 "TrailerGeometricDataIndex_TrailerHeightFront" 35 "TrailerGeometricDataIndex_LoadingHeightFront" 34 "TrailerGeometricDataIndex_LoadingHeightRear" 33 "TrailerGeometricDataIndex_CouplingHeight2" 32 "TrailerGeometricDataIndex_CouplingHeight1" 31 "TrailerGeometricDataIndex_TotalLengthOfTrailer" 30 "TrailerGeometricDataIndex_DistanceFirstToSecondCouplingPoint" 29 "TrailerGeometricDataIndex_WheelBaseAxle19ToAxle20" 28 "TrailerGeometricDataIndex_WheelBaseAxle18ToAxle19" 27 "TrailerGeometricDataIndex_WheelBaseAxle17ToAxle18" 26 "TrailerGeometricDataIndex_WheelBaseAxle16ToAxle17" 25 "TrailerGeometricDataIndex_WheelBaseAxle15ToAxle16" 24 "TrailerGeometricDataIndex_WheelBaseAxle14ToAxle15" 23 "TrailerGeometricDataIndex_WheelBaseAxle13ToAxle14" 22 "TrailerGeometricDataIndex_WheelBaseAxle12ToAxle13" 21 "TrailerGeometricDataIndex_WheelBaseAxle11ToAxle12" 20 "TrailerGeometricDataIndex_WheelBaseAxle10ToAxle11" 19 "TrailerGeometricDataIndex_WheelBaseAxle9ToAxle10" 18 "TrailerGeometricDataIndex_WheelBaseAxle8ToAxle9" 17 "TrailerGeometricDataIndex_WheelBaseAxle7ToAxle8" 16 "TrailerGeometricDataIndex_WheelBaseAxle6ToAxle7" 15 "TrailerGeometricDataIndex_WheelBaseAxle5ToAxle6" 14 "TrailerGeometricDataIndex_WheelBaseAxle4ToAxle5" 13 "TrailerGeometricDataIndex_WheelBaseAxle3ToAxle4" 12 "TrailerGeometricDataIndex_WheelBaseAxle2ToAxle3" 11 "TrailerGeometricDataIndex_WheelBaseAxle1ToAxle2" 10 "TrailerGeometricDataIndex_AxleNumberOfLiftAxle5" 9 "TrailerGeometricDataIndex_AxleNumberOfLiftAxle4" 8 "TrailerGeometricDataIndex_AxleNumberOfLiftAxle3" 7 "TrailerGeometricDataIndex_AxleNumberOfLiftAxle2" 6 "TrailerGeometricDataIndex_AxleNumberOfLiftAxle1" 5 "TrailerGeometricDataIndex_NumberOfLiftAxles" 4 "TrailerGeometricDataIndex_NumberOfFrontAxles" 3 "TrailerGeometricDataIndex_NumberOfAxles" 2 "TrailerGeometricDataIndex_TrackWidth" 1 "TrailerGeometricDataIndex_DistanceCouplingToAxle1" 0 "TrailerGeometricDataIndex_TypeOfTrailer" ;
VAL_ 2566903051 LiningWearWarning 3 "Warning_NotAvailable" 2 "Warning_Error" 1 "Warning_Warning" 0 "Warning_NoWarning" ;
VAL_ 2566903051 PadChangePredictionAxleNumber 7 "PadChangePredictionAxleNumber_Spare_01" 6 "PadChangePredictionAxleNumber_Spare" 5 "PadChangePredictionAxleNumber_AxleNo5" 4 "PadChangePredictionAxleNumber_AxleNo4" 3 "PadChangePredictionAxleNumber_AxleNo3" 2 "PadChangePredictionAxleNumber_AxleNo2" 1 "PadChangePredictionAxleNumber_AxleNo1" 0 "PadChangePredictionAxleNumber_NotApplicable" ;
VAL_ 2566902539 Trailer4GeometricData_Index 255 "TrailerGeometricDataIndex_NotAvailable" 254 "TrailerGeometricDataIndex_Error" 38 "TrailerGeometricDataIndex_TrailerHeightRear" 37 "TrailerGeometricDataIndex_ChassisHeight" 36 "TrailerGeometricDataIndex_TrailerHeightFront" 35 "TrailerGeometricDataIndex_LoadingHeightFront" 34 "TrailerGeometricDataIndex_LoadingHeightRear" 33 "TrailerGeometricDataIndex_CouplingHeight2" 32 "TrailerGeometricDataIndex_CouplingHeight1" 31 "TrailerGeometricDataIndex_TotalLengthOfTrailer" 30 "TrailerGeometricDataIndex_DistanceFirstToSecondCouplingPoint" 29 "TrailerGeometricDataIndex_WheelBaseAxle19ToAxle20" 28 "TrailerGeometricDataIndex_WheelBaseAxle18ToAxle19" 27 "TrailerGeometricDataIndex_WheelBaseAxle17ToAxle18" 26 "TrailerGeometricDataIndex_WheelBaseAxle16ToAxle17" 25 "TrailerGeometricDataIndex_WheelBaseAxle15ToAxle16" 24 "TrailerGeometricDataIndex_WheelBaseAxle14ToAxle15" 23 "TrailerGeometricDataIndex_WheelBaseAxle13ToAxle14" 22 "TrailerGeometricDataIndex_WheelBaseAxle12ToAxle13" 21 "TrailerGeometricDataIndex_WheelBaseAxle11ToAxle12" 20 "TrailerGeometricDataIndex_WheelBaseAxle10ToAxle11" 19 "TrailerGeometricDataIndex_WheelBaseAxle9ToAxle10" 18 "TrailerGeometricDataIndex_WheelBaseAxle8ToAxle9" 17 "TrailerGeometricDataIndex_WheelBaseAxle7ToAxle8" 16 "TrailerGeometricDataIndex_WheelBaseAxle6ToAxle7" 15 "TrailerGeometricDataIndex_WheelBaseAxle5ToAxle6" 14 "TrailerGeometricDataIndex_WheelBaseAxle4ToAxle5" 13 "TrailerGeometricDataIndex_WheelBaseAxle3ToAxle4" 12 "TrailerGeometricDataIndex_WheelBaseAxle2ToAxle3" 11 "TrailerGeometricDataIndex_WheelBaseAxle1ToAxle2" 10 "TrailerGeometricDataIndex_AxleNumberOfLiftAxle5" 9 "TrailerGeometricDataIndex_AxleNumberOfLiftAxle4" 8 "TrailerGeometricDataIndex_AxleNumberOfLiftAxle3" 7 "TrailerGeometricDataIndex_AxleNumberOfLiftAxle2" 6 "TrailerGeometricDataIndex_AxleNumberOfLiftAxle1" 5 "TrailerGeometricDataIndex_NumberOfLiftAxles" 4 "TrailerGeometricDataIndex_NumberOfFrontAxles" 3 "TrailerGeometricDataIndex_NumberOfAxles" 2 "TrailerGeometricDataIndex_TrackWidth" 1 "TrailerGeometricDataIndex_DistanceCouplingToAxle1" 0 "TrailerGeometricDataIndex_TypeOfTrailer" ;
VAL_ 2566902539 Trailer3GeometricData_Index 255 "TrailerGeometricDataIndex_NotAvailable" 254 "TrailerGeometricDataIndex_Error" 38 "TrailerGeometricDataIndex_TrailerHeightRear" 37 "TrailerGeometricDataIndex_ChassisHeight" 36 "TrailerGeometricDataIndex_TrailerHeightFront" 35 "TrailerGeometricDataIndex_LoadingHeightFront" 34 "TrailerGeometricDataIndex_LoadingHeightRear" 33 "TrailerGeometricDataIndex_CouplingHeight2" 32 "TrailerGeometricDataIndex_CouplingHeight1" 31 "TrailerGeometricDataIndex_TotalLengthOfTrailer" 30 "TrailerGeometricDataIndex_DistanceFirstToSecondCouplingPoint" 29 "TrailerGeometricDataIndex_WheelBaseAxle19ToAxle20" 28 "TrailerGeometricDataIndex_WheelBaseAxle18ToAxle19" 27 "TrailerGeometricDataIndex_WheelBaseAxle17ToAxle18" 26 "TrailerGeometricDataIndex_WheelBaseAxle16ToAxle17" 25 "TrailerGeometricDataIndex_WheelBaseAxle15ToAxle16" 24 "TrailerGeometricDataIndex_WheelBaseAxle14ToAxle15" 23 "TrailerGeometricDataIndex_WheelBaseAxle13ToAxle14" 22 "TrailerGeometricDataIndex_WheelBaseAxle12ToAxle13" 21 "TrailerGeometricDataIndex_WheelBaseAxle11ToAxle12" 20 "TrailerGeometricDataIndex_WheelBaseAxle10ToAxle11" 19 "TrailerGeometricDataIndex_WheelBaseAxle9ToAxle10" 18 "TrailerGeometricDataIndex_WheelBaseAxle8ToAxle9" 17 "TrailerGeometricDataIndex_WheelBaseAxle7ToAxle8" 16 "TrailerGeometricDataIndex_WheelBaseAxle6ToAxle7" 15 "TrailerGeometricDataIndex_WheelBaseAxle5ToAxle6" 14 "TrailerGeometricDataIndex_WheelBaseAxle4ToAxle5" 13 "TrailerGeometricDataIndex_WheelBaseAxle3ToAxle4" 12 "TrailerGeometricDataIndex_WheelBaseAxle2ToAxle3" 11 "TrailerGeometricDataIndex_WheelBaseAxle1ToAxle2" 10 "TrailerGeometricDataIndex_AxleNumberOfLiftAxle5" 9 "TrailerGeometricDataIndex_AxleNumberOfLiftAxle4" 8 "TrailerGeometricDataIndex_AxleNumberOfLiftAxle3" 7 "TrailerGeometricDataIndex_AxleNumberOfLiftAxle2" 6 "TrailerGeometricDataIndex_AxleNumberOfLiftAxle1" 5 "TrailerGeometricDataIndex_NumberOfLiftAxles" 4 "TrailerGeometricDataIndex_NumberOfFrontAxles" 3 "TrailerGeometricDataIndex_NumberOfAxles" 2 "TrailerGeometricDataIndex_TrackWidth" 1 "TrailerGeometricDataIndex_DistanceCouplingToAxle1" 0 "TrailerGeometricDataIndex_TypeOfTrailer" ;
VAL_ 2566902027 Trailer2GeometricData_Index 255 "TrailerGeometricDataIndex_NotAvailable" 254 "TrailerGeometricDataIndex_Error" 38 "TrailerGeometricDataIndex_TrailerHeightRear" 37 "TrailerGeometricDataIndex_ChassisHeight" 36 "TrailerGeometricDataIndex_TrailerHeightFront" 35 "TrailerGeometricDataIndex_LoadingHeightFront" 34 "TrailerGeometricDataIndex_LoadingHeightRear" 33 "TrailerGeometricDataIndex_CouplingHeight2" 32 "TrailerGeometricDataIndex_CouplingHeight1" 31 "TrailerGeometricDataIndex_TotalLengthOfTrailer" 30 "TrailerGeometricDataIndex_DistanceFirstToSecondCouplingPoint" 29 "TrailerGeometricDataIndex_WheelBaseAxle19ToAxle20" 28 "TrailerGeometricDataIndex_WheelBaseAxle18ToAxle19" 27 "TrailerGeometricDataIndex_WheelBaseAxle17ToAxle18" 26 "TrailerGeometricDataIndex_WheelBaseAxle16ToAxle17" 25 "TrailerGeometricDataIndex_WheelBaseAxle15ToAxle16" 24 "TrailerGeometricDataIndex_WheelBaseAxle14ToAxle15" 23 "TrailerGeometricDataIndex_WheelBaseAxle13ToAxle14" 22 "TrailerGeometricDataIndex_WheelBaseAxle12ToAxle13" 21 "TrailerGeometricDataIndex_WheelBaseAxle11ToAxle12" 20 "TrailerGeometricDataIndex_WheelBaseAxle10ToAxle11" 19 "TrailerGeometricDataIndex_WheelBaseAxle9ToAxle10" 18 "TrailerGeometricDataIndex_WheelBaseAxle8ToAxle9" 17 "TrailerGeometricDataIndex_WheelBaseAxle7ToAxle8" 16 "TrailerGeometricDataIndex_WheelBaseAxle6ToAxle7" 15 "TrailerGeometricDataIndex_WheelBaseAxle5ToAxle6" 14 "TrailerGeometricDataIndex_WheelBaseAxle4ToAxle5" 13 "TrailerGeometricDataIndex_WheelBaseAxle3ToAxle4" 12 "TrailerGeometricDataIndex_WheelBaseAxle2ToAxle3" 11 "TrailerGeometricDataIndex_WheelBaseAxle1ToAxle2" 10 "TrailerGeometricDataIndex_AxleNumberOfLiftAxle5" 9 "TrailerGeometricDataIndex_AxleNumberOfLiftAxle4" 8 "TrailerGeometricDataIndex_AxleNumberOfLiftAxle3" 7 "TrailerGeometricDataIndex_AxleNumberOfLiftAxle2" 6 "TrailerGeometricDataIndex_AxleNumberOfLiftAxle1" 5 "TrailerGeometricDataIndex_NumberOfLiftAxles" 4 "TrailerGeometricDataIndex_NumberOfFrontAxles" 3 "TrailerGeometricDataIndex_NumberOfAxles" 2 "TrailerGeometricDataIndex_TrackWidth" 1 "TrailerGeometricDataIndex_DistanceCouplingToAxle1" 0 "TrailerGeometricDataIndex_TypeOfTrailer" ;
VAL_ 2566902027 Trailer1GeometricData_Index 255 "TrailerGeometricDataIndex_NotAvailable" 254 "TrailerGeometricDataIndex_Error" 38 "TrailerGeometricDataIndex_TrailerHeightRear" 37 "TrailerGeometricDataIndex_ChassisHeight" 36 "TrailerGeometricDataIndex_TrailerHeightFront" 35 "TrailerGeometricDataIndex_LoadingHeightFront" 34 "TrailerGeometricDataIndex_LoadingHeightRear" 33 "TrailerGeometricDataIndex_CouplingHeight2" 32 "TrailerGeometricDataIndex_CouplingHeight1" 31 "TrailerGeometricDataIndex_TotalLengthOfTrailer" 30 "TrailerGeometricDataIndex_DistanceFirstToSecondCouplingPoint" 29 "TrailerGeometricDataIndex_WheelBaseAxle19ToAxle20" 28 "TrailerGeometricDataIndex_WheelBaseAxle18ToAxle19" 27 "TrailerGeometricDataIndex_WheelBaseAxle17ToAxle18" 26 "TrailerGeometricDataIndex_WheelBaseAxle16ToAxle17" 25 "TrailerGeometricDataIndex_WheelBaseAxle15ToAxle16" 24 "TrailerGeometricDataIndex_WheelBaseAxle14ToAxle15" 23 "TrailerGeometricDataIndex_WheelBaseAxle13ToAxle14" 22 "TrailerGeometricDataIndex_WheelBaseAxle12ToAxle13" 21 "TrailerGeometricDataIndex_WheelBaseAxle11ToAxle12" 20 "TrailerGeometricDataIndex_WheelBaseAxle10ToAxle11" 19 "TrailerGeometricDataIndex_WheelBaseAxle9ToAxle10" 18 "TrailerGeometricDataIndex_WheelBaseAxle8ToAxle9" 17 "TrailerGeometricDataIndex_WheelBaseAxle7ToAxle8" 16 "TrailerGeometricDataIndex_WheelBaseAxle6ToAxle7" 15 "TrailerGeometricDataIndex_WheelBaseAxle5ToAxle6" 14 "TrailerGeometricDataIndex_WheelBaseAxle4ToAxle5" 13 "TrailerGeometricDataIndex_WheelBaseAxle3ToAxle4" 12 "TrailerGeometricDataIndex_WheelBaseAxle2ToAxle3" 11 "TrailerGeometricDataIndex_WheelBaseAxle1ToAxle2" 10 "TrailerGeometricDataIndex_AxleNumberOfLiftAxle5" 9 "TrailerGeometricDataIndex_AxleNumberOfLiftAxle4" 8 "TrailerGeometricDataIndex_AxleNumberOfLiftAxle3" 7 "TrailerGeometricDataIndex_AxleNumberOfLiftAxle2" 6 "TrailerGeometricDataIndex_AxleNumberOfLiftAxle1" 5 "TrailerGeometricDataIndex_NumberOfLiftAxles" 4 "TrailerGeometricDataIndex_NumberOfFrontAxles" 3 "TrailerGeometricDataIndex_NumberOfAxles" 2 "TrailerGeometricDataIndex_TrackWidth" 1 "TrailerGeometricDataIndex_DistanceCouplingToAxle1" 0 "TrailerGeometricDataIndex_TypeOfTrailer" ;
VAL_ 2566886667 Trailer5LiftAxle1Pos 3 "TrailerLiftAxlePos_NotAvailable" 2 "TrailerLiftAxlePos_Error" 1 "TrailerLiftAxlePos_AxleLifted" 0 "TrailerLiftAxlePos_AxleDown" ;
VAL_ 2566886667 Trailer5LiftAxle2Pos 3 "TrailerLiftAxlePos_NotAvailable" 2 "TrailerLiftAxlePos_Error" 1 "TrailerLiftAxlePos_AxleLifted" 0 "TrailerLiftAxlePos_AxleDown" ;
VAL_ 2566886155 Trailer4LiftAxle2Pos 3 "TrailerLiftAxlePos_NotAvailable" 2 "TrailerLiftAxlePos_Error" 1 "TrailerLiftAxlePos_AxleLifted" 0 "TrailerLiftAxlePos_AxleDown" ;
VAL_ 2566886155 Trailer4LiftAxle1Pos 3 "TrailerLiftAxlePos_NotAvailable" 2 "TrailerLiftAxlePos_Error" 1 "TrailerLiftAxlePos_AxleLifted" 0 "TrailerLiftAxlePos_AxleDown" ;
VAL_ 2566886155 Trailer3LiftAxle1Pos 3 "TrailerLiftAxlePos_NotAvailable" 2 "TrailerLiftAxlePos_Error" 1 "TrailerLiftAxlePos_AxleLifted" 0 "TrailerLiftAxlePos_AxleDown" ;
VAL_ 2566886155 Trailer3LiftAxle2Pos 3 "TrailerLiftAxlePos_NotAvailable" 2 "TrailerLiftAxlePos_Error" 1 "TrailerLiftAxlePos_AxleLifted" 0 "TrailerLiftAxlePos_AxleDown" ;
VAL_ 2566885643 Trailer2LiftAxle2Pos 3 "TrailerLiftAxlePos_NotAvailable" 2 "TrailerLiftAxlePos_Error" 1 "TrailerLiftAxlePos_AxleLifted" 0 "TrailerLiftAxlePos_AxleDown" ;
VAL_ 2566885643 Trailer2LiftAxle1Pos 3 "TrailerLiftAxlePos_NotAvailable" 2 "TrailerLiftAxlePos_Error" 1 "TrailerLiftAxlePos_AxleLifted" 0 "TrailerLiftAxlePos_AxleDown" ;
VAL_ 2566885643 TrailerEBSFault 3 "OkNok_NotAvailable" 2 "OkNok_Error" 1 "OkNok_NotOK" 0 "OkNok_OK" ;
VAL_ 2499761675 RearAxleDiffLockActvnFuncReq 3 "RearAxleDiffLockActvnFuncReq_TakeNoAction" 2 "RearAxleDiffLockActvnFuncReq_Reserved" 1 "RearAxleDiffLockActvnFuncReq_DisengageDifferentialLock" 0 "RearAxleDiffLockActvnFuncReq_EngageDifferentialLock" ;
VAL_ 2499761675 PoorBrakePerformanceWarning 3 "Warning_NotAvailable" 2 "Warning_Error" 1 "Warning_Warning" 0 "Warning_NoWarning" ;
VAL_ 2499761675 TrcnCtrlSlipperyRoadWarning 3 "InactiveActive_NotAvailable" 2 "InactiveActive_Error" 1 "InactiveActive_Active" 0 "InactiveActive_Inactive" ;
VAL_ 2499761675 DTCActive 3 "DTCActive_DTCStatusInfoNotAvailableOrNotSupported" 2 "DTCActive_ErrorIndicator" 1 "DTCActive_DTCActive" 0 "DTCActive_DTCStatusInfoAvailableButNotActive" ;
VAL_ 2499761675 AutoRearAxleDiffLockFnc_stat 3 "InactiveActive_NotAvailable" 2 "InactiveActive_Error" 1 "InactiveActive_Active" 0 "InactiveActive_Inactive" ;
VAL_ 2499761675 TractionFunctionSelected 7 "TractionFunctionSelected_NotAvailable" 6 "TractionFunctionSelected_Error" 5 "TractionFunctionSelected_Spare_02" 4 "TractionFunctionSelected_Spare_01" 3 "TractionFunctionSelected_Spare" 2 "TractionFunctionSelected_TractionOFFROAD" 1 "TractionFunctionSelected_TractionOFF" 0 "TractionFunctionSelected_TractionON" ;
VAL_ 2499761675 ABSInhibitionStatus 3 "Inhibit_NotAvailable" 2 "Inhibit_Error" 1 "Inhibit_InhibitActive" 0 "Inhibit_NoInhibit" ;
VAL_ 2499761675 ABSManAutoInhibitionStat 7 "ABSManAutoInhibitionStat_NotAvailable" 6 "ABSManAutoInhibitionStat_Error" 5 "ABSManAutoInhibitionStat_Spare02" 4 "ABSManAutoInhibitionStat_Spare01" 3 "ABSManAutoInhibitionStat_Spare" 2 "ABSManAutoInhibitionStat_ABSAutomaticInhibition" 1 "ABSManAutoInhibitionStat_ABSManualInhibition" 0 "ABSManAutoInhibitionStat_ABSNoInhibition" ;
VAL_ 2499761675 VDCActive 3 "VDCActive_NotAvailableOrNotInstalled" 2 "VDCActive_ErrorIndicator" 1 "VDCActive_VDCActive" 0 "VDCActive_VDCPassiveButInstalled" ;
VAL_ 2499761675 RearAxleSteeringFunctionStatus 7 "RearAxleSteeringFunctionStatus_NotAvailable" 6 "RearAxleSteeringFunctionStatus_Error" 5 "RearAxleSteeringFunctionStatus_SpareValue_01" 4 "RearAxleSteeringFunctionStatus_SpareValue" 3 "RearAxleSteeringFunctionStatus_ActiveFailureMode" 2 "RearAxleSteeringFunctionStatus_PassiveFailureMode" 1 "RearAxleSteeringFunctionStatus_Active" 0 "RearAxleSteeringFunctionStatus_NotActive" ;
VAL_ 2499761675 HSAAvailability 3 "NotAvailable_NotAvailable" 2 "NotAvailable_Error" 1 "NotAvailable_FunctionAvailable" 0 "NotAvailable_FunctionNotAvailable" ;
VAL_ 2499761675 RollerBenchModeStatus 3 "InactiveActive_NotAvailable" 2 "InactiveActive_Error" 1 "InactiveActive_Active" 0 "InactiveActive_Inactive" ;
VAL_ 2499761675 BrakeAssistStatus 3 "OffOn_NotAvailable" 2 "OffOn_Error" 1 "OffOn_On" 0 "OffOn_Off" ;
VAL_ 2499750411 XBRSystemInformation 7 "XBRSystemInformation_NotAvailable" 6 "XBRSystemInformation_Spare03" 5 "XBRSystemInformation_Spare02" 4 "XBRSystemInformation_OnlyEBIOrHighestPriorityAccepted" 3 "XBRSystemInformation_ExternalBrakeDemandExecutionNotPossible" 2 "XBRSystemInformation_NoEBIAndOnlyHighestPriorityIsAccepted" 1 "XBRSystemInformation_NoEBIButElseFullyOperational" 0 "XBRSystemInformation_AnyBrakeRequestWillBeAccepted" ;
VAL_ 2499750411 BrakePedalTestState 15 "BrakePedalTestState_NotAvailable" 14 "BrakePedalTestState_Error" 13 "BrakePedalTestState_Spare_06" 12 "BrakePedalTestState_Spare_05" 11 "BrakePedalTestState_Spare_04" 10 "BrakePedalTestState_Spare_03" 9 "BrakePedalTestState_Spare_02" 8 "BrakePedalTestState_Spare_01" 7 "BrakePedalTestState_Spare" 6 "BrakePedalTestState_TestInterrIncorrOpByDrAtLeastOneActFault" 5 "BrakePedalTestState_TestWasCorrectlyOpByDrAtLeastOneActFault" 4 "BrakePedalTestState_TestWasCorrectlyOperatedByDrFaultDeleted" 3 "BrakePedalTestState_BrakePedalReleaseIsNeeded" 2 "BrakePedalTestState_FullBrakePedalActuationIsNeeded" 1 "BrakePedalTestState_TestIsNeededKeepBrakePedalReleased" 0 "BrakePedalTestState_BrakePedalTestIsNotNeeded" ;
VAL_ 2499750411 HillStartAidStatus 7 "HillStartAidStatus_NotAvailable" 6 "HillStartAidStatus_Error" 5 "HillStartAidStatus_NotDefined2" 4 "HillStartAidStatus_ActiveWithWarningHigh" 3 "HillStartAidStatus_ActiveWithWarningLow" 2 "HillStartAidStatus_ActiveButWillChangeToInactiveInAShortTime" 1 "HillStartAidStatus_Active" 0 "HillStartAidStatus_Inactive" ;
VAL_ 2499750411 SasAdaptationInProgress 3 "OffOn_NotAvailable" 2 "OffOn_Error" 1 "OffOn_On" 0 "OffOn_Off" ;
VAL_ 2499750411 ESCStatus 7 "ESCStatus_NotAvailable" 6 "ESCStatus_Error" 5 "ESCStatus_PartlyMalfunctioning" 4 "ESCStatus_FullyMalfunctioning" 3 "ESCStatus_ESCOn" 2 "ESCStatus_Spare3" 1 "ESCStatus_ESCReduced" 0 "ESCStatus_ESCOff" ;
VAL_ 2499750411 HillHolderMode 7 "HillHolderMode_NotAvailable" 6 "HillHolderMode_Reserved" 5 "HillHolderMode_Spare2" 4 "HillHolderMode_Spare1" 3 "HillHolderMode_OnHold_PressureApplied" 2 "HillHolderMode_Active_WillChangeToInactiveSoon" 1 "HillHolderMode_Active" 0 "HillHolderMode_Inactive" ;
VAL_ 2499750411 ESCState 7 "ESCState_NotAvailable" 6 "ESCState_Error" 5 "ESCState_Spare03" 4 "ESCState_Spare02" 3 "ESCState_Spare01" 2 "ESCState_Reduced" 1 "ESCState_On" 0 "ESCState_Off" ;
VAL_ 2499750411 ABSOffRoadStatus 3 "OffOn_NotAvailable" 2 "OffOn_Error" 1 "OffOn_On" 0 "OffOn_Off" ;
VAL_ 2566767627 BrakeTemperatureWarning 3 "Warning_NotAvailable" 2 "Warning_Error" 1 "Warning_Warning" 0 "Warning_NoWarning" ;
VAL_ 2566767627 FoundationBrakeUse 3 "FoundationBrakeUse_NotAvailable" 2 "FoundationBrakeUse_Reserved" 1 "FoundationBrakeUse_FoundationBrakesInUse" 0 "FoundationBrakeUse_FoundationBrakesNotInUse" ;
VAL_ 2566767627 XBRActiveControlMode 15 "XBRActiveControlMode_NotAvailable" 3 "XBRActiveControlMode_MaximumModeOfXBRAccelControlExecuted" 2 "XBRActiveControlMode_AdditionModeoXBRAccelControlExecuted" 1 "XBRActiveControlMode_DriversBrakeDemandExecNoExtBrakeDemand" 0 "XBRActiveControlMode_NoBrakeDemandBeingExecutedDefaultMode" ;
VAL_ 2566767627 XBRSystemState 3 "XBRSystemState_NotAvailable" 2 "XBRSystemState_NoExternalBrakeDemandAccepted" 1 "XBRSystemState_OnlyHighestXBRPriorityDemandAccepted" 0 "XBRSystemState_ExternalBrakeDemandAccepted" ;
VAL_ 2566767627 EPBHillHolderMode 7 "EPBHillHolderMode_NotAvailable" 6 "EPBHillHolderMode_Reserved" 5 "EPBHillHolderMode_NotDefined_02" 4 "EPBHillHolderMode_NotDefined_01" 3 "EPBHillHolderMode_NotDefined" 2 "EPBHillHolderMode_ActiveWillChngToInactiveInShortTime" 1 "EPBHillHolderMode_Active" 0 "EPBHillHolderMode_Inactive" ;
VAL_ 2565865739 ASREngineControlActive 3 "PassiveActive2_DontCareTakeNoAction" 2 "PassiveActive2_Reserved" 1 "PassiveActive2_Active" 0 "PassiveActive2_PassiveButInstalled" ;
VAL_ 2565865739 ASRBrakeControlActive 3 "PassiveActive2_DontCareTakeNoAction" 2 "PassiveActive2_Reserved" 1 "PassiveActive2_Active" 0 "PassiveActive2_PassiveButInstalled" ;
VAL_ 2565865739 ABSFullyOperational 3 "FullyOperational_NotAvailable" 2 "FullyOperational_Reserved" 1 "FullyOperational_FullyOperational" 0 "FullyOperational_NotFullyOperational" ;
VAL_ 2565865739 EBSRedWarningSignal 3 "OffOn_NotAvailable" 2 "OffOn_Error" 1 "OffOn_On" 0 "OffOn_Off" ;
VAL_ 2565865739 ABSEBSAmberWarningSignal 3 "OffOn_NotAvailable" 2 "OffOn_Error" 1 "OffOn_On" 0 "OffOn_Off" ;
VAL_ 2565865739 AntiLockBrakingActive 3 "AntiLockBrakingActive_NotAvailable" 2 "AntiLockBrakingActive_Reserved" 1 "AntiLockBrakingActive_ABSActive" 0 "AntiLockBrakingActive_ABSPassiveButInstalled" ;
VAL_ 2565865739 ASRHillHolderSwitch 3 "PassiveActive_NotAvailable" 2 "PassiveActive_Error" 1 "PassiveActive_Active" 0 "PassiveActive_Passive" ;
VAL_ 2566749184 DPFC1_InhibDueServiceBrake 3 "InhibitStatus_NotAvailable" 2 "InhibitStatus_Reserved" 1 "InhibitStatus_Inhibited" 0 "InhibitStatus_NotInhibited" ;
VAL_ 2566749184 DPFC1_InhibVehSpdBelowAllwdSpd 3 "InhibitStatus_NotAvailable" 2 "InhibitStatus_Reserved" 1 "InhibitStatus_Inhibited" 0 "InhibitStatus_NotInhibited" ;
VAL_ 2566749184 DPFC1_ActiveRegeneratStatus 3 "ActiveRegeneratStatus_NotAvailable" 2 "ActiveRegeneratStatus_RegenNeededAutoInitiatedActReg" 1 "ActiveRegeneratStatus_Active" 0 "ActiveRegeneratStatus_NotActive" ;
VAL_ 2566749184 DPFC1_ExhaustSystHighTempLampCmd 7 "ExhaustSystHighTempLampCmd_NotAvailable" 6 "ExhaustSystHighTempLampCmd_Reserved_04" 5 "ExhaustSystHighTempLampCmd_Reserved_03" 4 "ExhaustSystHighTempLampCmd_Reserved_02" 3 "ExhaustSystHighTempLampCmd_Reserved_01" 2 "ExhaustSystHighTempLampCmd_Reserved" 1 "ExhaustSystHighTempLampCmd_On" 0 "ExhaustSystHighTempLampCmd_Off" ;
VAL_ 2566749184 DPFC1_InhibParkBrakeNotSet 3 "InhibitStatus_NotAvailable" 2 "InhibitStatus_Reserved" 1 "InhibitStatus_Inhibited" 0 "InhibitStatus_NotInhibited" ;
VAL_ 2566749184 DPFC1_InhibEnginNotWarmUp 3 "InhibitStatus_NotAvailable" 2 "InhibitStatus_Reserved" 1 "InhibitStatus_Inhibited" 0 "InhibitStatus_NotInhibited" ;
VAL_ 2566749184 DPFC1_InhibitStatus 3 "InhibitStatus_NotAvailable" 2 "InhibitStatus_Reserved" 1 "InhibitStatus_Inhibited" 0 "InhibitStatus_NotInhibited" ;
VAL_ 2566749184 DPFC1_ForcedStatus 7 "ForcedStatus_NotAvailable" 6 "ForcedStatus_Reserved_03" 5 "ForcedStatus_Reserved_02" 4 "ForcedStatus_Reserved_01" 3 "ForcedStatus_Reserved" 2 "ForcedStatus_ActiveForcedByServiceTool" 1 "ForcedStatus_ActiveForcedBySwitch" 0 "ForcedStatus_NotActive" ;
VAL_ 2566749184 DPFC1_PassiveRegenStatus 3 "InactiveActive_NotAvailable" 2 "InactiveActive_Error" 1 "InactiveActive_Active" 0 "InactiveActive_Inactive" ;
VAL_ 2566749184 DPFC1_InhibTempSystemLock 3 "InhibitStatus_NotAvailable" 2 "InhibitStatus_Reserved" 1 "InhibitStatus_Inhibited" 0 "InhibitStatus_NotInhibited" ;
VAL_ 2566749184 DPFC1_InhibDueInhibSwitch 3 "InhibitStatus_NotAvailable" 2 "InhibitStatus_Reserved" 1 "InhibitStatus_Inhibited" 0 "InhibitStatus_NotInhibited" ;
VAL_ 2566749184 DPFC1_InhibPTOActive 3 "InhibitStatus_NotAvailable" 2 "InhibitStatus_Reserved" 1 "InhibitStatus_Inhibited" 0 "InhibitStatus_NotInhibited" ;
VAL_ 2566749184 DPFC1_AutoARInitConfig 3 "AutoARInitConfig_NotAvailable" 2 "AutoARInitConfig_Reserved" 1 "AutoARInitConfig_Enabled" 0 "AutoARInitConfig_NotEnabled" ;
VAL_ 2566749184 DPFC1_InhibDueLowExhGasTemp 3 "InhibitStatus_NotAvailable" 2 "InhibitStatus_Reserved" 1 "InhibitStatus_Inhibited" 0 "InhibitStatus_NotInhibited" ;
VAL_ 2566749184 DPFC1_InhibSystemFaultAct 3 "InhibitStatus_NotAvailable" 2 "InhibitStatus_Reserved" 1 "InhibitStatus_Inhibited" 0 "InhibitStatus_NotInhibited" ;
VAL_ 2566749184 DPFC1_InhibDueSystemTimeout 3 "InhibitStatus_NotAvailable" 2 "InhibitStatus_Reserved" 1 "InhibitStatus_Inhibited" 0 "InhibitStatus_NotInhibited" ;
VAL_ 2566749184 DPFC1_InhibPermSystemLock 3 "InhibitStatus_NotAvailable" 2 "InhibitStatus_Reserved" 1 "InhibitStatus_Inhibited" 0 "InhibitStatus_NotInhibited" ;
VAL_ 2566749184 DPFC1_LampCommand 7 "LampCommand_NotAvailable" 6 "LampCommand_Reserved_03" 5 "LampCommand_Reserved_02" 4 "LampCommand_OnFastBlink1Hz" 3 "LampCommand_Reserved_01" 2 "LampCommand_Reserved" 1 "LampCommand_OnSolid" 0 "LampCommand_Off" ;
VAL_ 2566749184 DPFC1_InhibVehSpdAboveAllwdSpd 3 "InhibitStatus_NotAvailable" 2 "InhibitStatus_Reserved" 1 "InhibitStatus_Inhibited" 0 "InhibitStatus_NotInhibited" ;
VAL_ 2566749184 DPFC1_InhibClutchDisengage 3 "InhibitStatus_NotAvailable" 2 "InhibitStatus_Reserved" 1 "InhibitStatus_Inhibited" 0 "InhibitStatus_NotInhibited" ;
VAL_ 2566749184 DPFC1_InhibAccPedalOffIdle 3 "InhibitStatus_NotAvailable" 2 "InhibitStatus_Reserved" 1 "InhibitStatus_Inhibited" 0 "InhibitStatus_NotInhibited" ;
VAL_ 2566749184 DPFC1_InhibOutOfNeutral 3 "InhibitStatus_NotAvailable" 2 "InhibitStatus_Reserved" 1 "InhibitStatus_Inhibited" 0 "InhibitStatus_NotInhibited" ;
VAL_ 2566749184 DPFC1_DPFStatus 7 "DPFStatus_NotAvailable" 6 "DPFStatus_Reserved_02" 5 "DPFStatus_Reserved_01" 4 "DPFStatus_Reserved" 3 "DPFStatus_RegenerationNeededHighestLevel" 2 "DPFStatus_RegenerationNeededModerateLevel" 1 "DPFStatus_RegenerationNeededLowestLevel" 0 "DPFStatus_RegenerationNotNeeded" ;
VAL_ 2499757105 HSADriverRequest 3 "InactiveActive_NotAvailable" 2 "InactiveActive_Error" 1 "InactiveActive_Active" 0 "InactiveActive_Inactive" ;
VAL_ 2499757105 ESCDriverReq 7 "ESCDriverReq_NotAvailable" 6 "ESCDriverReq_Error" 5 "ESCDriverReq_Spare02" 4 "ESCDriverReq_Spare01" 3 "ESCDriverReq_ESCOn" 2 "ESCDriverReq_ESCReduced" 1 "ESCDriverReq_ESCOff" 0 "ESCDriverReq_NoRequest" ;
VAL_ 2499757105 RrRrItrWhlDiffLckActvnDrvrReq 3 "DisengagedEngaged_NotAvailable" 2 "DisengagedEngaged_Error" 1 "DisengagedEngaged_Engaged" 0 "DisengagedEngaged_Disengaged" ;
VAL_ 2499757105 AutRrAxleDiffLockActvnDrvrReq 3 "DisengageEngage_NotAvailable" 2 "DisengageEngage_Error" 1 "DisengageEngage_Engage" 0 "DisengageEngage_Disengage" ;
VAL_ 2499757105 ABSModeRequest 7 "ABSModeRequest_NotAvailable" 6 "ABSModeRequest_Error" 5 "ABSModeRequest_Spare3" 4 "ABSModeRequest_ABS_Inhibited" 3 "ABSModeRequest_Spare2" 2 "ABSModeRequest_ABS_OffRoad" 1 "ABSModeRequest_Spare1" 0 "ABSModeRequest_ABS_NormalMode" ;
VAL_ 2499757105 FrRrItrWhlDiffLckActvnDrvrReq 3 "DisengagedEngaged_NotAvailable" 2 "DisengagedEngaged_Error" 1 "DisengagedEngaged_Engaged" 0 "DisengagedEngaged_Disengaged" ;
VAL_ 2499757105 RearAxleSteeringFunctionDsbl 3 "RearAxleSteeringFunctionDsbl_NotAvailable" 2 "RearAxleSteeringFunctionDsbl_Error" 1 "RearAxleSteeringFunctionDsbl_DisableRequest" 0 "RearAxleSteeringFunctionDsbl_NoDisableRequest" ;
VAL_ 2499757105 RollerBenchModeRequest 3 "OffOn_NotAvailable" 2 "OffOn_Error" 1 "OffOn_On" 0 "OffOn_Off" ;
VAL_ 2499757105 RearAxleDiffLockActvnDrvrReq 3 "DisengageEngage_NotAvailable" 2 "DisengageEngage_Error" 1 "DisengageEngage_Engage" 0 "DisengageEngage_Disengage" ;
VAL_ 2499757105 SplitBoxDifflockActvnDrvrRqst 3 "DisengageEngage_NotAvailable" 2 "DisengageEngage_Error" 1 "DisengageEngage_Engage" 0 "DisengageEngage_Disengage" ;
VAL_ 2499757105 TractionControlDriverRqst 7 "TractionControlDriverRqst_NotAvailable" 6 "TractionControlDriverRqst_Error" 5 "TractionControlDriverRqst_Spare_01" 4 "TractionControlDriverRqst_Spare" 3 "TractionControlDriverRqst_TractionOFFROAD" 2 "TractionControlDriverRqst_TractionOFF" 1 "TractionControlDriverRqst_TractionON" 0 "TractionControlDriverRqst_NoAction" ;
VAL_ 2499757105 RrInterAxlDiffLockActvnDrvrReq 3 "DisengageEngage_NotAvailable" 2 "DisengageEngage_Error" 1 "DisengageEngage_Engage" 0 "DisengageEngage_Disengage" ;
VAL_ 2499757105 ABSInhibitionRequest 3 "OffOn_NotAvailable" 2 "OffOn_Error" 1 "OffOn_On" 0 "OffOn_Off" ;
VAL_ 2566844689 CCActive 3 "OffOn_NotAvailable" 2 "OffOn_Error" 1 "OffOn_On" 0 "OffOn_Off" ;
VAL_ 2566844689 ClutchSwitch 3 "ClutchSwitch_NotAvailable" 2 "ClutchSwitch_Error" 1 "ClutchSwitch_ClutchPedalDepressed" 0 "ClutchSwitch_ClutchPedalReleased" ;
VAL_ 2566844689 BrakeSwitch 3 "BrakeSwitch_NotAvailable" 2 "BrakeSwitch_Error" 1 "BrakeSwitch_BrakePedalDepressed" 0 "BrakeSwitch_BrakePedalReleased" ;
VAL_ 2566892605 LNGRestrictionStatus_V1Closed 1 "InactiveActive1b_Active" 0 "InactiveActive1b_Inactive" ;
VAL_ 2566892605 LNGRestrictionStatus_Spare4 1 "InactiveActive1b_Active" 0 "InactiveActive1b_Inactive" ;
VAL_ 2566892605 LNGRestrictionStatus_Spare2 1 "InactiveActive1b_Active" 0 "InactiveActive1b_Inactive" ;
VAL_ 2566892605 LNGRestrictionStatus_SInfo 3 "SignalInfo2bitType_NotAvailable" 2 "SignalInfo2bitType_ErrorIndication" 1 "SignalInfo2bitType_Spare" 0 "SignalInfo2bitType_Valid" ;
VAL_ 2566892605 LNGRestrictionStatus_Spare3 1 "InactiveActive1b_Active" 0 "InactiveActive1b_Inactive" ;
VAL_ 2566892605 LNGRestrictionStatus_Spare1 1 "InactiveActive1b_Active" 0 "InactiveActive1b_Inactive" ;
VAL_ 2566892605 LNGRestrictionStatus_V2Closed 1 "InactiveActive1b_Active" 0 "InactiveActive1b_Inactive" ;
VAL_ 2566892093 LngSystemReadinessStat 7 "LngSystemReadinessStat_NotAvailable" 6 "LngSystemReadinessStat_Error" 5 "LngSystemReadinessStat_Spare2" 4 "LngSystemReadinessStat_Spare1" 3 "LngSystemReadinessStat_LNGSystemReady" 2 "LngSystemReadinessStat_LNGInLimpingMode" 1 "LngSystemReadinessStat_LNGSystemWarmingUpPleaseWait" 0 "LngSystemReadinessStat_LNGSystemOff" ;
VAL_ 2566892093 MIStatusACM 3 "OffOn_NotAvailable" 2 "OffOn_Error" 1 "OffOn_On" 0 "OffOn_Off" ;
VAL_ 2566892093 LngTank1WarnStat 3 "OkEmpty_NotAvailable" 2 "OkEmpty_Error" 1 "OkEmpty_Empty" 0 "OkEmpty_OK" ;
VAL_ 2566892093 LngTank2WarnStat 3 "OkEmpty_NotAvailable" 2 "OkEmpty_Error" 1 "OkEmpty_Empty" 0 "OkEmpty_OK" ;
VAL_ 2566892093 CatalystTankLevelLow 3 "Warning_NotAvailable" 2 "Warning_Error" 1 "Warning_Warning" 0 "Warning_NoWarning" ;
VAL_ 2566892093 LngGspWarnStat 3 "OkPrepareToDerate_NotAvailable" 2 "OkPrepareToDerate_Error" 1 "OkPrepareToDerate_PrepareToDerate" 0 "OkPrepareToDerate_Ok" ;
VAL_ 2566892093 MIDistinctWarningACM 3 "OffOn_NotAvailable" 2 "OffOn_Error" 1 "OffOn_On" 0 "OffOn_Off" ;
VAL_ 2566892093 MIDistinctWarningExtACM 15 "MIDistinctWarningExt_NotAvailable" 14 "MIDistinctWarningExt_Error" 3 "MIDistinctWarningExt_ContinuousMISteady" 2 "MIDistinctWarningExt_ShortMI3Flash" 1 "MIDistinctWarningExt_OnDemandMI2Flash" 0 "MIDistinctWarningExt_Off1Flash" ;
VAL_ 2566892093 MIStatusExtACM 3 "MIStatusExt_NotAvailable" 2 "MIStatusExt_Error" 1 "MIStatusExt_Ready" 0 "MIStatusExt_NotReady5Flash" ;
SIG_GROUP_ 2566877707 Trailer2BrkLining_sg 1 : Trailer2BrkLining_Warning Trailer2BrkLining_Wear Trailer2BrkLining_BrkLnTireId;
SIG_GROUP_ 2566877707 Trailer2RampLevel_sg 1 : Trailer2RampLevel_LvlPos Trailer2RampLevel_LvlStatus;
SIG_GROUP_ 2566877707 Trailer2RelBodyLevel_sg 1 : Trailer2RelBodyLevel_RearLevel Trailer2RelBodyLevel_FrontLevel;
SIG_GROUP_ 2566877707 Trailer2NormalLevel_sg 1 : Trailer2NormalLevel_LvlPos Trailer2NormalLevel_LvlStatus;
SIG_GROUP_ 2566877451 Trailer1RampLevel_sg 1 : Trailer1RampLevel_LvlPos Trailer1RampLevel_LvlStatus;
SIG_GROUP_ 2566877451 Trailer1NormalLevel_sg 1 : Trailer1NormalLevel_LvlPos Trailer1NormalLevel_LvlStatus;
SIG_GROUP_ 2566877451 Trailer1RelBodyLevel_sg 1 : Trailer1RelBodyLevel_FrontLevel Trailer1RelBodyLevel_RearLevel;
SIG_GROUP_ 2566877451 Trailer1BrkLining_sg 1 : Trailer1BrkLining_BrkLnTireId Trailer1BrkLining_Wear Trailer1BrkLining_Warning;
SIG_GROUP_ 2566903051 Trailer5GeometricData_sg 1 : Trailer5GeometricData_Content Trailer5GeometricData_Index;
SIG_GROUP_ 2566902539 Trailer4GeometricData_sg 1 : Trailer4GeometricData_Content Trailer4GeometricData_Index;
SIG_GROUP_ 2566902539 Trailer3GeometricData_sg 1 : Trailer3GeometricData_Index Trailer3GeometricData_Content;
SIG_GROUP_ 2566902027 Trailer1GeometricData_sg 1 : Trailer1GeometricData_Content Trailer1GeometricData_Index;
SIG_GROUP_ 2566902027 Trailer2GeometricData_sg 1 : Trailer2GeometricData_Content Trailer2GeometricData_Index;
SIG_GROUP_ 2566886667 Trailer5AxleLoad_sg 1 : Trailer5AxleLoad_AxleLoad Trailer5AxleLoad_AxleId;
SIG_GROUP_ 2566886155 Trailer3AxleLoad_sg 1 : Trailer3AxleLoad_AxleLoad Trailer3AxleLoad_AxleId;
SIG_GROUP_ 2566886155 Trailer4AxleLoad_sg 1 : Trailer4AxleLoad_AxleLoad Trailer4AxleLoad_AxleId;
SIG_GROUP_ 2566885643 Trailer1AxleLoad_sg 1 : Trailer1AxleLoad_AxleLoad Trailer1AxleLoad_AxleId;
SIG_GROUP_ 2566885643 Trailer2AxleLoad_sg 1 : Trailer2AxleLoad_AxleLoad Trailer2AxleLoad_AxleId;
SIG_GROUP_ 2566907915 DiagFaultStat_Brake_sg 1 : DiagFaultStat_Brake_FailTA DiagFaultStat_Brake_DtcIdB DiagFaultStat_Brake_DtcIdA DiagFaultStat_Brake_EcuAdr DiagFaultStat_Brake_FailTB;
SIG_GROUP_ 2566907965 DiagFaultStat_ACM_sg 1 : DiagFaultStat_ACM_FailTB DiagFaultStat_ACM_FailTA DiagFaultStat_ACM_DtcIdB DiagFaultStat_ACM_DtcIdA DiagFaultStat_ACM_EcuAdr;
SIG_GROUP_ 2566749184 DPFC1_sg 1 : DPFC1_InhibDueServiceBrake DPFC1_InhibVehSpdBelowAllwdSpd DPFC1_ActiveRegeneratStatus DPFC1_ExhaustSystHighTempLampCmd DPFC1_InhibParkBrakeNotSet DPFC1_InhibEnginNotWarmUp DPFC1_InhibitStatus DPFC1_ForcedStatus DPFC1_PassiveRegenStatus DPFC1_InhibTempSystemLock DPFC1_InhibDueInhibSwitch DPFC1_InhibPTOActive DPFC1_AutoARInitConfig DPFC1_InhibDueLowExhGasTemp DPFC1_InhibSystemFaultAct DPFC1_InhibDueSystemTimeout DPFC1_InhibPermSystemLock DPFC1_LampCommand DPFC1_InhibVehSpdAboveAllwdSpd DPFC1_InhibClutchDisengage DPFC1_InhibAccPedalOffIdle DPFC1_InhibOutOfNeutral DPFC1_DPFStatus;
SIG_GROUP_ 2566892605 LNGRestrictionStatus_sg 1 : LNGRestrictionStatus_V1Closed LNGRestrictionStatus_Spare4 LNGRestrictionStatus_Spare2 LNGRestrictionStatus_SInfo LNGRestrictionStatus_Spare3 LNGRestrictionStatus_Spare1 LNGRestrictionStatus_V2Closed;
